VERSION ""

NS_ :

BS_:

BU_: HCM_FD IPMA_ADAS PSCM_FD ABS_ESC TCCM_FD TCM_DSL_FD PCM_HEV_FD PCM_FD ECM_Diesel GENERIC_GWMWakeup GWM_ECG _delete TSTR

BO_ 936 ParkAid_Data_FD1: 8 IPMA_ADAS
 SG_ ApaSys_D_Stat : 61|3@0+ (1,0) [0|7] "SED"  PSCM_FD,GWM_ECG,ECM_Diesel,PCM_FD,PCM_HEV_FD
 SG_ ApaSteWhl_D_RqDrv : 63|2@0+ (1,0) [0|3] "SED"  GWM_ECG
 SG_ ApaSteScanMde_D_Stat : 49|2@0+ (1,0) [0|3] "SED"  GWM_ECG
 SG_ ApaSelSapp_D_Stat : 51|2@0+ (1,0) [0|3] "SED"  GWM_ECG
 SG_ ApaSelPpa_D_Stat : 53|2@0+ (1,0) [0|3] "SED"  GWM_ECG
 SG_ ApaSelPoa_D_Stat : 55|2@0+ (1,0) [0|3] "SED"  GWM_ECG
 SG_ ApaScan_D_Stat : 41|2@0+ (1,0) [0|3] "SED"  GWM_ECG
 SG_ ApaLongCtl_D_RqDrv : 44|3@0+ (1,0) [0|7] "SED"  GWM_ECG
 SG_ ApaGearShif_D_RqDrv : 47|3@0+ (1,0) [0|7] "SED"  GWM_ECG
 SG_ ApaActvSide2_D_Stat : 33|2@0+ (1,0) [0|3] "SED"  GWM_ECG
 SG_ ApaAcsy_D_RqDrv : 36|3@0+ (1,0) [0|7] "SED"  GWM_ECG
 SG_ ApaTrgtDist_D_Stat : 11|4@0+ (1,0) [0|15] "SED"  GWM_ECG
 SG_ ApaMsgTxt_D_Rq : 15|4@0+ (1,0) [0|15] "SED"  GWM_ECG
 SG_ ApaChime_D_Rq : 39|3@0+ (1,0) [0|7] "SED"  GWM_ECG
 SG_ SAPPStatusCoding : 7|8@0+ (1,0) [0|255] "unitless"  GWM_ECG
 SG_ EPASExtAngleStatReq : 23|1@0+ (1,0) [0|1] "SED"  PSCM_FD,GWM_ECG,ABS_ESC
 SG_ ExtSteeringAngleReq2 : 22|15@0+ (0.1,-1000) [-1000|2276.5] "Degrees"  GWM_ECG,PSCM_FD

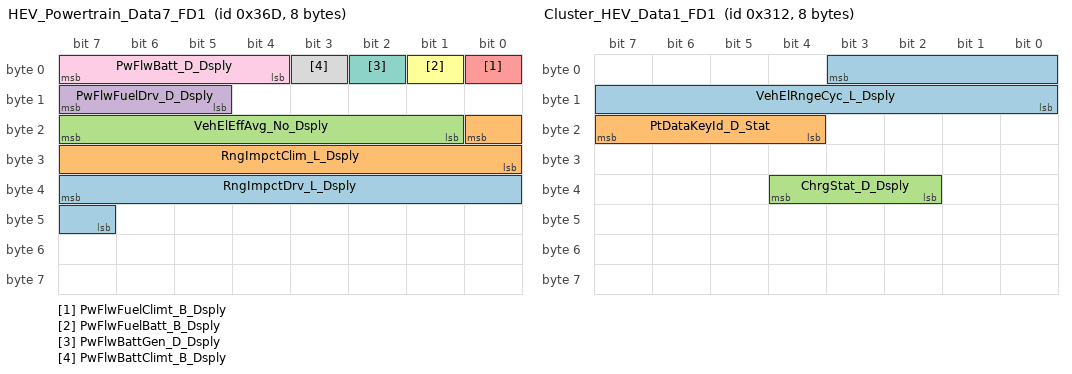
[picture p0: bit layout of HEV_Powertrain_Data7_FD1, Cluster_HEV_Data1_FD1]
BO_ 877 HEV_Powertrain_Data7_FD1: 8 PCM_HEV_FD
 SG_ RngImpctDrv_L_Dsply : 39|9@0+ (1,-255) [-255|256] "km"  GWM_ECG
 SG_ RngImpctClim_L_Dsply : 16|9@0+ (1,-255) [-255|256] "km"  GWM_ECG
 SG_ VehElEffAvg_No_Dsply : 23|7@0+ (10,-100) [-100|1150] "wattHr/km"  GWM_ECG
 SG_ PwFlwFuelDrv_D_Dsply : 15|3@0+ (1,0) [0|7] "SED"  GWM_ECG
 SG_ PwFlwFuelClimt_B_Dsply : 0|1@0+ (1,0) [0|1] "SED"  GWM_ECG
 SG_ PwFlwFuelBatt_B_Dsply : 1|1@0+ (1,0) [0|1] "SED"  GWM_ECG
 SG_ PwFlwBattGen_D_Dsply : 2|1@0+ (1,0) [0|1] "SED"  GWM_ECG
 SG_ PwFlwBattClimt_B_Dsply : 3|1@0+ (1,0) [0|1] "SED"  GWM_ECG
 SG_ PwFlwBatt_D_Dsply : 7|4@0+ (1,0) [0|15] "SED"  GWM_ECG

BO_ 786 Cluster_HEV_Data1_FD1: 8 GWM_ECG
 SG_ VehElRngeCyc_L_Dsply : 3|12@0+ (0.1,0) [0|409.3] "km" Vector__XXX
 SG_ PtDataKeyId_D_Stat : 23|4@0+ (1,0) [0|15] "SED" Vector__XXX
 SG_ ChrgStat_D_Dsply : 36|3@0+ (1,0) [0|7] "SED"  PCM_HEV_FD

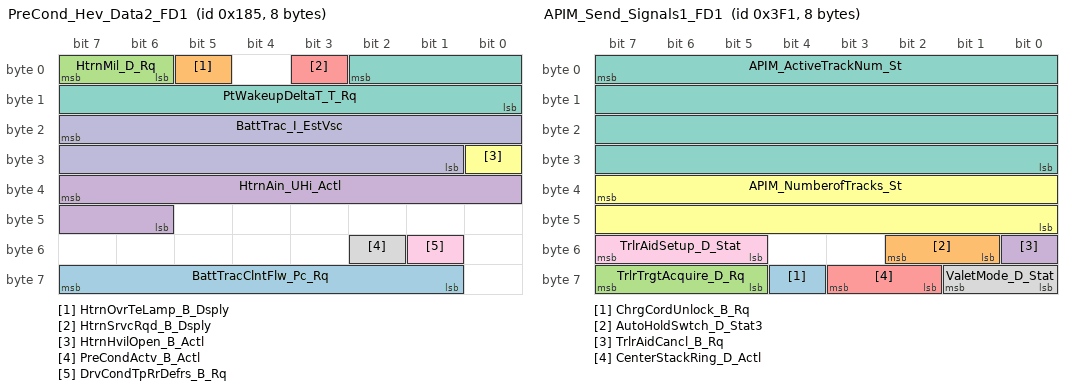
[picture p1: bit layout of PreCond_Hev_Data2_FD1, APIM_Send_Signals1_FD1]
BO_ 389 PreCond_Hev_Data2_FD1: 8 GWM_ECG
 SG_ BattTracClntFlw_Pc_Rq : 63|7@0+ (1,0) [0|127] "percent" Vector__XXX
 SG_ HtrnOvrTeLamp_B_Dsply : 5|1@0+ (1,0) [0|1] "SED" Vector__XXX
 SG_ HtrnMil_D_Rq : 7|2@0+ (1,0) [0|3] "SED" Vector__XXX
 SG_ HtrnAin_UHi_Actl : 39|10@0+ (0.5,0) [0|510.5] "volt"  PCM_HEV_FD
 SG_ HtrnSrvcRqd_B_Dsply : 3|1@0+ (1,0) [0|1] "SED" Vector__XXX
 SG_ HtrnHvilOpen_B_Actl : 24|1@0+ (1,0) [0|1] "SED"  PCM_HEV_FD
 SG_ PtWakeupDeltaT_T_Rq : 2|11@0+ (1,0) [0|2045] "minute" Vector__XXX
 SG_ PreCondActv_B_Actl : 50|1@0+ (1,0) [0|1] "SED" Vector__XXX
 SG_ DrvCondTpRrDefrs_B_Rq : 49|1@0+ (1,0) [0|1] "SED" Vector__XXX
 SG_ BattTrac_I_EstVsc : 23|15@0+ (0.05,-750) [-750|888.25] "Amps" Vector__XXX

BO_ 1009 APIM_Send_Signals1_FD1: 8 GWM_ECG
 SG_ ChrgCordUnlock_B_Rq : 60|1@0+ (1,0) [0|1] "SED" Vector__XXX
 SG_ AutoHoldSwtch_D_Stat3 : 50|2@0+ (1,0) [0|3] "SED" Vector__XXX
 SG_ TrlrTrgtAcquire_D_Rq : 63|3@0+ (1,0) [0|7] "SED"  IPMA_ADAS
 SG_ TrlrAidCancl_B_Rq : 48|1@0+ (1,0) [0|1] "SED"  IPMA_ADAS,PSCM_FD
 SG_ CenterStackRing_D_Actl : 59|2@0+ (1,0) [0|3] "SED" Vector__XXX
 SG_ APIM_NumberofTracks_St : 39|16@0+ (1,0) [0|65535] "unitless" Vector__XXX
 SG_ APIM_ActiveTrackNum_St : 7|32@0+ (1,0) [0|4294967295] "unitless" Vector__XXX
 SG_ ValetMode_D_Stat : 57|2@0+ (1,0) [0|3] "SED" Vector__XXX
 SG_ TrlrAidSetup_D_Stat : 55|3@0+ (1,0) [0|7] "SED" Vector__XXX

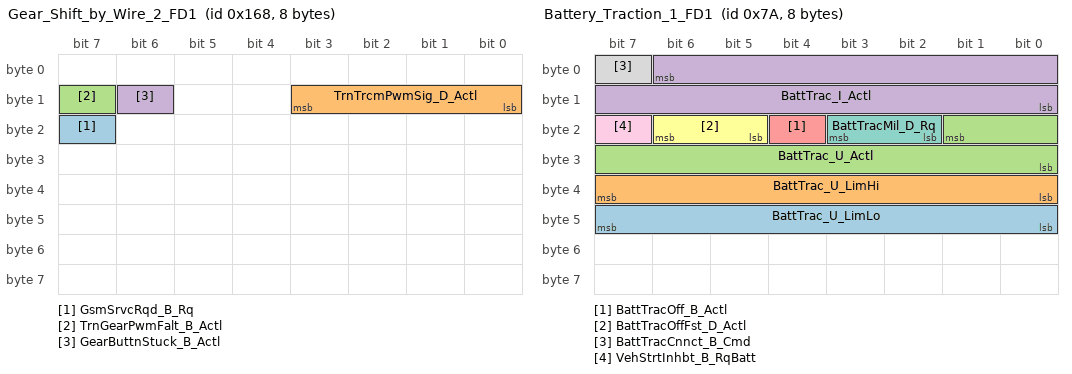
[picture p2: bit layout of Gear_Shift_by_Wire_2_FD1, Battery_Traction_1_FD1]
BO_ 360 Gear_Shift_by_Wire_2_FD1: 8 GWM_ECG
 SG_ GsmSrvcRqd_B_Rq : 23|1@0+ (1,0) [0|1] "SED" Vector__XXX
 SG_ TrnTrcmPwmSig_D_Actl : 11|4@0+ (1,0) [0|15] "SED" Vector__XXX
 SG_ TrnGearPwmFalt_B_Actl : 15|1@0+ (1,0) [0|1] "SED"  PCM_FD,PCM_HEV_FD
 SG_ GearButtnStuck_B_Actl : 14|1@0+ (1,0) [0|1] "SED"  PCM_FD,PCM_HEV_FD,TCM_DSL_FD

BO_ 122 Battery_Traction_1_FD1: 8 GWM_ECG
 SG_ BattTrac_U_LimLo : 47|8@0+ (2,0) [0|510] "volt"  PCM_HEV_FD
 SG_ BattTrac_U_LimHi : 39|8@0+ (2,0) [0|510] "volt"  PCM_HEV_FD
 SG_ BattTrac_U_Actl : 17|10@0+ (0.5,0) [0|510.5] "Volts"  PCM_HEV_FD
 SG_ BattTrac_I_Actl : 6|15@0+ (0.05,-750) [-750|888.25] "Amps"  PCM_HEV_FD
 SG_ BattTracOff_B_Actl : 20|1@0+ (1,0) [0|1] "SED"  PCM_HEV_FD
 SG_ BattTracOffFst_D_Actl : 22|2@0+ (1,0) [0|3] "SED"  PCM_HEV_FD
 SG_ BattTracMil_D_Rq : 19|2@0+ (1,0) [0|3] "SED" Vector__XXX
 SG_ BattTracCnnct_B_Cmd : 7|1@0+ (1,0) [0|1] "SED" Vector__XXX
 SG_ VehStrtInhbt_B_RqBatt : 23|1@0+ (1,0) [0|1] "SED"  PCM_HEV_FD

BO_ 90 Gear_Shift_by_Wire_FD1: 8 GWM_ECG
 SG_ TrnGsmNtmState_D_Actl : 55|2@0+ (1,0) [0|3] "SED"  ABS_ESC,PCM_FD,PCM_HEV_FD,TCM_DSL_FD
 SG_ DrQltyDrv_D_StatGsm : 42|3@0+ (1,0) [0|7] "SED"  ABS_ESC,PCM_FD,PCM_HEV_FD,TCM_DSL_FD,IPMA_ADAS
 SG_ TrnBtsiOvrrd_B_Stat : 43|1@0+ (1,0) [0|1] "SED"  PCM_FD,PCM_HEV_FD,TCM_DSL_FD
 SG_ GsmGearMsgTxt_D_Rq : 63|2@0+ (1,0) [0|3] "SED" Vector__XXX
 SG_ TrnRng_D_RqGsm : 51|4@0+ (1,0) [0|15] "SED"  PCM_FD,TCM_DSL_FD
 SG_ PrkBrkActv_D_RqGsmGear : 53|2@0+ (1,0) [0|3] "SED"  ABS_ESC
 SG_ TrnValidGearRq_D_Stat : 25|2@0+ (1,0) [0|3] "SED"  PCM_FD,PCM_HEV_FD,TCM_DSL_FD
 SG_ TrnGearRqCnt_B_Actl : 26|1@0+ (1,0) [0|1] "unitless"  PCM_FD,PCM_HEV_FD,TCM_DSL_FD
 SG_ TrnGearButtn_U_Actl : 23|8@0+ (0.05,0) [0|12.7] "VOLT"  TCM_DSL_FD
 SG_ TrnGearButtn_B_ActlR2 : 8|1@0+ (1,0) [0|1] "SED"  PCM_FD,PCM_HEV_FD,TCM_DSL_FD
 SG_ TrnGearButtn_B_ActlR1 : 9|1@0+ (1,0) [0|1] "SED"  PCM_FD,PCM_HEV_FD,TCM_DSL_FD
 SG_ TrnGearButtn_B_ActlR0 : 10|1@0+ (1,0) [0|1] "SED"  PCM_FD,PCM_HEV_FD,TCM_DSL_FD
 SG_ TrnGearButtn_B_ActlP2 : 11|1@0+ (1,0) [0|1] "SED"  TCM_DSL_FD,PCM_FD,PCM_HEV_FD
 SG_ TrnGearButtn_B_ActlP1 : 12|1@0+ (1,0) [0|1] "SED"  PCM_FD,PCM_HEV_FD,TCM_DSL_FD
 SG_ TrnGearButtn_B_ActlP0 : 13|1@0+ (1,0) [0|1] "SED"  PCM_FD,PCM_HEV_FD,TCM_DSL_FD
 SG_ TrnGearButtn_B_ActlN2 : 14|1@0+ (1,0) [0|1] "SED"  PCM_FD,PCM_HEV_FD,TCM_DSL_FD
 SG_ TrnGearButtn_B_ActlN1 : 15|1@0+ (1,0) [0|1] "SED"  PCM_FD,PCM_HEV_FD,TCM_DSL_FD
 SG_ TrnGearButtn_B_ActlN0 : 0|1@0+ (1,0) [0|1] "SED"  PCM_FD,PCM_HEV_FD,TCM_DSL_FD
 SG_ TrnGearButtn_B_ActlM2 : 1|1@0+ (1,0) [0|1] "SED"  PCM_FD,PCM_HEV_FD,TCM_DSL_FD
 SG_ TrnGearButtn_B_ActlM1 : 2|1@0+ (1,0) [0|1] "SED"  PCM_FD,PCM_HEV_FD,TCM_DSL_FD
 SG_ TrnGearButtn_B_ActlM0 : 3|1@0+ (1,0) [0|1] "SED"  PCM_FD,PCM_HEV_FD,TCM_DSL_FD
 SG_ TrnGearButtn_B_ActlD2 : 4|1@0+ (1,0) [0|1] "SED"  PCM_FD,PCM_HEV_FD,TCM_DSL_FD
 SG_ TrnGearButtn_B_ActlD1 : 5|1@0+ (1,0) [0|1] "SED"  PCM_FD,PCM_HEV_FD,TCM_DSL_FD
 SG_ TrnGearButtn_B_ActlD0 : 6|1@0+ (1,0) [0|1] "SED"  PCM_FD,PCM_HEV_FD,TCM_DSL_FD
 SG_ TrnGear_No_Cs : 39|8@0+ (1,0) [0|255] "Unitless"  PCM_FD,PCM_HEV_FD,TCM_DSL_FD
 SG_ TrnGear_No_Cnt : 47|4@0+ (1,0) [0|15] "Unitless"  PCM_FD,PCM_HEV_FD,TCM_DSL_FD
 SG_ TrnGear_D_RqDrv : 31|5@0+ (1,0) [0|31] "SED"  PCM_FD,PCM_HEV_FD,TCM_DSL_FD
 SG_ BrkSwtchPos_B_ActlGsm : 7|1@0+ (1,0) [0|1] "SED"  PCM_FD,PCM_HEV_FD,TCM_DSL_FD

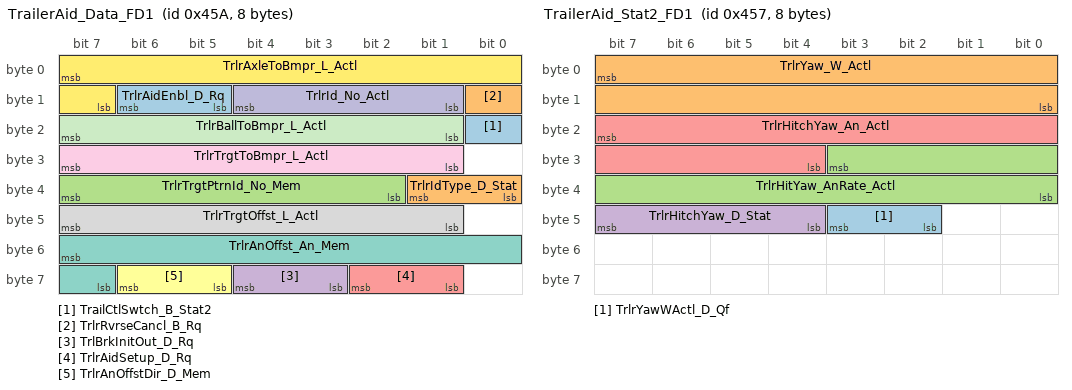
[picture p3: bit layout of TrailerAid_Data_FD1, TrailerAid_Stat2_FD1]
BO_ 1114 TrailerAid_Data_FD1: 8 GWM_ECG
 SG_ TrailCtlSwtch_B_Stat2 : 16|1@0+ (1,0) [0|1] "SED"  ABS_ESC
 SG_ TrlrRvrseCancl_B_Rq : 8|1@0+ (1,0) [0|1] "SED"  PSCM_FD,IPMA_ADAS
 SG_ TrlrTrgtPtrnId_No_Mem : 39|6@0+ (1,0) [0|63] "unitless"  IPMA_ADAS
 SG_ TrlBrkInitOut_D_Rq : 60|2@0+ (1,0) [0|3] "SED" Vector__XXX
 SG_ TrlrAidSetup_D_Rq : 58|2@0+ (1,0) [0|3] "SED"  IPMA_ADAS
 SG_ TrlrAnOffstDir_D_Mem : 62|2@0+ (1,0) [0|3] "SED"  IPMA_ADAS,PSCM_FD
 SG_ TrlrAnOffst_An_Mem : 55|9@0+ (0.1,0) [0|51.1] "degrees"  IPMA_ADAS
 SG_ TrlrTrgtOffst_L_Actl : 47|7@0+ (0.0127,0) [0|1.6129] "meter"  IPMA_ADAS
 SG_ TrlrTrgtToBmpr_L_Actl : 31|7@0+ (0.0127,0) [0|1.6129] "meter"  IPMA_ADAS
 SG_ TrlrId_No_Actl : 12|4@0+ (1,0) [0|15] "unitless"  IPMA_ADAS,PSCM_FD
 SG_ TrlrBallToBmpr_L_Actl : 23|7@0+ (0.0127,0) [0|1.6129] "meter"  IPMA_ADAS
 SG_ TrlrAxleToBmpr_L_Actl : 7|9@0+ (0.0254,0) [0|12.9794] "meter"  IPMA_ADAS,PSCM_FD
 SG_ TrlrAidEnbl_D_Rq : 14|2@0+ (1,0) [0|3] "SED"  IPMA_ADAS
 SG_ TrlrIdType_D_Stat : 33|2@0+ (1,0) [0|3] "SED"  IPMA_ADAS,PSCM_FD

BO_ 1111 TrailerAid_Stat2_FD1: 8 GWM_ECG
 SG_ TrlrYawWActl_D_Qf : 43|2@0+ (1,0) [0|3] "SED"  IPMA_ADAS,PSCM_FD
 SG_ TrlrYaw_W_Actl : 7|16@0+ (0.0002,-6.5) [-6.5|6.6066] "radians/second"  IPMA_ADAS,PSCM_FD
 SG_ TrlrHitYaw_AnRate_Actl : 27|12@0+ (0.1,-50) [-50|359.3] "degrees/second"  IPMA_ADAS,PSCM_FD
 SG_ TrlrHitchYaw_D_Stat : 47|4@0+ (1,0) [0|15] "SED"  IPMA_ADAS,PSCM_FD
 SG_ TrlrHitchYaw_An_Actl : 23|12@0+ (0.1,-90) [-90|319.3] "degrees"  IPMA_ADAS,PSCM_FD

BO_ 1106 TrailerAid_Stat1_FD1: 8 GWM_ECG
 SG_ TrlrSnsId_No_Actl : 7|48@0+ (1,0) [0|281474976710650] "unitless"  PSCM_FD

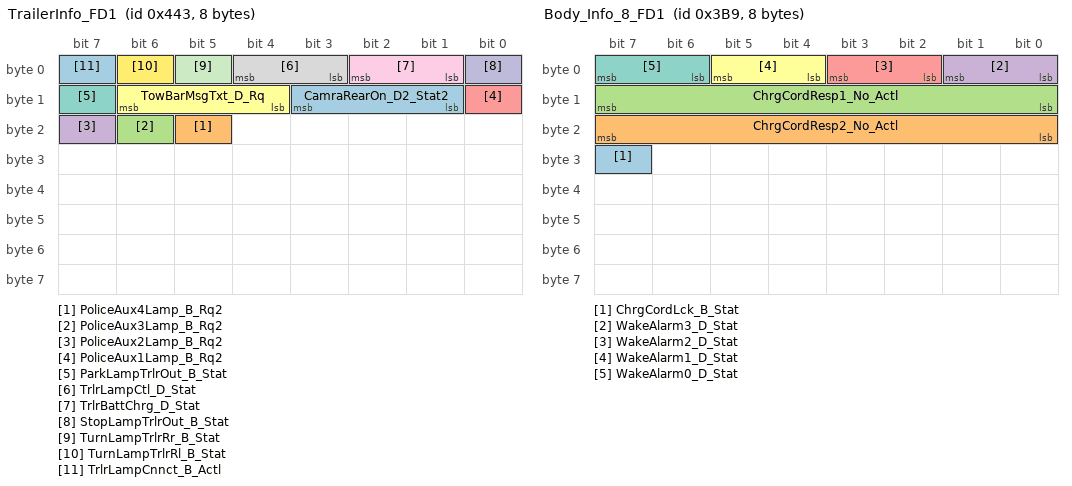
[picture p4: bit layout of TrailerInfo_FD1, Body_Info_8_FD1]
BO_ 1091 TrailerInfo_FD1: 8 GWM_ECG
 SG_ CamraRearOn_D2_Stat2 : 11|3@0+ (1,0) [0|7] "SED" Vector__XXX
 SG_ PoliceAux4Lamp_B_Rq2 : 21|1@0+ (1,0) [0|1] "SED" Vector__XXX
 SG_ PoliceAux3Lamp_B_Rq2 : 22|1@0+ (1,0) [0|1] "SED" Vector__XXX
 SG_ PoliceAux2Lamp_B_Rq2 : 23|1@0+ (1,0) [0|1] "SED" Vector__XXX
 SG_ PoliceAux1Lamp_B_Rq2 : 8|1@0+ (1,0) [0|1] "SED" Vector__XXX
 SG_ TowBarMsgTxt_D_Rq : 14|3@0+ (1,0) [0|7] "SED" Vector__XXX
 SG_ ParkLampTrlrOut_B_Stat : 15|1@0+ (1,0) [0|1] "SED" Vector__XXX
 SG_ TrlrLampCtl_D_Stat : 4|2@0+ (1,0) [0|3] "SED" Vector__XXX
 SG_ TrlrBattChrg_D_Stat : 2|2@0+ (1,0) [0|3] "SED" Vector__XXX
 SG_ StopLampTrlrOut_B_Stat : 0|1@0+ (1,0) [0|1] "SED" Vector__XXX
 SG_ TurnLampTrlrRr_B_Stat : 5|1@0+ (1,0) [0|1] "SED" Vector__XXX
 SG_ TurnLampTrlrRl_B_Stat : 6|1@0+ (1,0) [0|1] "SED" Vector__XXX
 SG_ TrlrLampCnnct_B_Actl : 7|1@0+ (1,0) [0|1] "SED"  PSCM_FD,ECM_Diesel,PCM_FD,TCM_DSL_FD,ABS_ESC,IPMA_ADAS

BO_ 138 ActiveFrontStrg_Stat2_FD1: 8 GWM_ECG
 SG_ SteWhlRelCalib_T_Actl : 7|8@0+ (1,0) [0|255] "ms"  ABS_ESC
 SG_ SteWhlRelCalib_An_Sns : 15|15@0+ (0.1,-1600) [-1600|1676.5] "deg"  TCCM_FD,PSCM_FD

BO_ 131 Steering_Data_FD1: 8 GWM_ECG
 SG_ TjaButtnOnOffPress : 40|1@0+ (1,0) [0|1] "SED" Vector__XXX
 SG_ AccButtnGapDecPress : 12|1@0+ (1,0) [0|1] "SED" Vector__XXX
 SG_ HeadLghtHiCtrl_D_RqAhb : 43|3@0+ (1,0) [0|7] "SED"  HCM_FD
 SG_ AhbStat_B_Dsply : 33|1@0+ (1,0) [0|1] "SED" Vector__XXX
 SG_ WiprFrontSwtch_D_Stat : 47|4@0+ (1,0) [0|15] "SED" Vector__XXX
 SG_ HeadLghtHiOn_B_StatAhb : 34|1@0+ (1,0) [0|1] "SED"  IPMA_ADAS
 SG_ HeadLghtHiFlash_D_Actl : 36|2@0+ (1,0) [0|3] "SED"  IPMA_ADAS
 SG_ AccButtnGapTogglePress : 32|1@0+ (1,0) [0|1] "SED"  IPMA_ADAS
 SG_ HeadLghtHiFlash_D_Stat : 7|2@0+ (1,0) [0|3] "SED"  IPMA_ADAS
 SG_ WiprFront_D_Stat : 3|4@0+ (1,0) [0|15] "SED"  HCM_FD,ABS_ESC,IPMA_ADAS,PCM_FD,PCM_HEV_FD
 SG_ TurnLghtSwtch_D_Stat : 5|2@0+ (1,0) [0|3] "SED"  HCM_FD,IPMA_ADAS,PSCM_FD
 SG_ LghtAmb_D_Sns : 15|3@0+ (1,0) [0|7] "SED"  HCM_FD,IPMA_ADAS
 SG_ AccButtnGapIncPress : 11|1@0+ (1,0) [0|1] "SED"  IPMA_ADAS
 SG_ AslButtnOnOffPress : 9|1@0+ (1,0) [0|1] "SED"  ECM_Diesel,PCM_FD,PCM_HEV_FD
 SG_ AslButtnOnOffCnclPress : 10|1@0+ (1,0) [0|1] "SED"  ECM_Diesel,PCM_FD,PCM_HEV_FD
 SG_ CcButtnOnPress : 37|1@0+ (1,0) [0|1] "SED"  ECM_Diesel,IPMA_ADAS,PCM_FD,PCM_HEV_FD
 SG_ CcButtnOnOffPress : 38|1@0+ (1,0) [0|1] "SED"  ECM_Diesel,IPMA_ADAS,PCM_FD,PCM_HEV_FD
 SG_ CcButtnOnOffCnclPress : 39|1@0+ (1,0) [0|1] "SED"  ECM_Diesel,IPMA_ADAS,PCM_FD,PCM_HEV_FD
 SG_ CcButtnOffPress : 24|1@0+ (1,0) [0|1] "SED"  ECM_Diesel,IPMA_ADAS,PCM_FD,PCM_HEV_FD
 SG_ CcAsllButtnResPress : 25|1@0+ (1,0) [0|1] "SED"  ECM_Diesel,IPMA_ADAS,PCM_FD,PCM_HEV_FD
 SG_ CcAslButtnSetPress : 26|1@0+ (1,0) [0|1] "SED" Vector__XXX
 SG_ CcAslButtnSetIncPress : 27|1@0+ (1,0) [0|1] "SED"  ABS_ESC,ECM_Diesel,IPMA_ADAS,PCM_FD,PCM_HEV_FD
 SG_ CcAslButtnSetDecPress : 28|1@0+ (1,0) [0|1] "SED"  ABS_ESC,ECM_Diesel,IPMA_ADAS,PCM_FD,PCM_HEV_FD
 SG_ CcAslButtnResIncPress : 29|1@0+ (1,0) [0|1] "SED"  ABS_ESC,ECM_Diesel,IPMA_ADAS,PCM_FD,PCM_HEV_FD
 SG_ CcAslButtnResDecPress : 30|1@0+ (1,0) [0|1] "SED" Vector__XXX
 SG_ CcAslButtnOnPress : 31|1@0+ (1,0) [0|1] "SED"  ECM_Diesel,IPMA_ADAS,PCM_FD,PCM_HEV_FD
 SG_ CcAslButtnOnOffCncl : 16|1@0+ (1,0) [0|1] "SED" Vector__XXX
 SG_ CcAslButtnOffCnclPress : 17|1@0+ (1,0) [0|1] "SED" Vector__XXX
 SG_ CcAslButtnIndxIncPress : 18|1@0+ (1,0) [0|1] "SED"  ECM_Diesel,PCM_FD,PCM_HEV_FD
 SG_ CcAslButtnIndxDecPress : 19|1@0+ (1,0) [0|1] "SED"  ECM_Diesel,PCM_FD,PCM_HEV_FD
 SG_ CcAslButtnDeny_B_Actl : 20|1@0+ (1,0) [0|1] "SED"  ECM_Diesel,IPMA_ADAS,PCM_FD,PCM_HEV_FD
 SG_ CcAslButtnCnclResPress : 21|1@0+ (1,0) [0|1] "SED"  ECM_Diesel,IPMA_ADAS,PCM_FD,PCM_HEV_FD
 SG_ CcAslButtnCnclPress : 8|1@0+ (1,0) [0|1] "SED"  ECM_Diesel,IPMA_ADAS,PCM_FD,PCM_HEV_FD
 SG_ LaSwtchPos_D_Stat : 23|2@0+ (1,0) [0|3] "SED"  IPMA_ADAS

BO_ 953 Body_Info_8_FD1: 8 GWM_ECG
 SG_ ChrgCordLck_B_Stat : 31|1@0+ (1,0) [0|1] "SED" Vector__XXX
 SG_ ChrgCordResp2_No_Actl : 23|8@0+ (1,0) [0|255] "unitless" Vector__XXX
 SG_ ChrgCordResp1_No_Actl : 15|8@0+ (1,0) [0|255] "unitless" Vector__XXX
 SG_ WakeAlarm3_D_Stat : 1|2@0+ (1,0) [0|3] "SED" Vector__XXX
 SG_ WakeAlarm2_D_Stat : 3|2@0+ (1,0) [0|3] "SED" Vector__XXX
 SG_ WakeAlarm1_D_Stat : 5|2@0+ (1,0) [0|3] "SED"  ECM_Diesel,PCM_HEV_FD
 SG_ WakeAlarm0_D_Stat : 7|2@0+ (1,0) [0|3] "SED" Vector__XXX

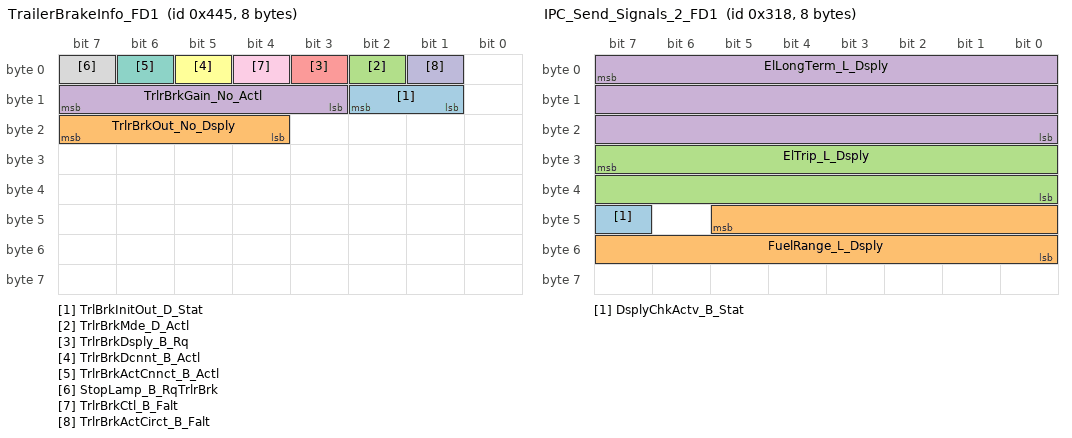
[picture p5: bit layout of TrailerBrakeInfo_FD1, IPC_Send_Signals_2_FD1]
BO_ 1093 TrailerBrakeInfo_FD1: 8 GWM_ECG
 SG_ TrlBrkInitOut_D_Stat : 10|2@0+ (1,0) [0|3] "SED" Vector__XXX
 SG_ TrlrBrkOut_No_Dsply : 23|4@0+ (1,0) [0|15] "unitless" Vector__XXX
 SG_ TrlrBrkMde_D_Actl : 2|1@0+ (1,0) [0|1] "SED" Vector__XXX
 SG_ TrlrBrkGain_No_Actl : 15|5@0+ (0.5,0) [0|15.5] "unitless" Vector__XXX
 SG_ TrlrBrkDsply_B_Rq : 3|1@0+ (1,0) [0|1] "SED" Vector__XXX
 SG_ TrlrBrkDcnnt_B_Actl : 5|1@0+ (1,0) [0|1] "SED" Vector__XXX
 SG_ TrlrBrkActCnnct_B_Actl : 6|1@0+ (1,0) [0|1] "SED"  PSCM_FD,ECM_Diesel,PCM_FD,TCM_DSL_FD,ABS_ESC,TCCM_FD
 SG_ StopLamp_B_RqTrlrBrk : 7|1@0+ (1,0) [0|1] "SED" Vector__XXX
 SG_ TrlrBrkCtl_B_Falt : 4|1@0+ (1,0) [0|1] "SED"  IPMA_ADAS
 SG_ TrlrBrkActCirct_B_Falt : 1|1@0+ (1,0) [0|1] "SED"  IPMA_ADAS

BO_ 792 IPC_Send_Signals_2_FD1: 8 GWM_ECG
 SG_ DsplyChkActv_B_Stat : 47|1@0+ (1,0) [0|1] "SED" Vector__XXX
 SG_ FuelRange_L_Dsply : 45|14@0+ (0.1,0) [0|1638.3] "km"  ECM_Diesel
 SG_ ElTrip_L_Dsply : 31|16@0+ (0.1,0) [0|6553.3] "unitless" Vector__XXX
 SG_ ElLongTerm_L_Dsply : 7|24@0+ (0.1,0) [0|1677721.3] "unitless" Vector__XXX

BO_ 968 Cluster_Lighting_Rq_FD1: 8 GWM_ECG
 SG_ RvltnMatchAllw_D_Rq : 58|2@0+ (1,0) [0|3] "SED" Vector__XXX
 SG_ BrkDrvMde_D_Rq : 18|3@0+ (1,0) [0|7] "SED" Vector__XXX
 SG_ LnchCtl_N_Rq : 55|8@0+ (50,0) [0|12750] "rpm" Vector__XXX
 SG_ LnchCtl_D_Rq : 63|2@0+ (1,0) [0|3] "SED" Vector__XXX
 SG_ CurrentColor_CmdGage : 43|4@0+ (1,0) [0|15] "SED" Vector__XXX
 SG_ BlendedColor_CmdGage : 25|2@0+ (1,0) [0|3] "SED" Vector__XXX
 SG_ BlendColorRed_CmdGage : 47|4@0+ (1,0) [0|15] "SED" Vector__XXX
 SG_ BlendColorGrn_CmdGage : 35|4@0+ (1,0) [0|15] "SED" Vector__XXX
 SG_ BlendColorBlue_CmdGage : 39|4@0+ (1,0) [0|15] "SED" Vector__XXX
 SG_ Dimming_Level_Cmd : 1|2@0+ (1,0) [0|3] "SED" Vector__XXX
 SG_ Current_Color_Cmd : 23|4@0+ (1,0) [0|15] "SED" Vector__XXX
 SG_ BlendedColorRed_Cmd : 11|4@0+ (1,0) [0|15] "SED" Vector__XXX
 SG_ BlendedColorGreen_Cmd : 15|4@0+ (1,0) [0|15] "SED" Vector__XXX
 SG_ BlendedColorBlue_Cmd : 5|4@0+ (1,0) [0|15] "SED" Vector__XXX
 SG_ BlendedColor_Cmd : 7|2@0+ (1,0) [0|3] "SED" Vector__XXX
 SG_ SuspDrvMde_D_Rq : 61|3@0+ (1,0) [0|7] "SED" Vector__XXX
 SG_ SlMde_D_Rq : 27|2@0+ (1,0) [0|3] "SED"  ECM_Diesel
 SG_ IsaOffst_D_Rq : 31|4@0+ (1,0) [0|15] "SED"  ECM_Diesel

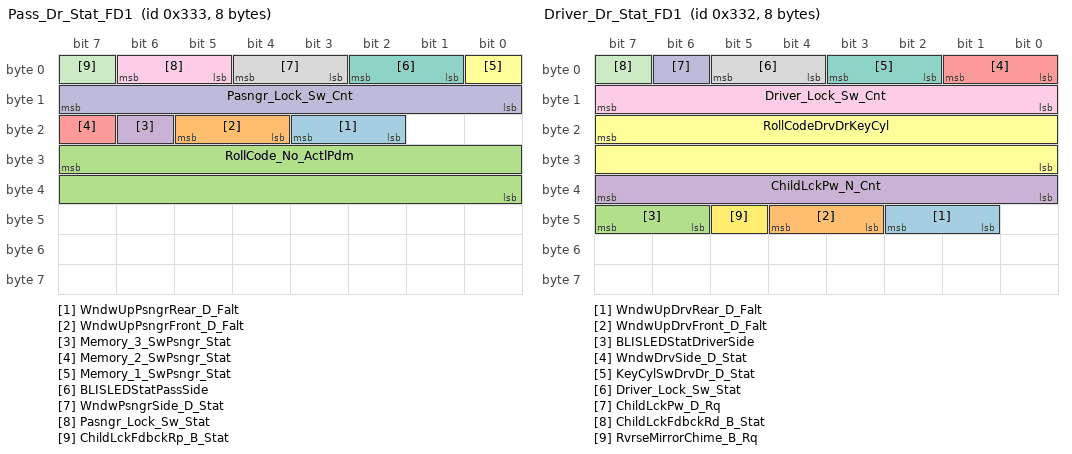
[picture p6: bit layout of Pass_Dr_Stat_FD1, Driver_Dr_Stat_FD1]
BO_ 819 Pass_Dr_Stat_FD1: 8 GWM_ECG
 SG_ WndwUpPsngrRear_D_Falt : 19|2@0+ (1,0) [0|3] "SED" Vector__XXX
 SG_ WndwUpPsngrFront_D_Falt : 21|2@0+ (1,0) [0|3] "SED" Vector__XXX
 SG_ RollCode_No_ActlPdm : 31|16@0+ (1,0) [0|65535] "Unitless" Vector__XXX
 SG_ Memory_3_SwPsngr_Stat : 22|1@0+ (1,0) [0|1] "SED" Vector__XXX
 SG_ Memory_2_SwPsngr_Stat : 23|1@0+ (1,0) [0|1] "SED" Vector__XXX
 SG_ Memory_1_SwPsngr_Stat : 0|1@0+ (1,0) [0|1] "SED" Vector__XXX
 SG_ BLISLEDStatPassSide : 2|2@0+ (1,0) [0|3] "SED" Vector__XXX
 SG_ WndwPsngrSide_D_Stat : 4|2@0+ (1,0) [0|3] "SED"  ECM_Diesel,PCM_FD
 SG_ Pasngr_Lock_Sw_Stat : 6|2@0+ (1,0) [0|3] "SED" Vector__XXX
 SG_ Pasngr_Lock_Sw_Cnt : 15|8@0+ (1,0) [0|255] "Cnt" Vector__XXX
 SG_ ChildLckFdbckRp_B_Stat : 7|1@0+ (1,0) [0|1] "SED" Vector__XXX

BO_ 818 Driver_Dr_Stat_FD1: 8 GWM_ECG
 SG_ WndwUpDrvRear_D_Falt : 42|2@0+ (1,0) [0|3] "SED" Vector__XXX
 SG_ WndwUpDrvFront_D_Falt : 44|2@0+ (1,0) [0|3] "SED" Vector__XXX
 SG_ BLISLEDStatDriverSide : 47|2@0+ (1,0) [0|3] "SED" Vector__XXX
 SG_ ChildLckPw_N_Cnt : 39|8@0+ (1,0) [0|255] "unitless" Vector__XXX
 SG_ WndwDrvSide_D_Stat : 1|2@0+ (1,0) [0|3] "SED"  ECM_Diesel,PCM_FD
 SG_ RollCodeDrvDrKeyCyl : 23|16@0+ (1,0) [0|65535] "Unitless" Vector__XXX
 SG_ KeyCylSwDrvDr_D_Stat : 3|2@0+ (1,0) [0|3] "SED" Vector__XXX
 SG_ Driver_Lock_Sw_Stat : 5|2@0+ (1,0) [0|3] "SED" Vector__XXX
 SG_ Driver_Lock_Sw_Cnt : 15|8@0+ (1,0) [0|255] "Cnt" Vector__XXX
 SG_ ChildLckPw_D_Rq : 6|1@0+ (1,0) [0|1] "SED" Vector__XXX
 SG_ ChildLckFdbckRd_B_Stat : 7|1@0+ (1,0) [0|1] "SED" Vector__XXX
 SG_ RvrseMirrorChime_B_Rq : 45|1@0+ (1,0) [0|1] "SED" Vector__XXX

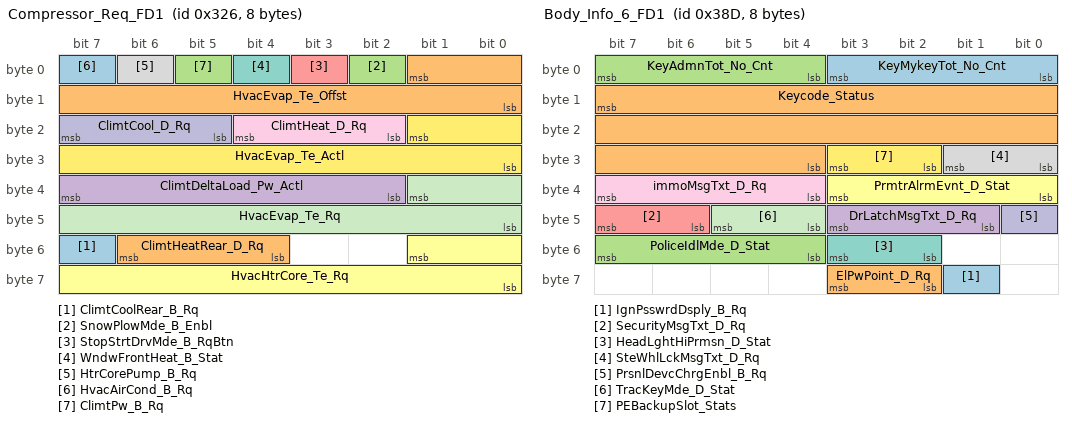
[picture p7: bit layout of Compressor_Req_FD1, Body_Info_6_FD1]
BO_ 806 Compressor_Req_FD1: 8 GWM_ECG
 SG_ ClimtCoolRear_B_Rq : 55|1@0+ (1,0) [0|1] "SED" Vector__XXX
 SG_ ClimtHeatRear_D_Rq : 54|3@0+ (1,0) [0|7] "SED" Vector__XXX
 SG_ SnowPlowMde_B_Enbl : 2|1@0+ (1,0) [0|1] "SED" Vector__XXX
 SG_ ClimtDeltaLoad_Pw_Actl : 39|6@0+ (50,-1600) [-1600|1450] "watts" Vector__XXX
 SG_ StopStrtDrvMde_B_RqBtn : 3|1@0+ (1,0) [0|1] "SED"  ECM_Diesel,PCM_FD
 SG_ HvacHtrCore_Te_Rq : 49|10@0+ (0.25,-50) [-50|205.75] "degC"  ECM_Diesel
 SG_ WndwFrontHeat_B_Stat : 4|1@0+ (1,0) [0|1] "SED"  IPMA_ADAS
 SG_ HtrCorePump_B_Rq : 6|1@0+ (1,0) [0|1] "SED" Vector__XXX
 SG_ ClimtHeat_D_Rq : 20|3@0+ (1,0) [0|7] "SED"  ECM_Diesel,PCM_FD,PCM_HEV_FD
 SG_ ClimtCool_D_Rq : 23|3@0+ (1,0) [0|7] "SED"  ECM_Diesel,PCM_FD,PCM_HEV_FD
 SG_ HvacEvap_Te_Rq : 33|10@0+ (0.125,-50) [-50|77.875] "Degrees C"  ECM_Diesel,PCM_FD,PCM_HEV_FD
 SG_ HvacEvap_Te_Actl : 17|10@0+ (0.125,-50) [-50|77.75] "Degrees C"  ECM_Diesel,PCM_FD,PCM_HEV_FD
 SG_ HvacAirCond_B_Rq : 7|1@0+ (1,0) [0|1] "SED"  ECM_Diesel,PCM_FD,PCM_HEV_FD
 SG_ HvacEvap_Te_Offst : 1|10@0+ (0.125,-50) [-50|77.875] "Degrees C"  ECM_Diesel,PCM_FD,PCM_HEV_FD
 SG_ ClimtPw_B_Rq : 5|1@0+ (1,0) [0|1] "SED"  ECM_Diesel,PCM_FD

BO_ 765 Mc_Send_Signals_2_FD1: 8 GWM_ECG
 SG_ BalrSwtch_D_Stat : 57|2@0+ (1,0) [0|3] "SED"  IPMA_ADAS
 SG_ BalrMde_D_Rq : 59|2@0+ (1,0) [0|3] "SED"  IPMA_ADAS
 SG_ RstrnOnPsngr_D_RqMnu : 63|4@0+ (1,0) [0|15] "SED" Vector__XXX
 SG_ WaitToStartLamp_D_Falt : 50|2@0+ (1,0) [0|3] "SED"  ECM_Diesel
 SG_ EsaOn_B_Rq : 15|1@0+ (1,0) [0|1] "SED"  PSCM_FD
 SG_ BttOn_B_Rq : 26|1@0+ (1,0) [0|1] "SED"  IPMA_ADAS
 SG_ Btt_L_Actl : 39|7@0+ (0.1,0) [0|12.5] "meter"  IPMA_ADAS
 SG_ RearDiffLck_D_RqArb : 25|2@0+ (1,0) [0|3] "SED"  TCCM_FD
 SG_ AwdMde_D_RqArb : 47|3@0+ (1,0) [0|7] "SED"  TCCM_FD
 SG_ SelDrvMdeTxtReset_B_Rq : 40|1@0+ (1,0) [0|1] "SED"  ABS_ESC
 SG_ AutoTowAllw_D_RqMnu : 52|2@0+ (1,0) [0|3] "SED" Vector__XXX
 SG_ DrvInputRequired_B_Rq : 32|1@0+ (1,0) [0|1] "SED" Vector__XXX
 SG_ SelDrvMdeDsply_B_Avail : 41|1@0+ (1,0) [0|1] "SED"  ABS_ESC
 SG_ EngExhMdeQuiet_D_Rq : 17|2@0+ (1,0) [0|3] "SED" Vector__XXX
 SG_ AirSusp_D_RqDrv : 31|2@0+ (1,0) [0|3] "SED" Vector__XXX
 SG_ Mc_VehUntTrpCoUsrSel_St : 23|1@0+ (1,0) [0|1] "SED" Vector__XXX
 SG_ Mc_VehUnitTempUsrSel_St : 22|1@0+ (1,0) [0|1] "SED" Vector__XXX
 SG_ Mc_VehDayNightUsrSel_St : 14|3@0+ (1,0) [0|7] "SED" Vector__XXX
 SG_ Mc_VehTimeFrmtUsrSel_St : 1|2@0+ (1,0) [0|3] "SED" Vector__XXX
 SG_ Mc_VehThemeUsrSel_St : 11|4@0+ (1,0) [0|15] "SED" Vector__XXX
 SG_ Mc_VehLangUsrSel_St : 7|6@0+ (1,0) [0|63] "SED" Vector__XXX
 SG_ AwdRnge_D_ActlIpc : 29|3@0+ (1,0) [0|7] "SED"  TCM_DSL_FD
 SG_ AwdDrvMde_D_Rq : 44|3@0+ (1,0) [0|7] "SED" Vector__XXX
 SG_ EngExhMdeQuiet_D2_Rq : 55|3@0+ (1,0) [0|7] "SED" Vector__XXX
 SG_ BrkLineLck_D_Rq : 19|2@0+ (1,0) [0|3] "SED" Vector__XXX
 SG_ EdmSailMde_B_RqDrv : 48|1@0+ (1,0) [0|1] "SED"  ECM_Diesel
 SG_ Running_Board_Cmd : 21|2@0+ (1,0) [0|3] "SED" Vector__XXX

BO_ 559 ElecHorizon_Data2_FD1: 8 GWM_ECG
 SG_ EhData2_No_Actl : 7|64@0+ (1,0) [0|1.844674407371E+019] "unitless"  IPMA_ADAS,ECM_Diesel

BO_ 558 ElecHorizon_Data1_FD1: 8 GWM_ECG
 SG_ EhData1_No_Actl : 7|64@0+ (1,0) [0|1.844674407371E+019] "unitless"  IPMA_ADAS,ECM_Diesel

BO_ 934 Side_Detect_L_Stat_FD1: 8 IPMA_ADAS
 SG_ RbaCtaLeft_D_Stat : 55|3@0+ (1,0) [0|7] "SED" Vector__XXX
 SG_ CtaAlrtLeft2_D_Stat : 30|3@0+ (1,0) [0|7] "SED" Vector__XXX
 SG_ CtaBrkLeftMsgTxt_B_Rq : 42|1@0+ (1,0) [0|1] "SED" Vector__XXX
 SG_ CtaLeftBrkDecel_B_Rq : 7|1@0+ (1,0) [0|1] "SED"  ABS_ESC
 SG_ CtaLeftBrkEnbl_B_Rq : 31|1@0+ (1,0) [0|1] "SED"  ABS_ESC
 SG_ Side_Detect_L_Illum : 39|8@0+ (1,0) [0|255] "Percent" Vector__XXX
 SG_ BttLeft_D_Stat : 45|3@0+ (1,0) [0|7] "SED" Vector__XXX
 SG_ BttLeft_D_RqDrv : 47|2@0+ (1,0) [0|3] "SED" Vector__XXX
 SG_ CtaInnrLeft_D_Stat : 27|2@0+ (1,0) [0|3] "SED" Vector__XXX
 SG_ LcwaLeft_D_Stat : 52|3@0+ (1,0) [0|7] "SED"  GWM_ECG
 SG_ CtaSnsLeft_D_Stat : 25|2@0+ (1,0) [0|3] "SED" Vector__XXX
 SG_ SodDetctLeft_D_Stat : 23|3@0+ (1,0) [0|7] "SED" Vector__XXX
 SG_ CtaLeft_D_Stat : 18|3@0+ (1,0) [0|7] "SED" Vector__XXX
 SG_ CtaAlrtLeft_D_Stat : 8|1@0+ (1,0) [0|1] "SED" Vector__XXX
 SG_ SodLeft_D_Stat : 15|3@0+ (1,0) [0|7] "SED" Vector__XXX
 SG_ SodSnsLeft_D_Stat : 12|2@0+ (1,0) [0|3] "SED" Vector__XXX
 SG_ SodAlrtLeft_D_Stat : 10|2@0+ (1,0) [0|3] "SED" Vector__XXX
 SG_ SodWarnLeft_Prd_Rq : 6|7@0+ (1,0) [0|127] "millisecond" Vector__XXX
 SG_ SodInnrLeft_D_Stat : 20|2@0+ (1,0) [0|3] "SED" Vector__XXX
 SG_ LcwaDetctLeft2_B_Stat : 40|1@0+ (1,0) [0|1] "SED" Vector__XXX
 SG_ LcwaDetctLeft1_B_Stat : 41|1@0+ (1,0) [0|1] "SED" Vector__XXX

BO_ 1072 Cluster_Info1_FD1: 8 GWM_ECG
 SG_ PtDrvMde_D_Rq : 61|4@0+ (1,0) [0|15] "SED" Vector__XXX
 SG_ DrvSlipCtlMde_D_Rq : 33|2@0+ (1,0) [0|3] "SED"  ABS_ESC
 SG_ EngIdlShutDown_B_RqDrv : 3|1@0+ (1,0) [0|1] "SED"  ECM_Diesel,PCM_FD,PCM_HEV_FD
 SG_ DrvPerfMde_D_Rq : 49|2@0+ (1,0) [0|3] "SED" Vector__XXX
 SG_ HsaMde_D_Rq : 54|2@0+ (1,0) [0|3] "SED" Vector__XXX
 SG_ StopStrtDrvMde_D_RqMnu : 47|2@0+ (1,0) [0|3] "SED"  ECM_Diesel,PCM_FD
 SG_ NtrlTowMdeEnbl_B_RqDrv : 1|1@0+ (1,0) [0|1] "SED"  TCCM_FD,TCM_DSL_FD,PCM_HEV_FD,PCM_FD
 SG_ LscmbbStat_B_Actl : 2|1@0+ (1,0) [0|1] "SED" Vector__XXX
 SG_ BulbChkActv_B_Stat : 55|1@0+ (1,0) [0|1] "SED" Vector__XXX
 SG_ ParkDetect_Stat : 52|1@0+ (1,0) [0|1] "SED" Vector__XXX
 SG_ ReducedGuard_D_Rq : 51|2@0+ (1,0) [0|3] "SED" Vector__XXX
 SG_ FrostWarn_D_Stat : 45|2@0+ (1,0) [0|3] "SED"  ECM_Diesel,PCM_FD
 SG_ TrlrBrkMde_D_Rq : 57|1@0+ (1,0) [0|1] "SED" Vector__XXX
 SG_ TRLR_SWAY_CONFIG_CMD : 56|1@0+ (1,0) [0|1] "SED"  ABS_ESC
 SG_ TRAILER_BRAKE_CONFIG : 37|1@0+ (1,0) [0|1] "SED" Vector__XXX
 SG_ Power_Liftgate_Mode_Cmd : 39|1@0+ (1,0) [0|1] "SED" Vector__XXX
 SG_ AccEnbl_B_RqDrv : 35|1@0+ (1,0) [0|1] "SED"  IPMA_ADAS
 SG_ EmgcyCallAsstMykey_Rq : 42|1@0+ (1,0) [0|1] "SED" Vector__XXX
 SG_ OdometerMasterValue : 15|24@0+ (1,0) [0|16777214] "km"  ABS_ESC,ECM_Diesel,IPMA_ADAS,PCM_FD,PCM_HEV_FD,PSCM_FD,TCM_DSL_FD
 SG_ EngOilLife_B_RqReset : 43|1@0+ (1,0) [0|1] "SED"  ECM_Diesel,PCM_FD,PCM_HEV_FD
 SG_ MetricActvTe_B_Actl : 38|1@0+ (1,0) [0|1] "SED" Vector__XXX
 SG_ AccDeny_B_RqIpc : 7|1@0+ (1,0) [0|1] "SED"  IPMA_ADAS
 SG_ ePRNDL_MODE : 0|1@0+ (1,0) [0|1] "SED"  PCM_FD,PCM_HEV_FD,TCM_DSL_FD
 SG_ PrkLckCtlEnbl_D_RqIpc : 63|2@0+ (1,0) [0|3] "SED" Vector__XXX
 SG_ DrvSlipCtlMde_B_Rq2 : 34|1@0+ (1,0) [0|1] "SED"  ABS_ESC
 SG_ Fda_B_Stat : 36|1@0+ (1,0) [0|1] "SED"  IPMA_ADAS
 SG_ MetricActv_B_Actl : 6|1@0+ (1,0) [0|1] "SED"  ECM_Diesel,IPMA_ADAS,PCM_FD,PCM_HEV_FD
 SG_ KeyTypeChngMykey_D_Rq : 41|2@0+ (1,0) [0|3] "SED" Vector__XXX
 SG_ ManRgen_D_Rq : 5|2@0+ (1,0) [0|3] "SED"  ECM_Diesel

BO_ 909 Body_Info_6_FD1: 8 GWM_ECG
 SG_ IgnPsswrdDsply_B_Rq : 57|1@0+ (1,0) [0|1] "SED" Vector__XXX
 SG_ ElPwPoint_D_Rq : 59|2@0+ (1,0) [0|3] "SED" Vector__XXX
 SG_ PoliceIdlMde_D_Stat : 55|4@0+ (1,0) [0|15] "SED" Vector__XXX
 SG_ DrLatchMsgTxt_D_Rq : 43|3@0+ (1,0) [0|7] "SED" Vector__XXX
 SG_ SecurityMsgTxt_D_Rq : 47|2@0+ (1,0) [0|3] "SED" Vector__XXX
 SG_ PrmtrAlrmEvnt_D_Stat : 35|4@0+ (1,0) [0|15] "SED" Vector__XXX
 SG_ HeadLghtHiPrmsn_D_Stat : 51|2@0+ (1,0) [0|3] "SED"  HCM_FD,IPMA_ADAS
 SG_ SteWhlLckMsgTxt_D_Rq : 25|2@0+ (1,0) [0|3] "SED" Vector__XXX
 SG_ immoMsgTxt_D_Rq : 39|4@0+ (1,0) [0|15] "SED" Vector__XXX
 SG_ PrsnlDevcChrgEnbl_B_Rq : 40|1@0+ (1,0) [0|1] "SED" Vector__XXX
 SG_ TracKeyMde_D_Stat : 45|2@0+ (1,0) [0|3] "SED" Vector__XXX
 SG_ PEBackupSlot_Stats : 27|2@0+ (1,0) [0|3] "SED" Vector__XXX
 SG_ KeyMykeyTot_No_Cnt : 3|4@0+ (1,0) [0|15] "Counts" Vector__XXX
 SG_ Keycode_Status : 15|20@0+ (1,0) [0|1048575] "unitless" Vector__XXX
 SG_ KeyAdmnTot_No_Cnt : 7|4@0+ (1,0) [0|15] "Counts" Vector__XXX

BO_ 963 BCM_Lamp_Stat_FD1: 8 GWM_ECG
 SG_ Illuminated_Entry_Stat : 63|2@0+ (1,0) [0|3] "SED" Vector__XXX
 SG_ Dr_Courtesy_Light_Stat : 49|2@0+ (1,0) [0|3] "SED" Vector__XXX
 SG_ Courtesy_Delay_Status : 51|2@0+ (1,0) [0|3] "SED" Vector__XXX
 SG_ ImpactEvntFdbck_D_Stat : 53|2@0+ (1,0) [0|3] "SED" Vector__XXX
 SG_ WrlssAcsyChrgInhbt_B_Rq : 40|1@0+ (1,0) [0|1] "SED" Vector__XXX
 SG_ PudLampPsngr_D_Rq : 57|2@0+ (1,0) [0|3] "SED" Vector__XXX
 SG_ HeadLampLoOut_B_Stat : 32|1@0+ (1,0) [0|1] "SED" Vector__XXX
 SG_ CrnrLghtRight_Pc_Rq : 47|7@0+ (1,0) [0|100] "percent"  HCM_FD
 SG_ CrnrLghtLeft_Pc_Rq : 39|7@0+ (1,0) [0|100] "percent"  HCM_FD
 SG_ HeadLghtHiFdbck_D_Stat : 55|2@0+ (1,0) [0|3] "SED" Vector__XXX
 SG_ PudLampDrv_D_Rq : 59|2@0+ (1,0) [0|3] "SED" Vector__XXX
 SG_ TrnNotInPrkChime_B_Rq : 24|1@0+ (1,0) [0|1] "SED" Vector__XXX
 SG_ PrkLightChime_B_Rq : 25|1@0+ (1,0) [0|1] "SED" Vector__XXX
 SG_ KeyInIgnWarn_B_Cmd : 27|1@0+ (1,0) [0|1] "SED" Vector__XXX
 SG_ HomeSafeLtChime_B_Rq : 28|1@0+ (1,0) [0|1] "SED" Vector__XXX
 SG_ StopLghtOn_B_Stat : 8|1@0+ (1,0) [0|1] "SED"  HCM_FD
 SG_ RvrseLghtOn_B_Stat : 9|1@0+ (1,0) [0|1] "SED" Vector__XXX
 SG_ PrkLght_D_Stat : 13|2@0+ (1,0) [0|3] "SED" Vector__XXX
 SG_ HeadLghtSwtch_D_Stat : 15|2@0+ (1,0) [0|3] "SED"  HCM_FD,IPMA_ADAS
 SG_ HeadLampLoFrOn_B_Stat : 2|1@0+ (1,0) [0|1] "SED"  HCM_FD,IPMA_ADAS
 SG_ HeadLampLoFlOn_B_Stat : 3|1@0+ (1,0) [0|1] "SED"  HCM_FD,IPMA_ADAS
 SG_ HeadLampLoActv_B_Stat : 4|1@0+ (1,0) [0|1] "SED"  HCM_FD,IPMA_ADAS,PCM_FD,ECM_Diesel
 SG_ Headlamp_On_Wrning_Cmd : 29|1@0+ (1,0) [0|1] "SED" Vector__XXX
 SG_ Park_Brake_Chime_Rqst : 26|1@0+ (1,0) [0|1] "SED" Vector__XXX
 SG_ HeadLghtHiOn_B_Stat : 1|1@0+ (1,0) [0|1] "SED"  ECM_Diesel,IPMA_ADAS,PCM_FD
 SG_ BrkWarnInd_B_Rq : 20|1@0+ (1,0) [0|1] "SED" Vector__XXX
 SG_ Brk_Fluid_Lvl_Low : 31|2@0+ (1,0) [0|3] "SED"  IPMA_ADAS
 SG_ ReducedGuard_D_Stat : 19|2@0+ (1,0) [0|3] "SED" Vector__XXX
 SG_ Perimeter_Alarm_Status : 17|2@0+ (1,0) [0|3] "SED" Vector__XXX
 SG_ Courtesy_BSave_Stat : 7|2@0+ (1,0) [0|3] "SED" Vector__XXX
 SG_ DrTgateLck_D_Stat : 61|2@0+ (1,0) [0|3] "SED" Vector__XXX
 SG_ WndwGlbl_D_Cmd : 23|3@0+ (1,0) [0|7] "SED" Vector__XXX
 SG_ PudLamp_D_Rq : 11|2@0+ (1,0) [0|3] "SED" Vector__XXX
 SG_ DayRnngLampOn_B_Stat : 5|1@0+ (1,0) [0|1] "SED"  HCM_FD,IPMA_ADAS
 SG_ PerimeterAlarmChimeRq : 0|1@0+ (1,0) [0|1] "SED" Vector__XXX

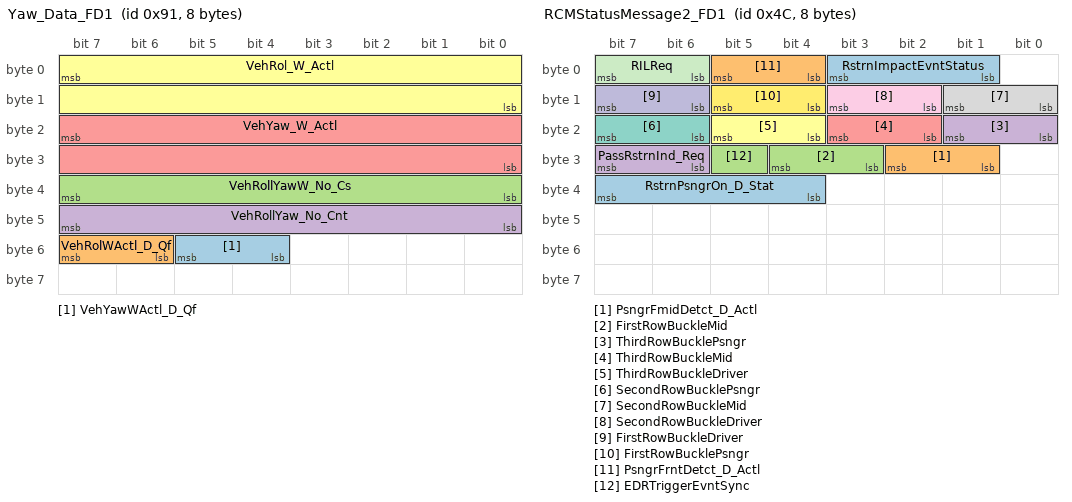
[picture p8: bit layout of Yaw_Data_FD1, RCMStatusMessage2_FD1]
BO_ 145 Yaw_Data_FD1: 8 GWM_ECG
 SG_ VehYawWActl_D_Qf : 53|2@0+ (1,0) [0|3] "SED"  HCM_FD,IPMA_ADAS,ABS_ESC
 SG_ VehRolWActl_D_Qf : 55|2@0+ (1,0) [0|3] "SED"  ABS_ESC
 SG_ VehRollYawW_No_Cs : 39|8@0+ (1,0) [0|255] "Unitless"  ABS_ESC
 SG_ VehRollYaw_No_Cnt : 47|8@0+ (1,0) [0|255] "Unitless"  ABS_ESC
 SG_ VehYaw_W_Actl : 23|16@0+ (0.0002,-6.5) [-6.5|6.6066] "rad/s"  HCM_FD,ABS_ESC,PSCM_FD
 SG_ VehRol_W_Actl : 7|16@0+ (0.0002,-6.5) [-6.5|6.6066] "rad/s"  ABS_ESC,IPMA_ADAS

BO_ 76 RCMStatusMessage2_FD1: 8 GWM_ECG
 SG_ RstrnPsngrOn_D_Stat : 39|4@0+ (1,0) [0|15] "SED" Vector__XXX
 SG_ PsngrFmidDetct_D_Actl : 26|2@0+ (1,0) [0|3] "SED" Vector__XXX
 SG_ FirstRowBuckleMid : 28|2@0+ (1,0) [0|3] "SED" Vector__XXX
 SG_ ThirdRowBucklePsngr : 17|2@0+ (1,0) [0|3] "SED" Vector__XXX
 SG_ ThirdRowBuckleMid : 19|2@0+ (1,0) [0|3] "SED" Vector__XXX
 SG_ ThirdRowBuckleDriver : 21|2@0+ (1,0) [0|3] "SED" Vector__XXX
 SG_ SecondRowBucklePsngr : 23|2@0+ (1,0) [0|3] "SED" Vector__XXX
 SG_ SecondRowBuckleMid : 9|2@0+ (1,0) [0|3] "SED" Vector__XXX
 SG_ SecondRowBuckleDriver : 11|2@0+ (1,0) [0|3] "SED" Vector__XXX
 SG_ FirstRowBuckleDriver : 15|2@0+ (1,0) [0|3] "SED"  ABS_ESC,IPMA_ADAS,ECM_Diesel,PCM_FD,PCM_HEV_FD,TCM_DSL_FD
 SG_ RILReq : 7|2@0+ (1,0) [0|3] "SED" Vector__XXX
 SG_ FirstRowBucklePsngr : 13|2@0+ (1,0) [0|3] "SED" Vector__XXX
 SG_ RstrnImpactEvntStatus : 3|3@0+ (1,0) [0|7] "SED"  ABS_ESC,IPMA_ADAS,ECM_Diesel,PCM_FD,PCM_HEV_FD,TCM_DSL_FD
 SG_ PsngrFrntDetct_D_Actl : 5|2@0+ (1,0) [0|3] "SED" Vector__XXX
 SG_ EDRTriggerEvntSync : 29|1@0+ (1,0) [0|1] "SED"  IPMA_ADAS
 SG_ PassRstrnInd_Req : 31|2@0+ (1,0) [0|3] "SED" Vector__XXX

BO_ 65 Global_PATS_Cntrl_Info_FD1: 8 GWM_ECG
 SG_ immoControlData_T1 : 15|40@0+ (1,0) [0|1099511627775] "Encrypted"  ECM_Diesel,PCM_FD,PCM_HEV_FD
 SG_ immoControlCmd_T1 : 7|3@0+ (1,0) [0|7] "SED"  ECM_Diesel,PCM_FD,PCM_HEV_FD

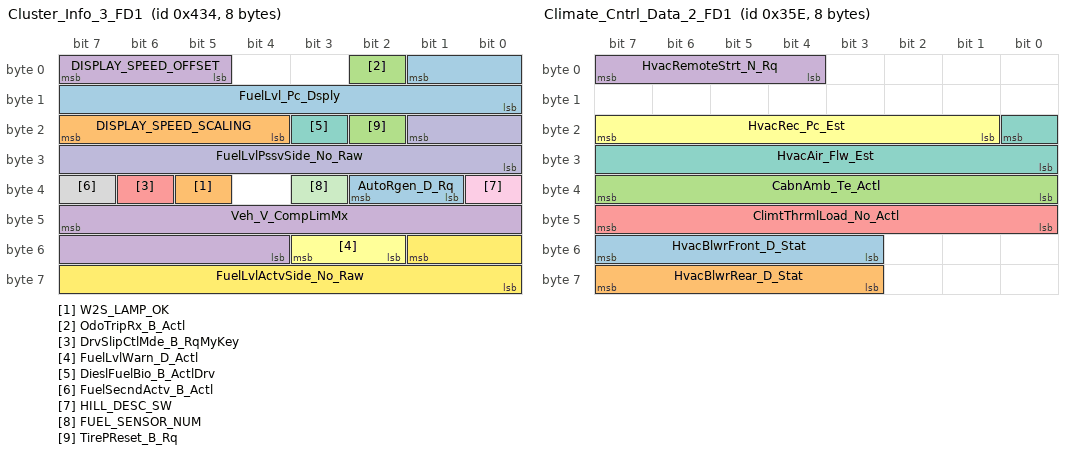
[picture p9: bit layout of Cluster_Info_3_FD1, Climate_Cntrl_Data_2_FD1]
BO_ 1076 Cluster_Info_3_FD1: 8 GWM_ECG
 SG_ AutoRgen_D_Rq : 34|2@0+ (1,0) [0|3] "SED"  ECM_Diesel
 SG_ W2S_LAMP_OK : 37|1@0+ (1,0) [0|1] "SED" Vector__XXX
 SG_ OdoTripRx_B_Actl : 2|1@0+ (1,0) [0|1] "SED"  ECM_Diesel,PCM_FD,PCM_HEV_FD
 SG_ Veh_V_CompLimMx : 47|12@0+ (0.1,0) [0|409.5] "km/h"  ECM_Diesel,PCM_FD,PCM_HEV_FD
 SG_ DrvSlipCtlMde_B_RqMyKey : 38|1@0+ (1,0) [0|1] "SED" Vector__XXX
 SG_ FuelLvlWarn_D_Actl : 51|2@0+ (1,0) [0|3] "SED" Vector__XXX
 SG_ DieslFuelBio_B_ActlDrv : 19|1@0+ (1,0) [0|1] "SED"  ECM_Diesel
 SG_ FuelSecndActv_B_Actl : 39|1@0+ (1,0) [0|1] "SED" Vector__XXX
 SG_ HILL_DESC_SW : 32|1@0+ (1,0) [0|1] "SED"  ABS_ESC
 SG_ FuelLvlPssvSide_No_Raw : 17|10@0+ (1,0) [0|1023] "Unitless"  ECM_Diesel,PCM_FD,PCM_HEV_FD
 SG_ FUEL_SENSOR_NUM : 35|1@0+ (1,0) [0|1] "SED"  ECM_Diesel,PCM_FD,PCM_HEV_FD
 SG_ FuelLvlActvSide_No_Raw : 49|10@0+ (1,0) [0|1023] "Unitless"  ECM_Diesel,PCM_FD,PCM_HEV_FD
 SG_ FuelLvl_Pc_Dsply : 1|10@0+ (0.108696,-5.217408) [-5.217408|105.9786] "Percent"  ECM_Diesel
 SG_ DISPLAY_SPEED_SCALING : 23|4@0+ (0.5,100) [100|107.5] "%"  IPMA_ADAS,ECM_Diesel,PCM_FD,PCM_HEV_FD
 SG_ TirePReset_B_Rq : 18|1@0+ (1,0) [0|1] "SED" Vector__XXX
 SG_ DISPLAY_SPEED_OFFSET : 7|3@0+ (0.5,0) [0|3.5] "kph"  IPMA_ADAS,ECM_Diesel,PCM_FD,PCM_HEV_FD

BO_ 862 Climate_Cntrl_Data_2_FD1: 8 GWM_ECG
 SG_ HvacBlwrFront_D_Stat : 55|5@0+ (1,0) [0|31] "SED"  ECM_Diesel,PCM_FD,PCM_HEV_FD
 SG_ HvacBlwrRear_D_Stat : 63|5@0+ (1,0) [0|31] "SED"  ECM_Diesel,PCM_FD,PCM_HEV_FD
 SG_ CabnAmb_Te_Actl : 39|8@0+ (0.5,-57) [-57|70] "degreesC"  PCM_HEV_FD
 SG_ HvacRemoteStrt_N_Rq : 7|4@0+ (100,450) [450|1950] "RPM"  ECM_Diesel,PCM_FD,PCM_HEV_FD
 SG_ ClimtThrmlLoad_No_Actl : 47|8@0+ (1,0) [0|254] "unitless"  PCM_HEV_FD
 SG_ HvacRec_Pc_Est : 23|7@0+ (1,0) [0|127] "Percent" Vector__XXX
 SG_ HvacAir_Flw_Est : 16|9@0+ (0.5,0) [0|255.5] "liter/second" Vector__XXX

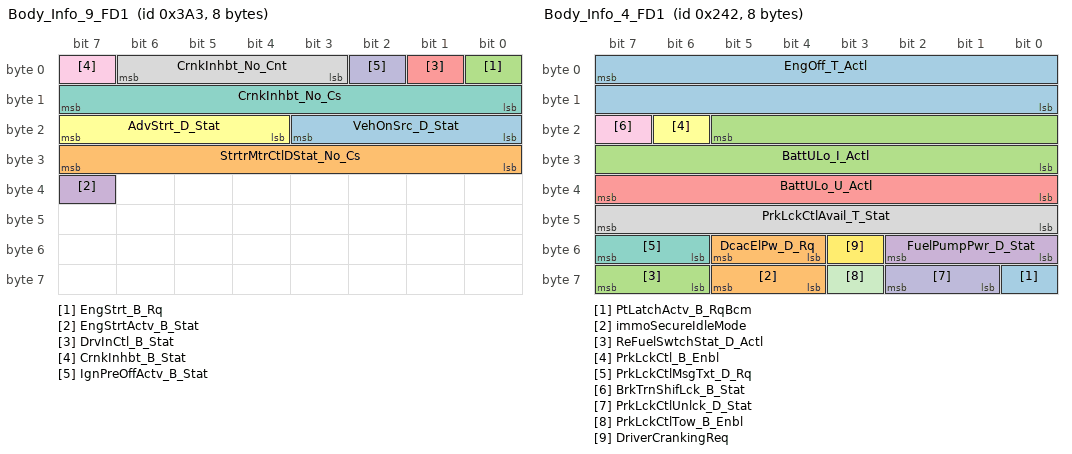
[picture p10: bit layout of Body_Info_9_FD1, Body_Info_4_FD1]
BO_ 931 Body_Info_9_FD1: 8 GWM_ECG
 SG_ VehOnSrc_D_Stat : 19|4@0+ (1,0) [0|15] "SED"  PCM_FD,PCM_HEV_FD,ECM_Diesel
 SG_ StrtrMtrCtlDStat_No_Cs : 31|8@0+ (1,0) [0|255] "unitless"  PCM_FD,ECM_Diesel,PCM_HEV_FD
 SG_ EngStrt_B_Rq : 0|1@0+ (1,0) [0|1] "SED"  PCM_FD,ECM_Diesel,PCM_HEV_FD
 SG_ EngStrtActv_B_Stat : 39|1@0+ (1,0) [0|1] "SED"  PCM_FD,ECM_Diesel,PCM_HEV_FD
 SG_ DrvInCtl_B_Stat : 1|1@0+ (1,0) [0|1] "SED"  PCM_FD,ECM_Diesel,PCM_HEV_FD
 SG_ AdvStrt_D_Stat : 23|4@0+ (1,0) [0|15] "SED"  PCM_FD,ECM_Diesel,PCM_HEV_FD
 SG_ CrnkInhbt_No_Cs : 15|8@0+ (1,0) [0|255] "Unitless"  ECM_Diesel,PCM_FD,PCM_HEV_FD
 SG_ CrnkInhbt_No_Cnt : 6|4@0+ (1,0) [0|15] "Unitless"  ECM_Diesel,PCM_FD,PCM_HEV_FD
 SG_ CrnkInhbt_B_Stat : 7|1@0+ (1,0) [0|1] "SED"  ECM_Diesel,PCM_FD,PCM_HEV_FD
 SG_ IgnPreOffActv_B_Stat : 2|1@0+ (1,0) [0|1] "SED"  PCM_FD,PCM_HEV_FD,TCM_DSL_FD

BO_ 578 Body_Info_4_FD1: 8 GWM_ECG
 SG_ PtLatchActv_B_RqBcm : 56|1@0+ (1,0) [0|1] "SED"  ECM_Diesel,PCM_FD,PCM_HEV_FD,TCM_DSL_FD
 SG_ immoSecureIdleMode : 61|2@0+ (1,0) [0|3] "SED"  ECM_Diesel,PCM_FD,PCM_HEV_FD
 SG_ ReFuelSwtchStat_D_Actl : 63|2@0+ (1,0) [0|3] "SED" Vector__XXX
 SG_ FuelPumpPwr_D_Stat : 50|3@0+ (1,0) [0|7] "SED"  ECM_Diesel,PCM_FD,PCM_HEV_FD
 SG_ BattULo_U_Actl : 39|8@0+ (0.0625,0) [0|15.875] "volt"  ABS_ESC,IPMA_ADAS,PSCM_FD,ECM_Diesel,PCM_FD,PCM_HEV_FD
 SG_ PrkLckCtl_B_Enbl : 22|1@0+ (1,0) [0|1] "SED" Vector__XXX
 SG_ PrkLckCtlMsgTxt_D_Rq : 55|2@0+ (1,0) [0|3] "SED" Vector__XXX
 SG_ PrkLckCtlAvail_T_Stat : 47|8@0+ (1,0) [0|255] "second" Vector__XXX
 SG_ BrkTrnShifLck_B_Stat : 23|1@0+ (1,0) [0|1] "SED"  PCM_FD,PCM_HEV_FD,TCM_DSL_FD
 SG_ PrkLckCtlUnlck_D_Stat : 58|2@0+ (1,0) [0|3] "SED" Vector__XXX
 SG_ PrkLckCtlTow_B_Enbl : 59|1@0+ (1,0) [0|1] "SED" Vector__XXX
 SG_ DriverCrankingReq : 51|1@0+ (1,0) [0|1] "SED"  ECM_Diesel,PCM_FD,PCM_HEV_FD
 SG_ EngOff_T_Actl : 7|16@0+ (1,0) [0|65534] "second^0.5"  ABS_ESC,IPMA_ADAS,TCCM_FD,ECM_Diesel,PCM_FD,PCM_HEV_FD,TCM_DSL_FD
 SG_ DcacElPw_D_Rq : 53|2@0+ (1,0) [0|3] "SED"  ECM_Diesel,PCM_FD
 SG_ BattULo_I_Actl : 21|14@0+ (0.0625,-512) [-512|511.875] "ampere"  ECM_Diesel,PCM_FD,PCM_HEV_FD

BO_ 947 BodyInfo_3_FD1: 8 GWM_ECG
 SG_ ValetMode_D_Mem : 16|1@0+ (1,0) [0|1] "SED" Vector__XXX
 SG_ DimmingLvlEvnt_No_Actl : 18|2@0+ (1,0) [0|3] "unitless" Vector__XXX
 SG_ DrStatDrvErrCnt_B_Stat : 19|1@0+ (1,0) [0|1] "SED"  ECM_Diesel,PCM_FD,PCM_HEV_FD
 SG_ TurnLghtRight_D_Rq : 63|2@0+ (1,0) [0|3] "SED"  HCM_FD,IPMA_ADAS
 SG_ TurnLghtRightOn_B_Stat : 35|1@0+ (1,0) [0|1] "SED" Vector__XXX
 SG_ TurnLghtLeftOn_B_Stat : 54|1@0+ (1,0) [0|1] "SED" Vector__XXX
 SG_ FogLghtRearOn_B_Stat : 1|1@0+ (1,0) [0|1] "SED"  HCM_FD,IPMA_ADAS
 SG_ Backlit_LED_Status : 23|4@0+ (1,0) [0|15] "SED" Vector__XXX
 SG_ TurnLghtLeft_D_Rq : 9|2@0+ (1,0) [0|3] "SED"  HCM_FD,IPMA_ADAS
 SG_ FogLghtFrontOn_B_Stat : 56|1@0+ (1,0) [0|1] "SED"  HCM_FD,IPMA_ADAS
 SG_ IgnKeyType_D_Actl : 39|4@0+ (1,0) [0|15] "SED"  ABS_ESC,ECM_Diesel,IPMA_ADAS,PCM_FD,PCM_HEV_FD
 SG_ Parklamp_Status : 3|2@0+ (1,0) [0|3] "SED"  IPMA_ADAS
 SG_ Litval : 47|8@0+ (1,0) [0|253] "SED"  HCM_FD,IPMA_ADAS
 SG_ Key_In_Ignition_Stat : 11|1@0+ (1,0) [0|1] "SED"  ABS_ESC
 SG_ Ignition_Status : 7|4@0+ (1,0) [0|15] "SED"  HCM_FD,ABS_ESC,ECM_Diesel,IPMA_ADAS,PCM_FD,PCM_HEV_FD,PSCM_FD,TCCM_FD,TCM_DSL_FD
 SG_ Dimming_Lvl : 31|8@0+ (1,0) [0|253] "SED"  IPMA_ADAS
 SG_ Day_Night_Status : 15|2@0+ (1,0) [0|3] "SED"  ECM_Diesel,IPMA_ADAS,PCM_FD
 SG_ Remote_Start_Status : 13|2@0+ (1,0) [0|3] "SED"  IPMA_ADAS
 SG_ DrStatTgate_B_Actl : 0|1@0+ (1,0) [0|1] "SED"  IPMA_ADAS
 SG_ DrStatRr_B_Actl : 49|1@0+ (1,0) [0|1] "SED"  ABS_ESC,IPMA_ADAS
 SG_ DrStatRl_B_Actl : 48|1@0+ (1,0) [0|1] "SED"  ABS_ESC,IPMA_ADAS
 SG_ DrStatPsngr_B_Actl : 60|1@0+ (1,0) [0|1] "SED"  ABS_ESC,IPMA_ADAS
 SG_ DrStatInnrTgate_B_Actl : 58|1@0+ (1,0) [0|1] "SED"  IPMA_ADAS
 SG_ DrStatHood_B_Actl : 59|1@0+ (1,0) [0|1] "SED" Vector__XXX
 SG_ DrStatDrv_B_Actl : 61|1@0+ (1,0) [0|1] "SED"  ABS_ESC,ECM_Diesel,IPMA_ADAS,PCM_FD,PCM_HEV_FD,TCCM_FD
 SG_ PrkBrkActv_B_Actl : 55|1@0+ (1,0) [0|1] "SED"  ABS_ESC,ECM_Diesel,IPMA_ADAS,PCM_FD,PCM_HEV_FD,TCCM_FD,TCM_DSL_FD
 SG_ LifeCycMde_D_Actl : 53|4@0+ (1,0) [0|15] "SED"  HCM_FD,ABS_ESC,ECM_Diesel,IPMA_ADAS,PCM_FD,PCM_HEV_FD,PSCM_FD,TCM_DSL_FD
 SG_ Delay_Accy : 57|1@0+ (1,0) [0|1] "SED" Vector__XXX
 SG_ CrashEvnt_D_Stat : 34|2@0+ (1,0) [0|3] "SED" Vector__XXX
 SG_ FuelPmpInhbt_B_Stat : 32|1@0+ (1,0) [0|1] "SED" Vector__XXX
 SG_ BodySrvcRqd_B_Rq : 10|1@0+ (1,0) [0|1] "SED" Vector__XXX

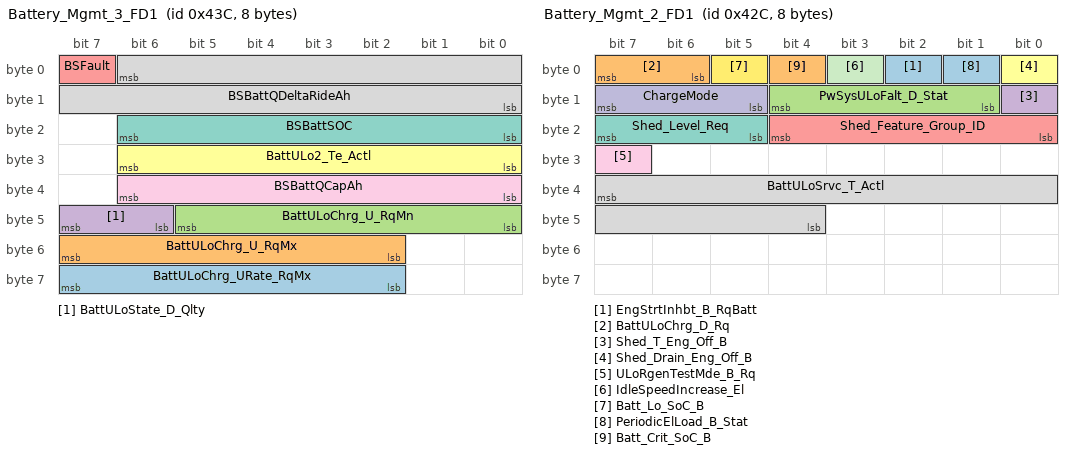
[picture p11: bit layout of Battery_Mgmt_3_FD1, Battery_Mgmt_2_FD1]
BO_ 1084 Battery_Mgmt_3_FD1: 8 GWM_ECG
 SG_ BattULoChrg_URate_RqMx : 63|6@0+ (0.1,0) [0|6.3] "volts/second"  ECM_Diesel,PCM_FD,PCM_HEV_FD
 SG_ BattULoChrg_U_RqMx : 55|6@0+ (0.1,10.6) [10.6|16.9] "volt"  ECM_Diesel,PCM_FD,PCM_HEV_FD
 SG_ BattULoChrg_U_RqMn : 45|6@0+ (0.1,10.6) [10.6|16.9] "volt"  ECM_Diesel,PCM_FD,PCM_HEV_FD
 SG_ BattULoState_D_Qlty : 47|2@0+ (1,0) [0|3] "SED"  ECM_Diesel,PCM_FD,PCM_HEV_FD
 SG_ BSFault : 7|1@0+ (1,0) [0|1] "SED"  ECM_Diesel,PCM_FD,PCM_HEV_FD
 SG_ BattULo2_Te_Actl : 30|7@0+ (1,-40) [-40|86] "degC"  ECM_Diesel,PCM_FD,PCM_HEV_FD
 SG_ BSBattSOC : 22|7@0+ (1,0) [0|127] "%"  ECM_Diesel,PCM_FD,PCM_HEV_FD
 SG_ BSBattQDeltaRideAh : 6|15@0+ (0.0078125,-100) [-100|155.9921875] "ampere*hour"  ECM_Diesel,PCM_FD,PCM_HEV_FD
 SG_ BSBattQCapAh : 38|7@0+ (1,0) [0|127] "ampere*hour"  ECM_Diesel,PCM_FD,PCM_HEV_FD

BO_ 1068 Battery_Mgmt_2_FD1: 8 GWM_ECG
 SG_ EngStrtInhbt_B_RqBatt : 2|1@0+ (1,0) [0|1] "SED"  ECM_Diesel,PCM_FD
 SG_ BattULoChrg_D_Rq : 7|2@0+ (1,0) [0|3] "SED"  ECM_Diesel,PCM_FD
 SG_ PwSysULoFalt_D_Stat : 12|4@0+ (1,0) [0|15] "SED" Vector__XXX
 SG_ Shed_T_Eng_Off_B : 8|1@0+ (1,0) [0|1] "SED" Vector__XXX
 SG_ Shed_Feature_Group_ID : 20|5@0+ (1,0) [0|31] "SED"  ECM_Diesel,PCM_FD,PCM_HEV_FD,IPMA_ADAS
 SG_ Shed_Drain_Eng_Off_B : 0|1@0+ (1,0) [0|1] "SED" Vector__XXX
 SG_ Shed_Level_Req : 23|3@0+ (1,0) [0|7] "SED"  ECM_Diesel,PCM_FD,PCM_HEV_FD,IPMA_ADAS
 SG_ BattULoSrvc_T_Actl : 39|12@0+ (1,0) [0|4095] "days" Vector__XXX
 SG_ ULoRgenTestMde_B_Rq : 31|1@0+ (1,0) [0|1] "SED"  ECM_Diesel,PCM_FD
 SG_ ChargeMode : 15|3@0+ (1,0) [0|7] "SED"  ECM_Diesel,PCM_FD
 SG_ IdleSpeedIncrease_El : 3|1@0+ (1,0) [0|1] "SED" Vector__XXX
 SG_ Batt_Lo_SoC_B : 5|1@0+ (1,0) [0|1] "SED" Vector__XXX
 SG_ PeriodicElLoad_B_Stat : 1|1@0+ (1,0) [0|1] "SED"  ECM_Diesel
 SG_ Batt_Crit_SoC_B : 4|1@0+ (1,0) [0|1] "SED" Vector__XXX

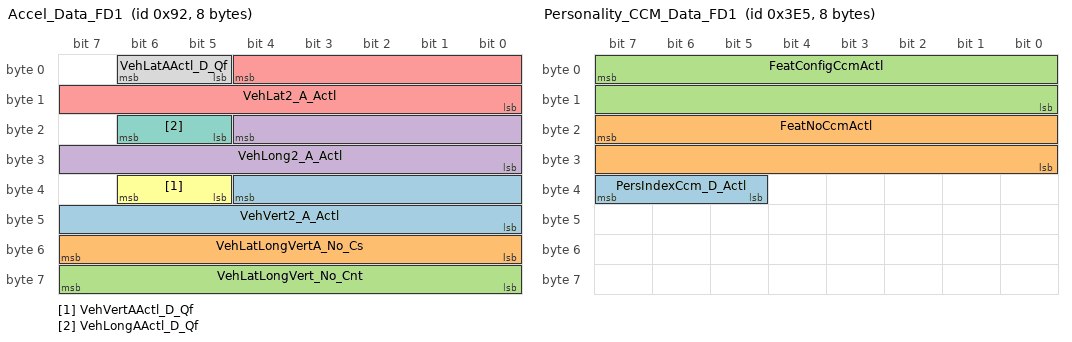
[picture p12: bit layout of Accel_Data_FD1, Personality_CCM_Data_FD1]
BO_ 146 Accel_Data_FD1: 8 GWM_ECG
 SG_ VehVert2_A_Actl : 36|13@0+ (0.01,-40) [-40|41.89] "m/s^2"  ABS_ESC,ECM_Diesel
 SG_ VehLatLongVertA_No_Cs : 55|8@0+ (1,0) [0|255] "Unitless"  ABS_ESC
 SG_ VehLatLongVert_No_Cnt : 63|8@0+ (1,0) [0|255] "Unitless"  ABS_ESC
 SG_ VehLong2_A_Actl : 20|13@0+ (0.01,-40) [-40|41.89] "m/s^2"  ABS_ESC,ECM_Diesel,IPMA_ADAS
 SG_ VehLat2_A_Actl : 4|13@0+ (0.01,-40) [-40|41.89] "m/s^2"  ABS_ESC,ECM_Diesel,IPMA_ADAS
 SG_ VehVertAActl_D_Qf : 38|2@0+ (1,0) [0|3] "SED"  ABS_ESC
 SG_ VehLongAActl_D_Qf : 22|2@0+ (1,0) [0|3] "SED"  ABS_ESC,ECM_Diesel,IPMA_ADAS
 SG_ VehLatAActl_D_Qf : 6|2@0+ (1,0) [0|3] "SED"  ABS_ESC,IPMA_ADAS

BO_ 1900 TesterPhysicalResCCM_FD1: 64 IPMA_ADAS
 SG_ TesterPhysicalResCCM : 7|64@0+ (1,0) [0|1.84467E+019] "unitless"  TSTR

BO_ 1806 TesterPhysicalResIPMA_FD1: 64 IPMA_ADAS
 SG_ TesterPhysicalResIPMA : 7|64@0+ (1,0) [0|1.84467E+019] "unitless"  TSTR

BO_ 997 Personality_CCM_Data_FD1: 8 GWM_ECG
 SG_ PersIndexCcm_D_Actl : 39|3@0+ (1,0) [0|7] "SED" Vector__XXX
 SG_ FeatNoCcmActl : 23|16@0+ (1,0) [0|65535] "Number" Vector__XXX
 SG_ FeatConfigCcmActl : 7|16@0+ (1,0) [0|65535] "Undefined" Vector__XXX

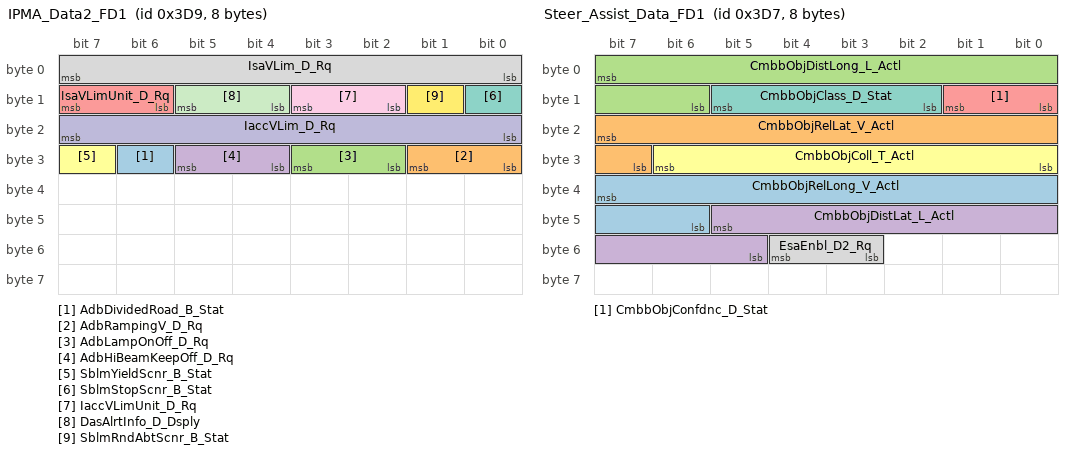
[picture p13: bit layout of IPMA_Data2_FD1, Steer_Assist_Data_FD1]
BO_ 985 IPMA_Data2_FD1: 8 IPMA_ADAS
 SG_ AdbDividedRoad_B_Stat : 30|1@0+ (1,0) [0|1] "SED"  HCM_FD
 SG_ AdbRampingV_D_Rq : 25|2@0+ (1,0) [0|3] "SED"  HCM_FD
 SG_ AdbLampOnOff_D_Rq : 27|2@0+ (1,0) [0|3] "SED"  HCM_FD
 SG_ AdbHiBeamKeepOff_D_Rq : 29|2@0+ (1,0) [0|3] "SED"  HCM_FD
 SG_ IsaVLimUnit_D_Rq : 15|2@0+ (1,0) [0|3] "SED"  ECM_Diesel
 SG_ SblmYieldScnr_B_Stat : 31|1@0+ (1,0) [0|1] "SED"  HCM_FD
 SG_ SblmStopScnr_B_Stat : 8|1@0+ (1,0) [0|1] "SED"  HCM_FD
 SG_ IsaVLim_D_Rq : 7|8@0+ (1,0) [0|255] "SED"  ECM_Diesel
 SG_ IaccVLimUnit_D_Rq : 11|2@0+ (1,0) [0|3] "SED"  ECM_Diesel
 SG_ IaccVLim_D_Rq : 23|8@0+ (1,0) [0|255] "SED"  ECM_Diesel
 SG_ DasAlrtInfo_D_Dsply : 13|2@0+ (1,0) [0|3] "SED" Vector__XXX
 SG_ SblmRndAbtScnr_B_Stat : 9|1@0+ (1,0) [0|1] "SED"  HCM_FD

BO_ 984 IPMA_Data_FD1: 8 IPMA_ADAS
 SG_ AhbHiBeam_D_Rq : 59|2@0+ (1,0) [0|3] "SED" Vector__XXX
 SG_ CadsCamraStat_D_Qf : 61|2@0+ (1,0) [0|3] "SED" Vector__XXX
 SG_ AhbcStat_B_Dsply : 48|1@0+ (1,0) [0|1] "SED" Vector__XXX
 SG_ LaSwtch_D_RqDrv : 45|1@0+ (1,0) [0|1] "SED" Vector__XXX
 SG_ AhbcHiBeam_D_Rq : 63|2@0+ (1,0) [0|3] "SED" Vector__XXX
 SG_ LaSwtchStat_No_Actl : 33|1@0+ (1,0) [0|1] "unitless" Vector__XXX
 SG_ DasWarn_D_Dsply : 44|2@0+ (1,0) [0|3] "SED" Vector__XXX
 SG_ DasStats_D_Dsply : 47|2@0+ (1,0) [0|3] "SED" Vector__XXX
 SG_ DasAlrtLvl_D_Dsply : 42|3@0+ (1,0) [0|7] "SED" Vector__XXX
 SG_ CamraStats_D_Dsply : 35|2@0+ (1,0) [0|3] "SED" Vector__XXX
 SG_ CamraDefog_B_Req : 36|1@0+ (1,0) [0|1] "SED" Vector__XXX
 SG_ LaHandsOff_D_Dsply : 50|2@0+ (1,0) [0|3] "SED" Vector__XXX
 SG_ LaDenyStats_B_Dsply : 32|1@0+ (1,0) [0|1] "SED" Vector__XXX
 SG_ LaActvStats_D_Dsply : 55|5@0+ (1,0) [0|31] "SED" Vector__XXX
 SG_ AhbcRampingV_D_Rq : 57|2@0+ (1,0) [0|3] "SED"  HCM_FD
 SG_ PersIndexIpma_D_Actl : 39|3@0+ (1,0) [0|7] "SED" Vector__XXX
 SG_ FeatNoIpmaActl : 23|16@0+ (1,0) [0|65535] "Number" Vector__XXX
 SG_ FeatConfigIpmaActl : 7|16@0+ (1,0) [0|65535] "Undefined" Vector__XXX

BO_ 983 Steer_Assist_Data_FD1: 8 IPMA_ADAS
 SG_ CmbbObjRelLong_V_Actl : 39|10@0+ (0.1,-102.1) [-102.1|0] "meters/sec"  PSCM_FD
 SG_ CmbbObjRelLat_V_Actl : 23|9@0+ (0.1,-25.5) [-25.5|25.4] "meters/sec"  PSCM_FD
 SG_ CmbbObjDistLong_L_Actl : 7|10@0+ (0.1,0) [0|102.1] "meter"  PSCM_FD
 SG_ CmbbObjDistLat_L_Actl : 45|9@0+ (0.1,-25.5) [-25.5|25.4] "meter"  PSCM_FD
 SG_ CmbbObjConfdnc_D_Stat : 9|2@0+ (1,0) [0|3] "SED"  PSCM_FD
 SG_ CmbbObjColl_T_Actl : 30|7@0+ (0.05,0) [0|6.25] "second"  PSCM_FD
 SG_ CmbbObjClass_D_Stat : 13|4@0+ (1,0) [0|15] "SED"  PSCM_FD
 SG_ EsaEnbl_D2_Rq : 52|2@0+ (1,0) [0|3] "SED"  PSCM_FD

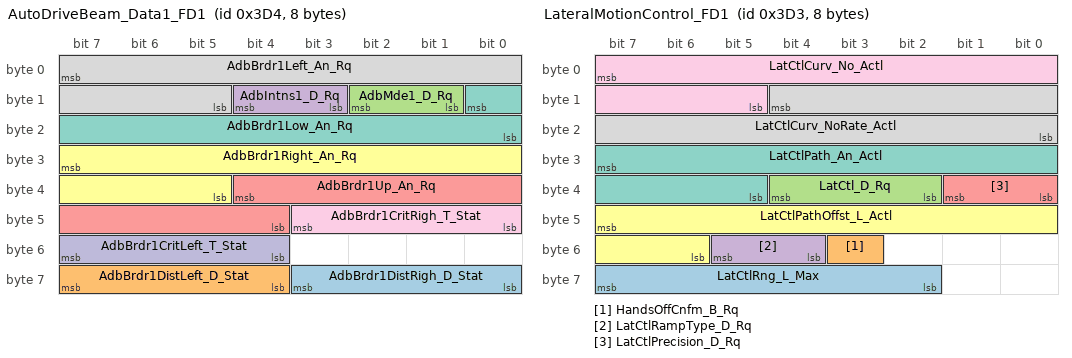
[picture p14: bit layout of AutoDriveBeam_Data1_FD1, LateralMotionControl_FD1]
BO_ 980 AutoDriveBeam_Data1_FD1: 8 IPMA_ADAS
 SG_ AdbBrdr1DistRigh_D_Stat : 59|4@0+ (1,0) [0|15] "SED"  HCM_FD
 SG_ AdbBrdr1DistLeft_D_Stat : 63|4@0+ (1,0) [0|15] "SED"  HCM_FD
 SG_ AdbMde1_D_Rq : 10|2@0+ (1,0) [0|3] "SED"  HCM_FD
 SG_ AdbIntns1_D_Rq : 12|2@0+ (1,0) [0|3] "SED"  HCM_FD
 SG_ AdbBrdr1Up_An_Rq : 36|9@0+ (0.02,-8) [-8|2.18] "degrees"  HCM_FD
 SG_ AdbBrdr1Right_An_Rq : 31|11@0+ (0.02,-20) [-20|20.9] "degrees"  HCM_FD
 SG_ AdbBrdr1Low_An_Rq : 8|9@0+ (0.02,-8) [-8|2.18] "degrees"  HCM_FD
 SG_ AdbBrdr1Left_An_Rq : 7|11@0+ (0.02,-20) [-20|20.9] "degrees"  HCM_FD
 SG_ AdbBrdr1CritRigh_T_Stat : 43|4@0+ (100,0) [0|1500] "millisecond"  HCM_FD
 SG_ AdbBrdr1CritLeft_T_Stat : 55|4@0+ (100,0) [0|1500] "millisecond"  HCM_FD

BO_ 979 LateralMotionControl_FD1: 8 IPMA_ADAS
 SG_ LatCtlRng_L_Max : 63|6@0+ (2,0) [0|126] "meter"  PSCM_FD
 SG_ HandsOffCnfm_B_Rq : 51|1@0+ (1,0) [0|1] "SED"  GWM_ECG,PSCM_FD
 SG_ LatCtl_D_Rq : 36|3@0+ (1,0) [0|7] "SED"  GWM_ECG,PSCM_FD
 SG_ LatCtlRampType_D_Rq : 53|2@0+ (1,0) [0|3] "SED"  GWM_ECG,PSCM_FD
 SG_ LatCtlPrecision_D_Rq : 33|2@0+ (1,0) [0|3] "SED"  GWM_ECG,PSCM_FD
 SG_ LatCtlPathOffst_L_Actl : 47|10@0+ (0.01,-5.12) [-5.12|5.11] "meter"  HCM_FD,GWM_ECG,PSCM_FD
 SG_ LatCtlPath_An_Actl : 31|11@0+ (0.0005,-0.5) [-0.5|0.5235] "radians"  HCM_FD,GWM_ECG,PSCM_FD
 SG_ LatCtlCurv_NoRate_Actl : 12|13@0+ (2.5E-007,-0.001024) [-0.001024|0.00102375] "1/meter"  HCM_FD,GWM_ECG,PSCM_FD
 SG_ LatCtlCurv_No_Actl : 7|11@0+ (2E-005,-0.02) [-0.02|0.02094] "1/meter"  HCM_FD,GWM_ECG,PSCM_FD

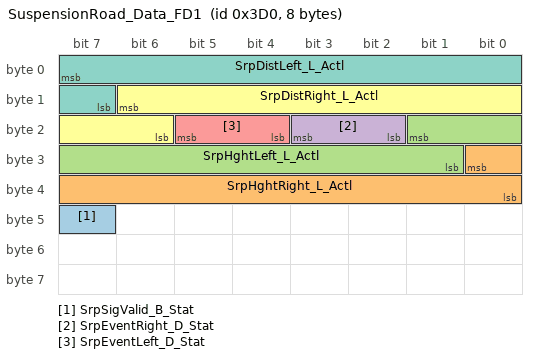
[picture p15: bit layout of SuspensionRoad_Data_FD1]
BO_ 976 SuspensionRoad_Data_FD1: 8 IPMA_ADAS
 SG_ SrpSigValid_B_Stat : 47|1@0+ (1,0) [0|1] "SED"  IPMA_ADAS,GWM_ECG
 SG_ SrpHghtRight_L_Actl : 24|9@0+ (0.000625,-0.16) [-0.16|0.158125] "meter"  IPMA_ADAS,GWM_ECG
 SG_ SrpHghtLeft_L_Actl : 17|9@0+ (0.000625,-0.16) [-0.16|0.158125] "meter"  IPMA_ADAS,GWM_ECG
 SG_ SrpEventRight_D_Stat : 19|2@0+ (1,0) [0|3] "SED"  IPMA_ADAS,GWM_ECG
 SG_ SrpEventLeft_D_Stat : 21|2@0+ (1,0) [0|3] "SED"  IPMA_ADAS,GWM_ECG
 SG_ SrpDistRight_L_Actl : 14|9@0+ (0.02,0) [0|10.18] "meter"  IPMA_ADAS,GWM_ECG
 SG_ SrpDistLeft_L_Actl : 7|9@0+ (0.02,0) [0|10.18] "meter"  IPMA_ADAS,GWM_ECG

BO_ 973 Traffic_RecognitnData_FD1: 8 IPMA_ADAS
 SG_ TsrVl2PrmntMsgTxt_D_Rq : 60|2@0+ (1,0) [0|3] "SED" Vector__XXX
 SG_ TsrVl1PrmntMsgTxt_D_Rq : 41|2@0+ (1,0) [0|3] "SED" Vector__XXX
 SG_ TsrVl2RstrcMsgTxt2_D_Rq : 63|3@0+ (1,0) [0|7] "SED" Vector__XXX
 SG_ TsrVl1RstrcMsgTxt2_D_Rq : 51|3@0+ (1,0) [0|7] "SED" Vector__XXX
 SG_ TsrOvtkMsgTxt2_D_Rq : 55|4@0+ (1,0) [0|15] "SED" Vector__XXX
 SG_ WwaWarn_B_Rq : 48|1@0+ (1,0) [0|1] "SED" Vector__XXX
 SG_ TsrVlUnitMsgTxt_D_Rq : 43|2@0+ (1,0) [0|3] "SED" Vector__XXX
 SG_ TsrVLim2MsgTxt_D_Rq : 39|8@0+ (1,0) [0|255] "SED" Vector__XXX
 SG_ TsrVLim1MsgTxt_D_Rq : 31|8@0+ (1,0) [0|255] "SED" Vector__XXX
 SG_ TsrVl2TypeMsgTxt_D_Rq : 45|2@0+ (1,0) [0|3] "SED" Vector__XXX
 SG_ TsrVl2StatMsgTxt_D_Rq : 47|2@0+ (1,0) [0|3] "SED" Vector__XXX
 SG_ TsrVl2RstrcMsgTxt_D_Rq : 17|2@0+ (1,0) [0|3] "SED" Vector__XXX
 SG_ TsrVl1TypeMsgTxt_D_Rq : 19|2@0+ (1,0) [0|3] "SED" Vector__XXX
 SG_ TsrVl1StatMsgTxt_D_Rq : 21|2@0+ (1,0) [0|3] "SED" Vector__XXX
 SG_ TsrVl1RstrcMsgTxt_D_Rq : 23|2@0+ (1,0) [0|3] "SED" Vector__XXX
 SG_ TsrStatMsgTxt_D_Rq : 10|3@0+ (1,0) [0|7] "SED" Vector__XXX
 SG_ TsrOvtkTypeMsgTxt_D_Rq : 12|2@0+ (1,0) [0|3] "SED" Vector__XXX
 SG_ TsrOvtkStatMsgTxt_D_Rq : 1|2@0+ (1,0) [0|3] "SED" Vector__XXX
 SG_ TsrOvtkMsgTxt_D_Rq : 15|3@0+ (1,0) [0|7] "SED" Vector__XXX
 SG_ TsrOswWarnMsgTxt_D_Rq : 3|2@0+ (1,0) [0|3] "SED" Vector__XXX
 SG_ TsrMsgTxt_D_Rq : 7|4@0+ (1,0) [0|15] "SED" Vector__XXX

BO_TX_BU_ 985 : GWM_ECG,IPMA_ADAS;
BO_TX_BU_ 983 : GWM_ECG,IPMA_ADAS;
BO_TX_BU_ 979 : GWM_ECG,IPMA_ADAS;
CM_ BO_ 1009 "APIM Tx";
CM_ SG_ 1009 CenterStackRing_D_Actl "The Center Stack sends the CPLR a signal to turn On or Off the light Ring, This is a customer selectable preference switch";
CM_ SG_ 1009 APIM_NumberofTracks_St "Object NumberofTracks";
CM_ SG_ 1009 APIM_ActiveTrackNum_St "Object.ActiveTrackNum";
CM_ SG_ 360 GsmSrvcRqd_B_Rq "Signal not transmitted on vehicles that do not have shift by wire.";
CM_ SG_ 360 TrnTrcmPwmSig_D_Actl "Signal not transmitted on vehicles that do not have shift by wire.";
CM_ SG_ 360 TrnGearPwmFalt_B_Actl "Signal not transmitted on vehicles that do not have shift by wire.";
CM_ SG_ 360 GearButtnStuck_B_Actl "Signal not transmitted on vehicles that do not have shift by wire.";
CM_ SG_ 90 TrnGsmNtmState_D_Actl "Signal not transmitted on vehicles that do not have shift by wire.";
CM_ SG_ 90 DrQltyDrv_D_StatGsm "Signal not transmitted on vehicles that do not have shift by wire.";
CM_ SG_ 90 TrnBtsiOvrrd_B_Stat "Signal not transmitted on vehicles that do not have shift by wire.";
CM_ SG_ 90 TrnValidGearRq_D_Stat "Signal not transmitted on vehicles that do not have shift by wire.";
CM_ SG_ 90 TrnGearRqCnt_B_Actl "Signal not transmitted on vehicles that do not have shift by wire.";
CM_ SG_ 90 TrnGearButtn_U_Actl "Signal not transmitted on vehicles that do not have shift by wire.";
CM_ SG_ 90 TrnGearButtn_B_ActlR2 "Signal not transmitted on vehicles that do not have shift by wire.";
CM_ SG_ 90 TrnGearButtn_B_ActlR1 "Signal not transmitted on vehicles that do not have shift by wire.";
CM_ SG_ 90 TrnGearButtn_B_ActlR0 "Signal not transmitted on vehicles that do not have shift by wire.";
CM_ SG_ 90 TrnGearButtn_B_ActlP2 "Signal not transmitted on vehicles that do not have shift by wire.";
CM_ SG_ 90 TrnGearButtn_B_ActlP1 "Signal not transmitted on vehicles that do not have shift by wire.";
CM_ SG_ 90 TrnGearButtn_B_ActlP0 "Signal not transmitted on vehicles that do not have shift by wire.";
CM_ SG_ 90 TrnGearButtn_B_ActlN2 "Signal not transmitted on vehicles that do not have shift by wire.";
CM_ SG_ 90 TrnGearButtn_B_ActlN1 "Signal not transmitted on vehicles that do not have shift by wire.";
CM_ SG_ 90 TrnGearButtn_B_ActlN0 "Signal not transmitted on vehicles that do not have shift by wire.";
CM_ SG_ 90 TrnGearButtn_B_ActlM2 "Signal not transmitted on vehicles that do not have shift by wire.";
CM_ SG_ 90 TrnGearButtn_B_ActlM1 "Signal not transmitted on vehicles that do not have shift by wire.";
CM_ SG_ 90 TrnGearButtn_B_ActlM0 "Signal not transmitted on vehicles that do not have shift by wire.";
CM_ SG_ 90 TrnGearButtn_B_ActlD2 "Signal not transmitted on vehicles that do not have shift by wire.";
CM_ SG_ 90 TrnGearButtn_B_ActlD1 "Signal not transmitted on vehicles that do not have shift by wire.";
CM_ SG_ 90 TrnGearButtn_B_ActlD0 "Signal not transmitted on vehicles that do not have shift by wire.";
CM_ SG_ 90 TrnGear_No_Cs "Signal not transmitted on vehicles that do not have shift by wire.";
CM_ SG_ 90 TrnGear_No_Cnt "Signal not transmitted on vehicles that do not have shift by wire.";
CM_ SG_ 90 TrnGear_D_RqDrv "Signal not transmitted on vehicles that do not have shift by wire.";
CM_ SG_ 90 BrkSwtchPos_B_ActlGsm "Signal not transmitted on vehicles that do not have shift by wire.";
CM_ BO_ 1111 " new RCM Serial Trailer Aid (TrailerAid_Stat1) 48 bits";
CM_ BO_ 1106 " new RCM Serial Trailer Aid (TrailerAid_Stat1) 48 bits";
CM_ SG_ 1091 PoliceAux4Lamp_B_Rq2 "Signal not transmitted on programs that do not have AWD.";
CM_ SG_ 1091 PoliceAux3Lamp_B_Rq2 "Signal not transmitted on programs that do not have AWD.";
CM_ SG_ 1091 PoliceAux2Lamp_B_Rq2 "Signal not transmitted on programs that do not have AWD.";
CM_ SG_ 1091 PoliceAux1Lamp_B_Rq2 "Signal not transmitted on programs that do not have AWD.";
CM_ SG_ 138 SteWhlRelCalib_An_Sns "Signal is not transmitted on vehicles where PSCM is transmitting the message that contains this signal.
Signal data set to 0x0 for ABS only vehicle option content";
CM_ SG_ 1093 StopLamp_B_RqTrlrBrk "Signal not transmitted on all variants.";
CM_ SG_ 792 ElTrip_L_Dsply "Key cycle trip distance driven with the engine off (Trip EV Miles)";
CM_ SG_ 792 ElLongTerm_L_Dsply "Long term distance distance driven with the engine off since the last long term reset (Long Term EV Miles).";
CM_ SG_ 765 Mc_VehUntTrpCoUsrSel_St "Object.VehicleSettings.Disp_Miles_Kilometers.Rq";
CM_ SG_ 765 Mc_VehUnitTempUsrSel_St "Object.VehicleSettings.Disp_Temperature.Rq";
CM_ SG_ 765 Mc_VehDayNightUsrSel_St "Object.BodyInterface.Settings.VehicleDayNightUserSelection
Object.BodyInterface.Status.AMDayNightSensitivity";
CM_ SG_ 765 Mc_VehTimeFrmtUsrSel_St "Object.BodyInterface.Settings.VehicleTimeFormatUserSelection";
CM_ SG_ 765 Mc_VehThemeUsrSel_St "Object.BodyInterface.Settings.VehicleThemeUserSelection";
CM_ SG_ 765 Mc_VehLangUsrSel_St "Object.BodyInterface.Settings.VehicleLanguageUserSelection
Object Vehicle Settings.Disp_LangSel
";
CM_ BO_ 559 "APIM Tx";
CM_ BO_ 558 "APIM Tx";
CM_ SG_ 934 Side_Detect_L_Illum "DDMGenSigTimeoutTime=2000";
CM_ SG_ 934 CtaInnrLeft_D_Stat "IPCGenSigTimeoutTime=1600";
CM_ SG_ 934 SodLeft_D_Stat "IPCGenSigTimeoutTime=1600";
CM_ SG_ 934 SodSnsLeft_D_Stat "IPCGenSigTimeoutTime=1600";
CM_ SG_ 934 SodAlrtLeft_D_Stat "DDMGenSigTimeoutTime=2000";
CM_ SG_ 1072 MetricActv_B_Actl "0 =Inactive(English), 1=Active(Metric)";
CM_ SG_ 145 VehYaw_W_Actl "CCMGenSigTimeoutTime=1000";
CM_ BO_ 65 "Provide control function information to the target function of the Passive Anti-Theft Subsystem";
CM_ SG_ 931 CrnkInhbt_No_Cs "Signal not transmitted on gas and HEV variants.";
CM_ SG_ 931 CrnkInhbt_No_Cnt "Signal not transmitted on gas and HEV variants.";
CM_ SG_ 947 Dimming_Lvl "Refer to Vehicle Interior Illum Dimming Ctrl Sys Eng Spec, Table 2

";
CM_ SG_ 947 PrkBrkActv_B_Actl "Signal not transmitted on vehicles with electric park brake. ";
BA_DEF_ BO_  "VFrameFormat" ENUM  "StandardCAN","ExtendedCAN","reserved","reserved","reserved","reserved","reserved","reserved","reserved","reserved","reserved","reserved","reserved","reserved","StandardCAN_FD","ExtendedCAN_FD";
BA_DEF_ SG_  "GenSigSendType" ENUM  "Cyclic","OnWrite","vector_leerstring","OnChange","vector_leerstring","IfActive","vector_leerstring","NoSigSendType";
BA_DEF_ SG_  "GenSigInactiveValue" INT 0 100000;
BA_DEF_ SG_  "WakeupSignal" ENUM  "No","Yes";
BA_DEF_ SG_  "CrossOver_InfoCAN" ENUM  "No","Yes";
BA_DEF_ SG_  "UsedOnPgmDBC" ENUM  "No","Yes";
BA_DEF_ SG_  "GenSigStartValue" INT 0 1000000000;
BA_DEF_ SG_  "ContentDependant" ENUM  "No","Yes";
BA_DEF_ SG_  "MetaData" ENUM  "No","Yes";
BA_DEF_ SG_  "U_P702_MY2021_Rx" ENUM  "No","Yes";
BA_DEF_ SG_  "U_CX727_MY2021_Tx" ENUM  "No","Yes";
BA_DEF_ SG_  "U_P702_MY2021_Tx" ENUM  "No","Yes";
BA_DEF_ BO_  "GenMsgILSupport" ENUM  "No","Yes";
BA_DEF_ BO_  "DiagResponse" ENUM  "No","Yes";
BA_DEF_ BO_  "DiagRequest" ENUM  "No","Yes";
BA_DEF_ BO_  "DiagState" ENUM  "No","Yes";
BA_DEF_ BO_  "TpApplType" STRING ;
BA_DEF_ BO_  "NmAsrMessage" ENUM  "No","Yes";
BA_DEF_ BO_  "MessageGateway" ENUM  "No","Yes";
BA_DEF_ BO_  "AuthFreshnessCounterSyncAttempt" INT 0 2;
BA_DEF_ BO_  "GenMsgSendType" ENUM  "FixedPeriodic","Event","EnabledPeriodic","NotUsed","NotUsed","EventPeriodic","NotUsed","NotUsed","NoMsgSendType";
BA_DEF_ BO_  "GenMsgCycleTime" INT 0 100000;
BA_DEF_ BO_  "GenMsgDelayTime" INT 0 1000;
BA_DEF_ BO_  "GenMsgNrOfRepetition" INT 0 100;
BA_DEF_ BO_  "GenMsgStartDelayTime" INT 0 10000;
BA_DEF_ BO_  "EventRateOfChange" INT 10 10000;
BA_DEF_ BO_  "FrameGatewayId" HEX 0 1407;
BA_DEF_ BO_  "NetworkInitialization" ENUM  "No","Yes";
BA_DEF_ BO_  "FrameGatewayNetwork" STRING ;
BA_DEF_DEF_  "VFrameFormat" "ExtendedCAN_FD";
BA_DEF_DEF_  "GenSigSendType" "NoSigSendType";
BA_DEF_DEF_  "GenSigInactiveValue" 0;
BA_DEF_DEF_  "WakeupSignal" "No";
BA_DEF_DEF_  "CrossOver_InfoCAN" "No";
BA_DEF_DEF_  "UsedOnPgmDBC" "Yes";
BA_DEF_DEF_  "GenSigStartValue" 0;
BA_DEF_DEF_  "ContentDependant" "No";
BA_DEF_DEF_  "MetaData" "No";
BA_DEF_DEF_  "U_P702_MY2021_Rx" "No";
BA_DEF_DEF_  "U_CX727_MY2021_Tx" "No";
BA_DEF_DEF_  "U_P702_MY2021_Tx" "No";
BA_DEF_DEF_  "GenMsgILSupport" "Yes";
BA_DEF_DEF_  "DiagResponse" "No";
BA_DEF_DEF_  "DiagRequest" "No";
BA_DEF_DEF_  "DiagState" "No";
BA_DEF_DEF_  "TpApplType" "";
BA_DEF_DEF_  "NmAsrMessage" "No";
BA_DEF_DEF_  "MessageGateway" "No";
BA_DEF_DEF_  "AuthFreshnessCounterSyncAttempt" 2;
BA_DEF_DEF_  "GenMsgSendType" "NoMsgSendType";
BA_DEF_DEF_  "GenMsgCycleTime" 0;
BA_DEF_DEF_  "GenMsgDelayTime" 20;
BA_DEF_DEF_  "GenMsgNrOfRepetition" 1;
BA_DEF_DEF_  "GenMsgStartDelayTime" 0;
BA_DEF_DEF_  "EventRateOfChange" 10000;
BA_DEF_DEF_  "FrameGatewayId" 0;
BA_DEF_DEF_  "NetworkInitialization" "Yes";
BA_DEF_DEF_  "FrameGatewayNetwork" "NONE";
BA_ "GenMsgDelayTime" BO_ 936 10;
BA_ "GenMsgCycleTime" BO_ 936 20;
BA_ "GenMsgSendType" BO_ 936 0;
BA_ "VFrameFormat" BO_ 936 14;
BA_ "GenMsgCycleTime" BO_ 877 1000;
BA_ "GenMsgSendType" BO_ 877 5;
BA_ "VFrameFormat" BO_ 877 14;
BA_ "FrameGatewayNetwork" BO_ 786 "HS3_CAN";
BA_ "FrameGatewayId" BO_ 786 786;
BA_ "VFrameFormat" BO_ 786 14;
BA_ "FrameGatewayNetwork" BO_ 389 "HS1_CAN";
BA_ "FrameGatewayId" BO_ 389 389;
BA_ "VFrameFormat" BO_ 389 14;
BA_ "FrameGatewayNetwork" BO_ 1009 "HS3_CAN";
BA_ "FrameGatewayId" BO_ 1009 1009;
BA_ "VFrameFormat" BO_ 1009 14;
BA_ "FrameGatewayNetwork" BO_ 360 "HS2_CAN";
BA_ "FrameGatewayId" BO_ 360 360;
BA_ "VFrameFormat" BO_ 360 14;
BA_ "FrameGatewayNetwork" BO_ 122 "HS1_CAN";
BA_ "FrameGatewayId" BO_ 122 122;
BA_ "VFrameFormat" BO_ 122 14;
BA_ "FrameGatewayNetwork" BO_ 90 "HS2_CAN";
BA_ "FrameGatewayId" BO_ 90 90;
BA_ "VFrameFormat" BO_ 90 14;
BA_ "FrameGatewayId" BO_ 1114 1114;
BA_ "FrameGatewayNetwork" BO_ 1114 "HS3_CAN";
BA_ "VFrameFormat" BO_ 1114 14;
BA_ "FrameGatewayNetwork" BO_ 1111 "HS2_CAN";
BA_ "FrameGatewayId" BO_ 1111 1111;
BA_ "VFrameFormat" BO_ 1111 14;
BA_ "FrameGatewayNetwork" BO_ 1106 "HS2_CAN";
BA_ "FrameGatewayId" BO_ 1106 1106;
BA_ "VFrameFormat" BO_ 1106 14;
BA_ "FrameGatewayNetwork" BO_ 1091 "MS1_CAN";
BA_ "FrameGatewayId" BO_ 1091 1091;
BA_ "VFrameFormat" BO_ 1091 14;
BA_ "FrameGatewayNetwork" BO_ 138 "HS2_CAN";
BA_ "FrameGatewayId" BO_ 138 138;
BA_ "VFrameFormat" BO_ 138 14;
BA_ "FrameGatewayNetwork" BO_ 131 "HS2_CAN";
BA_ "FrameGatewayId" BO_ 131 131;
BA_ "MessageGateway" BO_ 131 1;
BA_ "VFrameFormat" BO_ 131 14;
BA_ "FrameGatewayNetwork" BO_ 953 "HS1_CAN";
BA_ "FrameGatewayId" BO_ 953 953;
BA_ "VFrameFormat" BO_ 953 14;
BA_ "FrameGatewayNetwork" BO_ 1093 "HS2_CAN";
BA_ "FrameGatewayId" BO_ 1093 1093;
BA_ "VFrameFormat" BO_ 1093 14;
BA_ "FrameGatewayNetwork" BO_ 792 "HS3_CAN";
BA_ "FrameGatewayId" BO_ 792 792;
BA_ "VFrameFormat" BO_ 792 14;
BA_ "FrameGatewayNetwork" BO_ 968 "HS3_CAN";
BA_ "FrameGatewayId" BO_ 968 968;
BA_ "VFrameFormat" BO_ 968 14;
BA_ "FrameGatewayNetwork" BO_ 819 "MS1_CAN";
BA_ "FrameGatewayId" BO_ 819 819;
BA_ "VFrameFormat" BO_ 819 14;
BA_ "FrameGatewayNetwork" BO_ 818 "MS1_CAN";
BA_ "FrameGatewayId" BO_ 818 818;
BA_ "VFrameFormat" BO_ 818 14;
BA_ "FrameGatewayNetwork" BO_ 806 "MS1_CAN";
BA_ "FrameGatewayId" BO_ 806 806;
BA_ "VFrameFormat" BO_ 806 14;
BA_ "FrameGatewayNetwork" BO_ 765 "HS3_CAN";
BA_ "FrameGatewayId" BO_ 765 765;
BA_ "VFrameFormat" BO_ 765 14;
BA_ "FrameGatewayNetwork" BO_ 559 "HS3_CAN";
BA_ "FrameGatewayId" BO_ 559 559;
BA_ "VFrameFormat" BO_ 559 14;
BA_ "FrameGatewayNetwork" BO_ 558 "HS3_CAN";
BA_ "FrameGatewayId" BO_ 558 558;
BA_ "VFrameFormat" BO_ 558 14;
BA_ "GenMsgCycleTime" BO_ 934 200;
BA_ "GenMsgSendType" BO_ 934 5;
BA_ "VFrameFormat" BO_ 934 14;
BA_ "FrameGatewayNetwork" BO_ 1072 "HS3_CAN";
BA_ "FrameGatewayId" BO_ 1072 1072;
BA_ "VFrameFormat" BO_ 1072 14;
BA_ "FrameGatewayNetwork" BO_ 909 "HS1_CAN";
BA_ "FrameGatewayId" BO_ 909 909;
BA_ "VFrameFormat" BO_ 909 14;
BA_ "FrameGatewayNetwork" BO_ 963 "HS1_CAN";
BA_ "FrameGatewayId" BO_ 963 963;
BA_ "VFrameFormat" BO_ 963 14;
BA_ "FrameGatewayNetwork" BO_ 145 "HS2_CAN";
BA_ "FrameGatewayId" BO_ 145 145;
BA_ "VFrameFormat" BO_ 145 14;
BA_ "FrameGatewayNetwork" BO_ 76 "HS2_CAN";
BA_ "FrameGatewayId" BO_ 76 76;
BA_ "VFrameFormat" BO_ 76 14;
BA_ "FrameGatewayNetwork" BO_ 65 "HS1_CAN";
BA_ "FrameGatewayId" BO_ 65 65;
BA_ "GenMsgDelayTime" BO_ 65 10;
BA_ "VFrameFormat" BO_ 65 14;
BA_ "FrameGatewayNetwork" BO_ 1076 "HS3_CAN";
BA_ "FrameGatewayId" BO_ 1076 1076;
BA_ "VFrameFormat" BO_ 1076 14;
BA_ "FrameGatewayNetwork" BO_ 862 "MS1_CAN";
BA_ "FrameGatewayId" BO_ 862 862;
BA_ "VFrameFormat" BO_ 862 14;
BA_ "FrameGatewayNetwork" BO_ 931 "HS1_CAN";
BA_ "FrameGatewayId" BO_ 931 931;
BA_ "VFrameFormat" BO_ 931 14;
BA_ "FrameGatewayNetwork" BO_ 578 "HS1_CAN";
BA_ "FrameGatewayId" BO_ 578 578;
BA_ "VFrameFormat" BO_ 578 14;
BA_ "FrameGatewayNetwork" BO_ 947 "HS1_CAN";
BA_ "FrameGatewayId" BO_ 947 947;
BA_ "VFrameFormat" BO_ 947 14;
BA_ "FrameGatewayNetwork" BO_ 1084 "HS1_CAN";
BA_ "FrameGatewayId" BO_ 1084 1084;
BA_ "VFrameFormat" BO_ 1084 14;
BA_ "FrameGatewayNetwork" BO_ 1068 "HS1_CAN";
BA_ "FrameGatewayId" BO_ 1068 1068;
BA_ "VFrameFormat" BO_ 1068 14;
BA_ "FrameGatewayNetwork" BO_ 146 "HS2_CAN";
BA_ "FrameGatewayId" BO_ 146 146;
BA_ "VFrameFormat" BO_ 146 14;
BA_ "GenMsgDelayTime" BO_ 1900 0;
BA_ "GenMsgSendType" BO_ 1900 1;
BA_ "DiagResponse" BO_ 1900 1;
BA_ "GenMsgILSupport" BO_ 1900 0;
BA_ "VFrameFormat" BO_ 1900 14;
BA_ "GenMsgDelayTime" BO_ 1806 0;
BA_ "GenMsgSendType" BO_ 1806 1;
BA_ "DiagResponse" BO_ 1806 1;
BA_ "GenMsgILSupport" BO_ 1806 0;
BA_ "VFrameFormat" BO_ 1806 14;
BA_ "FrameGatewayNetwork" BO_ 997 "HS2_CAN";
BA_ "FrameGatewayId" BO_ 997 997;
BA_ "GenMsgCycleTime" BO_ 997 1000;
BA_ "GenMsgSendType" BO_ 997 5;
BA_ "VFrameFormat" BO_ 997 14;
BA_ "FrameGatewayNetwork" BO_ 985 "HS2_CAN";
BA_ "FrameGatewayId" BO_ 985 985;
BA_ "VFrameFormat" BO_ 985 14;
BA_ "GenMsgCycleTime" BO_ 984 1000;
BA_ "GenMsgSendType" BO_ 984 5;
BA_ "VFrameFormat" BO_ 984 14;
BA_ "FrameGatewayNetwork" BO_ 983 "HS2_CAN";
BA_ "FrameGatewayId" BO_ 983 983;
BA_ "VFrameFormat" BO_ 983 14;
BA_ "GenMsgDelayTime" BO_ 980 10;
BA_ "GenMsgCycleTime" BO_ 980 30;
BA_ "GenMsgSendType" BO_ 980 0;
BA_ "VFrameFormat" BO_ 980 14;
BA_ "FrameGatewayNetwork" BO_ 979 "HS2_CAN";
BA_ "FrameGatewayId" BO_ 979 979;
BA_ "VFrameFormat" BO_ 979 14;
BA_ "GenMsgCycleTime" BO_ 976 100;
BA_ "GenMsgSendType" BO_ 976 0;
BA_ "VFrameFormat" BO_ 976 14;
BA_ "GenMsgCycleTime" BO_ 973 1000;
BA_ "GenMsgSendType" BO_ 973 5;
BA_ "VFrameFormat" BO_ 973 14;
BA_ "U_P702_MY2021_Rx" SG_ 936 ApaSys_D_Stat 1;
BA_ "U_P702_MY2021_Rx" SG_ 936 SAPPStatusCoding 1;
BA_ "CrossOver_InfoCAN" SG_ 936 SAPPStatusCoding 1;
BA_ "U_P702_MY2021_Rx" SG_ 936 EPASExtAngleStatReq 1;
BA_ "U_P702_MY2021_Rx" SG_ 936 ExtSteeringAngleReq2 1;
BA_ "GenSigStartValue" SG_ 877 RngImpctDrv_L_Dsply 255;
BA_ "GenSigStartValue" SG_ 877 RngImpctClim_L_Dsply 255;
BA_ "U_P702_MY2021_Tx" SG_ 877 VehElEffAvg_No_Dsply 1;
BA_ "GenSigStartValue" SG_ 877 VehElEffAvg_No_Dsply 126;
BA_ "U_P702_MY2021_Tx" SG_ 877 PwFlwFuelDrv_D_Dsply 1;
BA_ "CrossOver_InfoCAN" SG_ 877 PwFlwFuelDrv_D_Dsply 1;
BA_ "GenSigSendType" SG_ 877 PwFlwFuelDrv_D_Dsply 3;
BA_ "U_P702_MY2021_Tx" SG_ 877 PwFlwFuelClimt_B_Dsply 1;
BA_ "CrossOver_InfoCAN" SG_ 877 PwFlwFuelClimt_B_Dsply 1;
BA_ "GenSigSendType" SG_ 877 PwFlwFuelClimt_B_Dsply 3;
BA_ "U_P702_MY2021_Tx" SG_ 877 PwFlwFuelBatt_B_Dsply 1;
BA_ "CrossOver_InfoCAN" SG_ 877 PwFlwFuelBatt_B_Dsply 1;
BA_ "GenSigSendType" SG_ 877 PwFlwFuelBatt_B_Dsply 3;
BA_ "U_P702_MY2021_Tx" SG_ 877 PwFlwBattGen_D_Dsply 1;
BA_ "CrossOver_InfoCAN" SG_ 877 PwFlwBattGen_D_Dsply 1;
BA_ "GenSigSendType" SG_ 877 PwFlwBattGen_D_Dsply 3;
BA_ "U_P702_MY2021_Tx" SG_ 877 PwFlwBattClimt_B_Dsply 1;
BA_ "CrossOver_InfoCAN" SG_ 877 PwFlwBattClimt_B_Dsply 1;
BA_ "GenSigSendType" SG_ 877 PwFlwBattClimt_B_Dsply 3;
BA_ "U_P702_MY2021_Tx" SG_ 877 PwFlwBatt_D_Dsply 1;
BA_ "CrossOver_InfoCAN" SG_ 877 PwFlwBatt_D_Dsply 1;
BA_ "GenSigSendType" SG_ 877 PwFlwBatt_D_Dsply 3;
BA_ "U_P702_MY2021_Rx" SG_ 786 ChrgStat_D_Dsply 1;
BA_ "CrossOver_InfoCAN" SG_ 389 HtrnOvrTeLamp_B_Dsply 1;
BA_ "U_P702_MY2021_Rx" SG_ 389 HtrnAin_UHi_Actl 1;
BA_ "CrossOver_InfoCAN" SG_ 389 HtrnSrvcRqd_B_Dsply 1;
BA_ "U_P702_MY2021_Rx" SG_ 389 HtrnHvilOpen_B_Actl 1;
BA_ "GenSigStartValue" SG_ 389 BattTrac_I_EstVsc 15000;
BA_ "U_P702_MY2021_Rx" SG_ 1009 TrlrAidCancl_B_Rq 1;
BA_ "GenSigStartValue" SG_ 1009 CenterStackRing_D_Actl 2;
BA_ "CrossOver_InfoCAN" SG_ 1009 ValetMode_D_Stat 1;
BA_ "ContentDependant" SG_ 360 GsmSrvcRqd_B_Rq 1;
BA_ "CrossOver_InfoCAN" SG_ 360 GsmSrvcRqd_B_Rq 1;
BA_ "ContentDependant" SG_ 360 TrnTrcmPwmSig_D_Actl 1;
BA_ "CrossOver_InfoCAN" SG_ 360 TrnTrcmPwmSig_D_Actl 1;
BA_ "U_P702_MY2021_Rx" SG_ 360 TrnGearPwmFalt_B_Actl 1;
BA_ "ContentDependant" SG_ 360 TrnGearPwmFalt_B_Actl 1;
BA_ "CrossOver_InfoCAN" SG_ 360 TrnGearPwmFalt_B_Actl 1;
BA_ "U_P702_MY2021_Rx" SG_ 360 GearButtnStuck_B_Actl 1;
BA_ "ContentDependant" SG_ 360 GearButtnStuck_B_Actl 1;
BA_ "CrossOver_InfoCAN" SG_ 360 GearButtnStuck_B_Actl 1;
BA_ "GenSigStartValue" SG_ 122 BattTrac_U_LimLo 88;
BA_ "GenSigStartValue" SG_ 122 BattTrac_U_LimHi 163;
BA_ "GenSigStartValue" SG_ 122 BattTrac_U_Actl 1022;
BA_ "GenSigStartValue" SG_ 122 BattTrac_I_Actl 15000;
BA_ "CrossOver_InfoCAN" SG_ 122 BattTracOff_B_Actl 1;
BA_ "CrossOver_InfoCAN" SG_ 122 BattTracCnnct_B_Cmd 1;
BA_ "U_P702_MY2021_Rx" SG_ 122 VehStrtInhbt_B_RqBatt 1;
BA_ "CrossOver_InfoCAN" SG_ 122 VehStrtInhbt_B_RqBatt 1;
BA_ "U_P702_MY2021_Rx" SG_ 90 TrnGsmNtmState_D_Actl 1;
BA_ "ContentDependant" SG_ 90 TrnGsmNtmState_D_Actl 1;
BA_ "CrossOver_InfoCAN" SG_ 90 TrnGsmNtmState_D_Actl 1;
BA_ "U_P702_MY2021_Rx" SG_ 90 DrQltyDrv_D_StatGsm 1;
BA_ "ContentDependant" SG_ 90 DrQltyDrv_D_StatGsm 1;
BA_ "U_P702_MY2021_Rx" SG_ 90 TrnBtsiOvrrd_B_Stat 1;
BA_ "ContentDependant" SG_ 90 TrnBtsiOvrrd_B_Stat 1;
BA_ "U_P702_MY2021_Rx" SG_ 90 TrnRng_D_RqGsm 1;
BA_ "GenSigStartValue" SG_ 90 TrnRng_D_RqGsm 14;
BA_ "U_P702_MY2021_Rx" SG_ 90 PrkBrkActv_D_RqGsmGear 1;
BA_ "U_P702_MY2021_Rx" SG_ 90 TrnValidGearRq_D_Stat 1;
BA_ "ContentDependant" SG_ 90 TrnValidGearRq_D_Stat 1;
BA_ "U_P702_MY2021_Rx" SG_ 90 TrnGearRqCnt_B_Actl 1;
BA_ "ContentDependant" SG_ 90 TrnGearRqCnt_B_Actl 1;
BA_ "U_P702_MY2021_Rx" SG_ 90 TrnGearButtn_U_Actl 1;
BA_ "ContentDependant" SG_ 90 TrnGearButtn_U_Actl 1;
BA_ "WakeupSignal" SG_ 90 TrnGearButtn_U_Actl 1;
BA_ "U_P702_MY2021_Rx" SG_ 90 TrnGearButtn_B_ActlR2 1;
BA_ "ContentDependant" SG_ 90 TrnGearButtn_B_ActlR2 1;
BA_ "WakeupSignal" SG_ 90 TrnGearButtn_B_ActlR2 1;
BA_ "U_P702_MY2021_Rx" SG_ 90 TrnGearButtn_B_ActlR1 1;
BA_ "ContentDependant" SG_ 90 TrnGearButtn_B_ActlR1 1;
BA_ "WakeupSignal" SG_ 90 TrnGearButtn_B_ActlR1 1;
BA_ "U_P702_MY2021_Rx" SG_ 90 TrnGearButtn_B_ActlR0 1;
BA_ "ContentDependant" SG_ 90 TrnGearButtn_B_ActlR0 1;
BA_ "WakeupSignal" SG_ 90 TrnGearButtn_B_ActlR0 1;
BA_ "U_P702_MY2021_Rx" SG_ 90 TrnGearButtn_B_ActlP2 1;
BA_ "ContentDependant" SG_ 90 TrnGearButtn_B_ActlP2 1;
BA_ "WakeupSignal" SG_ 90 TrnGearButtn_B_ActlP2 1;
BA_ "U_P702_MY2021_Rx" SG_ 90 TrnGearButtn_B_ActlP1 1;
BA_ "ContentDependant" SG_ 90 TrnGearButtn_B_ActlP1 1;
BA_ "WakeupSignal" SG_ 90 TrnGearButtn_B_ActlP1 1;
BA_ "U_P702_MY2021_Rx" SG_ 90 TrnGearButtn_B_ActlP0 1;
BA_ "ContentDependant" SG_ 90 TrnGearButtn_B_ActlP0 1;
BA_ "WakeupSignal" SG_ 90 TrnGearButtn_B_ActlP0 1;
BA_ "U_P702_MY2021_Rx" SG_ 90 TrnGearButtn_B_ActlN2 1;
BA_ "ContentDependant" SG_ 90 TrnGearButtn_B_ActlN2 1;
BA_ "WakeupSignal" SG_ 90 TrnGearButtn_B_ActlN2 1;
BA_ "U_P702_MY2021_Rx" SG_ 90 TrnGearButtn_B_ActlN1 1;
BA_ "ContentDependant" SG_ 90 TrnGearButtn_B_ActlN1 1;
BA_ "WakeupSignal" SG_ 90 TrnGearButtn_B_ActlN1 1;
BA_ "U_P702_MY2021_Rx" SG_ 90 TrnGearButtn_B_ActlN0 1;
BA_ "ContentDependant" SG_ 90 TrnGearButtn_B_ActlN0 1;
BA_ "WakeupSignal" SG_ 90 TrnGearButtn_B_ActlN0 1;
BA_ "U_P702_MY2021_Rx" SG_ 90 TrnGearButtn_B_ActlM2 1;
BA_ "ContentDependant" SG_ 90 TrnGearButtn_B_ActlM2 1;
BA_ "WakeupSignal" SG_ 90 TrnGearButtn_B_ActlM2 1;
BA_ "U_P702_MY2021_Rx" SG_ 90 TrnGearButtn_B_ActlM1 1;
BA_ "ContentDependant" SG_ 90 TrnGearButtn_B_ActlM1 1;
BA_ "WakeupSignal" SG_ 90 TrnGearButtn_B_ActlM1 1;
BA_ "U_P702_MY2021_Rx" SG_ 90 TrnGearButtn_B_ActlM0 1;
BA_ "ContentDependant" SG_ 90 TrnGearButtn_B_ActlM0 1;
BA_ "WakeupSignal" SG_ 90 TrnGearButtn_B_ActlM0 1;
BA_ "U_P702_MY2021_Rx" SG_ 90 TrnGearButtn_B_ActlD2 1;
BA_ "ContentDependant" SG_ 90 TrnGearButtn_B_ActlD2 1;
BA_ "WakeupSignal" SG_ 90 TrnGearButtn_B_ActlD2 1;
BA_ "U_P702_MY2021_Rx" SG_ 90 TrnGearButtn_B_ActlD1 1;
BA_ "ContentDependant" SG_ 90 TrnGearButtn_B_ActlD1 1;
BA_ "WakeupSignal" SG_ 90 TrnGearButtn_B_ActlD1 1;
BA_ "U_P702_MY2021_Rx" SG_ 90 TrnGearButtn_B_ActlD0 1;
BA_ "ContentDependant" SG_ 90 TrnGearButtn_B_ActlD0 1;
BA_ "WakeupSignal" SG_ 90 TrnGearButtn_B_ActlD0 1;
BA_ "U_P702_MY2021_Rx" SG_ 90 TrnGear_No_Cs 1;
BA_ "MetaData" SG_ 90 TrnGear_No_Cs 1;
BA_ "ContentDependant" SG_ 90 TrnGear_No_Cs 1;
BA_ "U_P702_MY2021_Rx" SG_ 90 TrnGear_No_Cnt 1;
BA_ "MetaData" SG_ 90 TrnGear_No_Cnt 1;
BA_ "ContentDependant" SG_ 90 TrnGear_No_Cnt 1;
BA_ "U_P702_MY2021_Rx" SG_ 90 TrnGear_D_RqDrv 1;
BA_ "ContentDependant" SG_ 90 TrnGear_D_RqDrv 1;
BA_ "WakeupSignal" SG_ 90 TrnGear_D_RqDrv 1;
BA_ "U_P702_MY2021_Rx" SG_ 90 BrkSwtchPos_B_ActlGsm 1;
BA_ "ContentDependant" SG_ 90 BrkSwtchPos_B_ActlGsm 1;
BA_ "U_P702_MY2021_Rx" SG_ 1114 TrailCtlSwtch_B_Stat2 1;
BA_ "U_P702_MY2021_Rx" SG_ 1114 TrlrRvrseCancl_B_Rq 1;
BA_ "U_P702_MY2021_Rx" SG_ 1114 TrlrAnOffstDir_D_Mem 1;
BA_ "U_P702_MY2021_Rx" SG_ 1114 TrlrId_No_Actl 1;
BA_ "U_P702_MY2021_Rx" SG_ 1114 TrlrAxleToBmpr_L_Actl 1;
BA_ "U_P702_MY2021_Rx" SG_ 1114 TrlrAidEnbl_D_Rq 1;
BA_ "U_P702_MY2021_Rx" SG_ 1114 TrlrIdType_D_Stat 1;
BA_ "U_P702_MY2021_Rx" SG_ 1111 TrlrYawWActl_D_Qf 1;
BA_ "GenSigStartValue" SG_ 1111 TrlrYawWActl_D_Qf 1;
BA_ "U_P702_MY2021_Rx" SG_ 1111 TrlrYaw_W_Actl 1;
BA_ "GenSigStartValue" SG_ 1111 TrlrYaw_W_Actl 65534;
BA_ "U_P702_MY2021_Rx" SG_ 1111 TrlrHitYaw_AnRate_Actl 1;
BA_ "GenSigStartValue" SG_ 1111 TrlrHitYaw_AnRate_Actl 4094;
BA_ "U_P702_MY2021_Rx" SG_ 1111 TrlrHitchYaw_D_Stat 1;
BA_ "U_P702_MY2021_Rx" SG_ 1111 TrlrHitchYaw_An_Actl 1;
BA_ "GenSigStartValue" SG_ 1111 TrlrHitchYaw_An_Actl 4094;
BA_ "U_P702_MY2021_Rx" SG_ 1106 TrlrSnsId_No_Actl 1;
BA_ "ContentDependant" SG_ 1091 PoliceAux4Lamp_B_Rq2 1;
BA_ "CrossOver_InfoCAN" SG_ 1091 PoliceAux4Lamp_B_Rq2 1;
BA_ "ContentDependant" SG_ 1091 PoliceAux3Lamp_B_Rq2 1;
BA_ "CrossOver_InfoCAN" SG_ 1091 PoliceAux3Lamp_B_Rq2 1;
BA_ "ContentDependant" SG_ 1091 PoliceAux2Lamp_B_Rq2 1;
BA_ "CrossOver_InfoCAN" SG_ 1091 PoliceAux2Lamp_B_Rq2 1;
BA_ "ContentDependant" SG_ 1091 PoliceAux1Lamp_B_Rq2 1;
BA_ "CrossOver_InfoCAN" SG_ 1091 PoliceAux1Lamp_B_Rq2 1;
BA_ "CrossOver_InfoCAN" SG_ 1091 ParkLampTrlrOut_B_Stat 1;
BA_ "CrossOver_InfoCAN" SG_ 1091 TrlrLampCtl_D_Stat 1;
BA_ "CrossOver_InfoCAN" SG_ 1091 TrlrBattChrg_D_Stat 1;
BA_ "CrossOver_InfoCAN" SG_ 1091 StopLampTrlrOut_B_Stat 1;
BA_ "CrossOver_InfoCAN" SG_ 1091 TurnLampTrlrRr_B_Stat 1;
BA_ "CrossOver_InfoCAN" SG_ 1091 TurnLampTrlrRl_B_Stat 1;
BA_ "U_P702_MY2021_Rx" SG_ 1091 TrlrLampCnnct_B_Actl 1;
BA_ "CrossOver_InfoCAN" SG_ 1091 TrlrLampCnnct_B_Actl 1;
BA_ "U_P702_MY2021_Rx" SG_ 138 SteWhlRelCalib_T_Actl 1;
BA_ "U_P702_MY2021_Rx" SG_ 138 SteWhlRelCalib_An_Sns 1;
BA_ "ContentDependant" SG_ 138 SteWhlRelCalib_An_Sns 1;
BA_ "U_P702_MY2021_Rx" SG_ 131 HeadLghtHiCtrl_D_RqAhb 1;
BA_ "WakeupSignal" SG_ 131 HeadLghtHiCtrl_D_RqAhb 1;
BA_ "GenSigStartValue" SG_ 131 WiprFrontSwtch_D_Stat 9;
BA_ "CrossOver_InfoCAN" SG_ 131 HeadLghtHiOn_B_StatAhb 1;
BA_ "WakeupSignal" SG_ 131 HeadLghtHiOn_B_StatAhb 1;
BA_ "WakeupSignal" SG_ 131 HeadLghtHiFlash_D_Stat 1;
BA_ "U_P702_MY2021_Rx" SG_ 131 WiprFront_D_Stat 1;
BA_ "GenSigStartValue" SG_ 131 WiprFront_D_Stat 15;
BA_ "U_P702_MY2021_Rx" SG_ 131 TurnLghtSwtch_D_Stat 1;
BA_ "CrossOver_InfoCAN" SG_ 131 TurnLghtSwtch_D_Stat 1;
BA_ "WakeupSignal" SG_ 131 TurnLghtSwtch_D_Stat 1;
BA_ "U_P702_MY2021_Rx" SG_ 131 LghtAmb_D_Sns 1;
BA_ "GenSigStartValue" SG_ 131 LghtAmb_D_Sns 7;
BA_ "U_P702_MY2021_Rx" SG_ 131 AslButtnOnOffPress 1;
BA_ "U_P702_MY2021_Rx" SG_ 131 AslButtnOnOffCnclPress 1;
BA_ "U_P702_MY2021_Rx" SG_ 131 CcButtnOnPress 1;
BA_ "U_P702_MY2021_Rx" SG_ 131 CcButtnOnOffPress 1;
BA_ "U_P702_MY2021_Rx" SG_ 131 CcButtnOnOffCnclPress 1;
BA_ "U_P702_MY2021_Rx" SG_ 131 CcButtnOffPress 1;
BA_ "U_P702_MY2021_Rx" SG_ 131 CcAsllButtnResPress 1;
BA_ "U_P702_MY2021_Rx" SG_ 131 CcAslButtnSetIncPress 1;
BA_ "U_P702_MY2021_Rx" SG_ 131 CcAslButtnSetDecPress 1;
BA_ "U_P702_MY2021_Rx" SG_ 131 CcAslButtnResIncPress 1;
BA_ "U_P702_MY2021_Rx" SG_ 131 CcAslButtnOnPress 1;
BA_ "U_P702_MY2021_Rx" SG_ 131 CcAslButtnIndxIncPress 1;
BA_ "U_P702_MY2021_Rx" SG_ 131 CcAslButtnIndxDecPress 1;
BA_ "U_P702_MY2021_Rx" SG_ 131 CcAslButtnDeny_B_Actl 1;
BA_ "U_P702_MY2021_Rx" SG_ 131 CcAslButtnCnclResPress 1;
BA_ "U_P702_MY2021_Rx" SG_ 131 CcAslButtnCnclPress 1;
BA_ "GenSigStartValue" SG_ 953 WakeAlarm3_D_Stat 3;
BA_ "GenSigStartValue" SG_ 953 WakeAlarm2_D_Stat 3;
BA_ "U_P702_MY2021_Rx" SG_ 953 WakeAlarm1_D_Stat 1;
BA_ "GenSigStartValue" SG_ 953 WakeAlarm1_D_Stat 3;
BA_ "GenSigStartValue" SG_ 953 WakeAlarm0_D_Stat 3;
BA_ "U_P702_MY2021_Rx" SG_ 1093 TrlrBrkActCnnct_B_Actl 1;
BA_ "ContentDependant" SG_ 1093 StopLamp_B_RqTrlrBrk 1;
BA_ "U_P702_MY2021_Rx" SG_ 792 FuelRange_L_Dsply 1;
BA_ "ContentDependant" SG_ 792 ElTrip_L_Dsply 1;
BA_ "ContentDependant" SG_ 792 ElLongTerm_L_Dsply 1;
BA_ "GenSigStartValue" SG_ 968 CurrentColor_CmdGage 8;
BA_ "GenSigStartValue" SG_ 968 BlendedColor_CmdGage 2;
BA_ "GenSigStartValue" SG_ 968 Current_Color_Cmd 8;
BA_ "GenSigStartValue" SG_ 968 BlendedColor_Cmd 2;
BA_ "U_P702_MY2021_Rx" SG_ 968 SlMde_D_Rq 1;
BA_ "GenSigStartValue" SG_ 968 SlMde_D_Rq 2;
BA_ "U_P702_MY2021_Rx" SG_ 968 IsaOffst_D_Rq 1;
BA_ "GenSigStartValue" SG_ 968 IsaOffst_D_Rq 14;
BA_ "WakeupSignal" SG_ 819 Memory_3_SwPsngr_Stat 1;
BA_ "WakeupSignal" SG_ 819 Memory_2_SwPsngr_Stat 1;
BA_ "WakeupSignal" SG_ 819 Memory_1_SwPsngr_Stat 1;
BA_ "U_P702_MY2021_Rx" SG_ 819 WndwPsngrSide_D_Stat 1;
BA_ "WakeupSignal" SG_ 819 Pasngr_Lock_Sw_Stat 1;
BA_ "MetaData" SG_ 819 Pasngr_Lock_Sw_Cnt 1;
BA_ "WakeupSignal" SG_ 819 Pasngr_Lock_Sw_Cnt 1;
BA_ "WakeupSignal" SG_ 819 ChildLckFdbckRp_B_Stat 1;
BA_ "WakeupSignal" SG_ 818 ChildLckPw_N_Cnt 1;
BA_ "U_P702_MY2021_Rx" SG_ 818 WndwDrvSide_D_Stat 1;
BA_ "WakeupSignal" SG_ 818 KeyCylSwDrvDr_D_Stat 1;
BA_ "WakeupSignal" SG_ 818 Driver_Lock_Sw_Stat 1;
BA_ "MetaData" SG_ 818 Driver_Lock_Sw_Cnt 1;
BA_ "WakeupSignal" SG_ 818 Driver_Lock_Sw_Cnt 1;
BA_ "WakeupSignal" SG_ 818 ChildLckPw_D_Rq 1;
BA_ "WakeupSignal" SG_ 818 ChildLckFdbckRd_B_Stat 1;
BA_ "CrossOver_InfoCAN" SG_ 818 RvrseMirrorChime_B_Rq 1;
BA_ "GenSigStartValue" SG_ 806 ClimtDeltaLoad_Pw_Actl 32;
BA_ "U_P702_MY2021_Rx" SG_ 806 StopStrtDrvMde_B_RqBtn 1;
BA_ "U_P702_MY2021_Rx" SG_ 806 HvacHtrCore_Te_Rq 1;
BA_ "U_P702_MY2021_Rx" SG_ 806 ClimtHeat_D_Rq 1;
BA_ "U_P702_MY2021_Rx" SG_ 806 ClimtCool_D_Rq 1;
BA_ "U_P702_MY2021_Rx" SG_ 806 HvacEvap_Te_Rq 1;
BA_ "GenSigStartValue" SG_ 806 HvacEvap_Te_Rq 400;
BA_ "U_P702_MY2021_Rx" SG_ 806 HvacEvap_Te_Actl 1;
BA_ "GenSigStartValue" SG_ 806 HvacEvap_Te_Actl 400;
BA_ "U_P702_MY2021_Rx" SG_ 806 HvacAirCond_B_Rq 1;
BA_ "U_P702_MY2021_Rx" SG_ 806 HvacEvap_Te_Offst 1;
BA_ "GenSigStartValue" SG_ 806 HvacEvap_Te_Offst 400;
BA_ "U_P702_MY2021_Rx" SG_ 806 ClimtPw_B_Rq 1;
BA_ "GenSigStartValue" SG_ 765 BalrSwtch_D_Stat 1;
BA_ "U_P702_MY2021_Rx" SG_ 765 WaitToStartLamp_D_Falt 1;
BA_ "GenSigStartValue" SG_ 765 WaitToStartLamp_D_Falt 1;
BA_ "U_P702_MY2021_Rx" SG_ 765 EsaOn_B_Rq 1;
BA_ "GenSigStartValue" SG_ 765 EsaOn_B_Rq 1;
BA_ "GenSigStartValue" SG_ 765 Btt_L_Actl 126;
BA_ "U_P702_MY2021_Rx" SG_ 765 RearDiffLck_D_RqArb 1;
BA_ "GenSigStartValue" SG_ 765 RearDiffLck_D_RqArb 3;
BA_ "U_P702_MY2021_Rx" SG_ 765 AwdMde_D_RqArb 1;
BA_ "GenSigStartValue" SG_ 765 AwdMde_D_RqArb 5;
BA_ "U_P702_MY2021_Rx" SG_ 765 SelDrvMdeTxtReset_B_Rq 1;
BA_ "WakeupSignal" SG_ 765 DrvInputRequired_B_Rq 1;
BA_ "U_P702_MY2021_Rx" SG_ 765 SelDrvMdeDsply_B_Avail 1;
BA_ "GenSigStartValue" SG_ 765 EngExhMdeQuiet_D_Rq 2;
BA_ "CrossOver_InfoCAN" SG_ 765 Mc_VehUnitTempUsrSel_St 1;
BA_ "U_P702_MY2021_Rx" SG_ 765 AwdRnge_D_ActlIpc 1;
BA_ "GenSigStartValue" SG_ 765 AwdRnge_D_ActlIpc 7;
BA_ "CrossOver_InfoCAN" SG_ 765 AwdRnge_D_ActlIpc 1;
BA_ "U_P702_MY2021_Rx" SG_ 765 EdmSailMde_B_RqDrv 1;
BA_ "U_P702_MY2021_Rx" SG_ 559 EhData2_No_Actl 1;
BA_ "CrossOver_InfoCAN" SG_ 559 EhData2_No_Actl 1;
BA_ "U_P702_MY2021_Rx" SG_ 558 EhData1_No_Actl 1;
BA_ "CrossOver_InfoCAN" SG_ 558 EhData1_No_Actl 1;
BA_ "CrossOver_InfoCAN" SG_ 934 RbaCtaLeft_D_Stat 1;
BA_ "GenSigSendType" SG_ 934 RbaCtaLeft_D_Stat 3;
BA_ "GenSigSendType" SG_ 934 CtaAlrtLeft2_D_Stat 3;
BA_ "GenSigSendType" SG_ 934 CtaBrkLeftMsgTxt_B_Rq 3;
BA_ "U_P702_MY2021_Rx" SG_ 934 CtaLeftBrkDecel_B_Rq 1;
BA_ "GenSigSendType" SG_ 934 CtaLeftBrkDecel_B_Rq 3;
BA_ "U_P702_MY2021_Rx" SG_ 934 CtaLeftBrkEnbl_B_Rq 1;
BA_ "GenSigSendType" SG_ 934 CtaLeftBrkEnbl_B_Rq 3;
BA_ "GenSigStartValue" SG_ 934 Side_Detect_L_Illum 100;
BA_ "CrossOver_InfoCAN" SG_ 934 Side_Detect_L_Illum 1;
BA_ "GenSigSendType" SG_ 934 BttLeft_D_Stat 3;
BA_ "GenSigSendType" SG_ 934 BttLeft_D_RqDrv 3;
BA_ "CrossOver_InfoCAN" SG_ 934 CtaInnrLeft_D_Stat 1;
BA_ "GenSigSendType" SG_ 934 CtaInnrLeft_D_Stat 3;
BA_ "CrossOver_InfoCAN" SG_ 934 CtaSnsLeft_D_Stat 1;
BA_ "GenSigSendType" SG_ 934 CtaSnsLeft_D_Stat 3;
BA_ "CrossOver_InfoCAN" SG_ 934 SodDetctLeft_D_Stat 1;
BA_ "GenSigSendType" SG_ 934 SodDetctLeft_D_Stat 3;
BA_ "CrossOver_InfoCAN" SG_ 934 CtaLeft_D_Stat 1;
BA_ "GenSigSendType" SG_ 934 CtaLeft_D_Stat 3;
BA_ "CrossOver_InfoCAN" SG_ 934 CtaAlrtLeft_D_Stat 1;
BA_ "GenSigSendType" SG_ 934 CtaAlrtLeft_D_Stat 3;
BA_ "GenSigStartValue" SG_ 934 SodLeft_D_Stat 2;
BA_ "CrossOver_InfoCAN" SG_ 934 SodLeft_D_Stat 1;
BA_ "GenSigSendType" SG_ 934 SodLeft_D_Stat 3;
BA_ "CrossOver_InfoCAN" SG_ 934 SodSnsLeft_D_Stat 1;
BA_ "GenSigSendType" SG_ 934 SodSnsLeft_D_Stat 3;
BA_ "CrossOver_InfoCAN" SG_ 934 SodAlrtLeft_D_Stat 1;
BA_ "GenSigSendType" SG_ 934 SodAlrtLeft_D_Stat 3;
BA_ "GenSigStartValue" SG_ 934 SodWarnLeft_Prd_Rq 14;
BA_ "CrossOver_InfoCAN" SG_ 934 SodWarnLeft_Prd_Rq 1;
BA_ "CrossOver_InfoCAN" SG_ 934 SodInnrLeft_D_Stat 1;
BA_ "GenSigSendType" SG_ 934 SodInnrLeft_D_Stat 3;
BA_ "GenSigSendType" SG_ 934 LcwaDetctLeft2_B_Stat 3;
BA_ "GenSigSendType" SG_ 934 LcwaDetctLeft1_B_Stat 3;
BA_ "U_P702_MY2021_Rx" SG_ 1072 DrvSlipCtlMde_D_Rq 1;
BA_ "CrossOver_InfoCAN" SG_ 1072 DrvSlipCtlMde_D_Rq 1;
BA_ "U_P702_MY2021_Rx" SG_ 1072 EngIdlShutDown_B_RqDrv 1;
BA_ "GenSigStartValue" SG_ 1072 HsaMde_D_Rq 1;
BA_ "CrossOver_InfoCAN" SG_ 1072 HsaMde_D_Rq 1;
BA_ "U_P702_MY2021_Rx" SG_ 1072 StopStrtDrvMde_D_RqMnu 1;
BA_ "CrossOver_InfoCAN" SG_ 1072 StopStrtDrvMde_D_RqMnu 1;
BA_ "U_P702_MY2021_Rx" SG_ 1072 NtrlTowMdeEnbl_B_RqDrv 1;
BA_ "CrossOver_InfoCAN" SG_ 1072 NtrlTowMdeEnbl_B_RqDrv 1;
BA_ "CrossOver_InfoCAN" SG_ 1072 LscmbbStat_B_Actl 1;
BA_ "CrossOver_InfoCAN" SG_ 1072 BulbChkActv_B_Stat 1;
BA_ "CrossOver_InfoCAN" SG_ 1072 ParkDetect_Stat 1;
BA_ "CrossOver_InfoCAN" SG_ 1072 ReducedGuard_D_Rq 1;
BA_ "U_P702_MY2021_Rx" SG_ 1072 FrostWarn_D_Stat 1;
BA_ "CrossOver_InfoCAN" SG_ 1072 FrostWarn_D_Stat 1;
BA_ "U_P702_MY2021_Rx" SG_ 1072 TRLR_SWAY_CONFIG_CMD 1;
BA_ "CrossOver_InfoCAN" SG_ 1072 Power_Liftgate_Mode_Cmd 1;
BA_ "WakeupSignal" SG_ 1072 Power_Liftgate_Mode_Cmd 1;
BA_ "GenSigStartValue" SG_ 1072 AccEnbl_B_RqDrv 1;
BA_ "CrossOver_InfoCAN" SG_ 1072 AccEnbl_B_RqDrv 1;
BA_ "CrossOver_InfoCAN" SG_ 1072 EmgcyCallAsstMykey_Rq 1;
BA_ "U_P702_MY2021_Rx" SG_ 1072 OdometerMasterValue 1;
BA_ "CrossOver_InfoCAN" SG_ 1072 OdometerMasterValue 1;
BA_ "U_P702_MY2021_Rx" SG_ 1072 EngOilLife_B_RqReset 1;
BA_ "CrossOver_InfoCAN" SG_ 1072 EngOilLife_B_RqReset 1;
BA_ "CrossOver_InfoCAN" SG_ 1072 MetricActvTe_B_Actl 1;
BA_ "CrossOver_InfoCAN" SG_ 1072 AccDeny_B_RqIpc 1;
BA_ "U_P702_MY2021_Rx" SG_ 1072 ePRNDL_MODE 1;
BA_ "CrossOver_InfoCAN" SG_ 1072 ePRNDL_MODE 1;
BA_ "WakeupSignal" SG_ 1072 ePRNDL_MODE 1;
BA_ "U_P702_MY2021_Rx" SG_ 1072 DrvSlipCtlMde_B_Rq2 1;
BA_ "CrossOver_InfoCAN" SG_ 1072 DrvSlipCtlMde_B_Rq2 1;
BA_ "CrossOver_InfoCAN" SG_ 1072 Fda_B_Stat 1;
BA_ "U_P702_MY2021_Rx" SG_ 1072 MetricActv_B_Actl 1;
BA_ "CrossOver_InfoCAN" SG_ 1072 MetricActv_B_Actl 1;
BA_ "CrossOver_InfoCAN" SG_ 1072 KeyTypeChngMykey_D_Rq 1;
BA_ "U_P702_MY2021_Rx" SG_ 1072 ManRgen_D_Rq 1;
BA_ "CrossOver_InfoCAN" SG_ 1072 ManRgen_D_Rq 1;
BA_ "WakeupSignal" SG_ 909 IgnPsswrdDsply_B_Rq 1;
BA_ "WakeupSignal" SG_ 909 ElPwPoint_D_Rq 1;
BA_ "CrossOver_InfoCAN" SG_ 909 SecurityMsgTxt_D_Rq 1;
BA_ "U_P702_MY2021_Rx" SG_ 909 HeadLghtHiPrmsn_D_Stat 1;
BA_ "GenSigStartValue" SG_ 909 HeadLghtHiPrmsn_D_Stat 3;
BA_ "CrossOver_InfoCAN" SG_ 909 SteWhlLckMsgTxt_D_Rq 1;
BA_ "CrossOver_InfoCAN" SG_ 909 immoMsgTxt_D_Rq 1;
BA_ "WakeupSignal" SG_ 909 immoMsgTxt_D_Rq 1;
BA_ "CrossOver_InfoCAN" SG_ 909 PEBackupSlot_Stats 1;
BA_ "MetaData" SG_ 909 KeyMykeyTot_No_Cnt 1;
BA_ "CrossOver_InfoCAN" SG_ 909 KeyMykeyTot_No_Cnt 1;
BA_ "CrossOver_InfoCAN" SG_ 909 Keycode_Status 1;
BA_ "MetaData" SG_ 909 KeyAdmnTot_No_Cnt 1;
BA_ "CrossOver_InfoCAN" SG_ 909 KeyAdmnTot_No_Cnt 1;
BA_ "CrossOver_InfoCAN" SG_ 963 ImpactEvntFdbck_D_Stat 1;
BA_ "WakeupSignal" SG_ 963 ImpactEvntFdbck_D_Stat 1;
BA_ "CrossOver_InfoCAN" SG_ 963 HeadLampLoOut_B_Stat 1;
BA_ "U_P702_MY2021_Rx" SG_ 963 CrnrLghtRight_Pc_Rq 1;
BA_ "CrossOver_InfoCAN" SG_ 963 CrnrLghtRight_Pc_Rq 1;
BA_ "U_P702_MY2021_Rx" SG_ 963 CrnrLghtLeft_Pc_Rq 1;
BA_ "CrossOver_InfoCAN" SG_ 963 CrnrLghtLeft_Pc_Rq 1;
BA_ "CrossOver_InfoCAN" SG_ 963 HeadLghtHiFdbck_D_Stat 1;
BA_ "CrossOver_InfoCAN" SG_ 963 TrnNotInPrkChime_B_Rq 1;
BA_ "CrossOver_InfoCAN" SG_ 963 PrkLightChime_B_Rq 1;
BA_ "CrossOver_InfoCAN" SG_ 963 KeyInIgnWarn_B_Cmd 1;
BA_ "WakeupSignal" SG_ 963 KeyInIgnWarn_B_Cmd 1;
BA_ "CrossOver_InfoCAN" SG_ 963 HomeSafeLtChime_B_Rq 1;
BA_ "WakeupSignal" SG_ 963 HomeSafeLtChime_B_Rq 1;
BA_ "U_P702_MY2021_Rx" SG_ 963 StopLghtOn_B_Stat 1;
BA_ "CrossOver_InfoCAN" SG_ 963 StopLghtOn_B_Stat 1;
BA_ "WakeupSignal" SG_ 963 StopLghtOn_B_Stat 1;
BA_ "CrossOver_InfoCAN" SG_ 963 RvrseLghtOn_B_Stat 1;
BA_ "CrossOver_InfoCAN" SG_ 963 PrkLght_D_Stat 1;
BA_ "WakeupSignal" SG_ 963 PrkLght_D_Stat 1;
BA_ "U_P702_MY2021_Rx" SG_ 963 HeadLghtSwtch_D_Stat 1;
BA_ "GenSigStartValue" SG_ 963 HeadLghtSwtch_D_Stat 2;
BA_ "CrossOver_InfoCAN" SG_ 963 HeadLghtSwtch_D_Stat 1;
BA_ "WakeupSignal" SG_ 963 HeadLghtSwtch_D_Stat 1;
BA_ "U_P702_MY2021_Rx" SG_ 963 HeadLampLoFrOn_B_Stat 1;
BA_ "GenSigStartValue" SG_ 963 HeadLampLoFrOn_B_Stat 1;
BA_ "CrossOver_InfoCAN" SG_ 963 HeadLampLoFrOn_B_Stat 1;
BA_ "U_P702_MY2021_Rx" SG_ 963 HeadLampLoFlOn_B_Stat 1;
BA_ "GenSigStartValue" SG_ 963 HeadLampLoFlOn_B_Stat 1;
BA_ "CrossOver_InfoCAN" SG_ 963 HeadLampLoFlOn_B_Stat 1;
BA_ "U_P702_MY2021_Rx" SG_ 963 HeadLampLoActv_B_Stat 1;
BA_ "GenSigStartValue" SG_ 963 HeadLampLoActv_B_Stat 1;
BA_ "CrossOver_InfoCAN" SG_ 963 HeadLampLoActv_B_Stat 1;
BA_ "CrossOver_InfoCAN" SG_ 963 Headlamp_On_Wrning_Cmd 1;
BA_ "WakeupSignal" SG_ 963 Headlamp_On_Wrning_Cmd 1;
BA_ "CrossOver_InfoCAN" SG_ 963 Park_Brake_Chime_Rqst 1;
BA_ "U_P702_MY2021_Rx" SG_ 963 HeadLghtHiOn_B_Stat 1;
BA_ "CrossOver_InfoCAN" SG_ 963 HeadLghtHiOn_B_Stat 1;
BA_ "WakeupSignal" SG_ 963 HeadLghtHiOn_B_Stat 1;
BA_ "CrossOver_InfoCAN" SG_ 963 BrkWarnInd_B_Rq 1;
BA_ "WakeupSignal" SG_ 963 BrkWarnInd_B_Rq 1;
BA_ "CrossOver_InfoCAN" SG_ 963 Brk_Fluid_Lvl_Low 1;
BA_ "CrossOver_InfoCAN" SG_ 963 ReducedGuard_D_Stat 1;
BA_ "CrossOver_InfoCAN" SG_ 963 Perimeter_Alarm_Status 1;
BA_ "WakeupSignal" SG_ 963 Perimeter_Alarm_Status 1;
BA_ "GenSigStartValue" SG_ 963 Courtesy_BSave_Stat 1;
BA_ "CrossOver_InfoCAN" SG_ 963 Courtesy_BSave_Stat 1;
BA_ "WakeupSignal" SG_ 963 Courtesy_BSave_Stat 1;
BA_ "CrossOver_InfoCAN" SG_ 963 WndwGlbl_D_Cmd 1;
BA_ "WakeupSignal" SG_ 963 WndwGlbl_D_Cmd 1;
BA_ "CrossOver_InfoCAN" SG_ 963 PudLamp_D_Rq 1;
BA_ "WakeupSignal" SG_ 963 PudLamp_D_Rq 1;
BA_ "U_P702_MY2021_Rx" SG_ 963 DayRnngLampOn_B_Stat 1;
BA_ "CrossOver_InfoCAN" SG_ 963 DayRnngLampOn_B_Stat 1;
BA_ "CrossOver_InfoCAN" SG_ 963 PerimeterAlarmChimeRq 1;
BA_ "WakeupSignal" SG_ 963 PerimeterAlarmChimeRq 1;
BA_ "U_P702_MY2021_Rx" SG_ 145 VehYawWActl_D_Qf 1;
BA_ "MetaData" SG_ 145 VehYawWActl_D_Qf 1;
BA_ "GenSigStartValue" SG_ 145 VehYawWActl_D_Qf 1;
BA_ "U_P702_MY2021_Rx" SG_ 145 VehRolWActl_D_Qf 1;
BA_ "MetaData" SG_ 145 VehRolWActl_D_Qf 1;
BA_ "GenSigStartValue" SG_ 145 VehRolWActl_D_Qf 1;
BA_ "U_P702_MY2021_Rx" SG_ 145 VehRollYawW_No_Cs 1;
BA_ "MetaData" SG_ 145 VehRollYawW_No_Cs 1;
BA_ "U_P702_MY2021_Rx" SG_ 145 VehRollYaw_No_Cnt 1;
BA_ "MetaData" SG_ 145 VehRollYaw_No_Cnt 1;
BA_ "U_P702_MY2021_Rx" SG_ 145 VehYaw_W_Actl 1;
BA_ "GenSigStartValue" SG_ 145 VehYaw_W_Actl 65534;
BA_ "U_P702_MY2021_Rx" SG_ 145 VehRol_W_Actl 1;
BA_ "GenSigStartValue" SG_ 145 VehRol_W_Actl 65534;
BA_ "GenSigStartValue" SG_ 76 PsngrFmidDetct_D_Actl 3;
BA_ "GenSigStartValue" SG_ 76 FirstRowBuckleMid 3;
BA_ "CrossOver_InfoCAN" SG_ 76 FirstRowBuckleMid 1;
BA_ "GenSigStartValue" SG_ 76 ThirdRowBucklePsngr 3;
BA_ "CrossOver_InfoCAN" SG_ 76 ThirdRowBucklePsngr 1;
BA_ "GenSigStartValue" SG_ 76 ThirdRowBuckleMid 3;
BA_ "CrossOver_InfoCAN" SG_ 76 ThirdRowBuckleMid 1;
BA_ "GenSigStartValue" SG_ 76 ThirdRowBuckleDriver 3;
BA_ "CrossOver_InfoCAN" SG_ 76 ThirdRowBuckleDriver 1;
BA_ "GenSigStartValue" SG_ 76 SecondRowBucklePsngr 3;
BA_ "CrossOver_InfoCAN" SG_ 76 SecondRowBucklePsngr 1;
BA_ "GenSigStartValue" SG_ 76 SecondRowBuckleMid 3;
BA_ "CrossOver_InfoCAN" SG_ 76 SecondRowBuckleMid 1;
BA_ "GenSigStartValue" SG_ 76 SecondRowBuckleDriver 3;
BA_ "CrossOver_InfoCAN" SG_ 76 SecondRowBuckleDriver 1;
BA_ "U_P702_MY2021_Rx" SG_ 76 FirstRowBuckleDriver 1;
BA_ "GenSigStartValue" SG_ 76 FirstRowBuckleDriver 3;
BA_ "CrossOver_InfoCAN" SG_ 76 FirstRowBuckleDriver 1;
BA_ "CrossOver_InfoCAN" SG_ 76 RILReq 1;
BA_ "GenSigStartValue" SG_ 76 FirstRowBucklePsngr 3;
BA_ "CrossOver_InfoCAN" SG_ 76 FirstRowBucklePsngr 1;
BA_ "U_P702_MY2021_Rx" SG_ 76 RstrnImpactEvntStatus 1;
BA_ "CrossOver_InfoCAN" SG_ 76 RstrnImpactEvntStatus 1;
BA_ "WakeupSignal" SG_ 76 RstrnImpactEvntStatus 1;
BA_ "GenSigStartValue" SG_ 76 PsngrFrntDetct_D_Actl 3;
BA_ "CrossOver_InfoCAN" SG_ 76 PsngrFrntDetct_D_Actl 1;
BA_ "CrossOver_InfoCAN" SG_ 76 EDRTriggerEvntSync 1;
BA_ "GenSigStartValue" SG_ 76 PassRstrnInd_Req 3;
BA_ "CrossOver_InfoCAN" SG_ 76 PassRstrnInd_Req 1;
BA_ "U_P702_MY2021_Rx" SG_ 65 immoControlData_T1 1;
BA_ "U_P702_MY2021_Rx" SG_ 65 immoControlCmd_T1 1;
BA_ "U_P702_MY2021_Rx" SG_ 1076 AutoRgen_D_Rq 1;
BA_ "GenSigStartValue" SG_ 1076 W2S_LAMP_OK 1;
BA_ "U_P702_MY2021_Rx" SG_ 1076 OdoTripRx_B_Actl 1;
BA_ "CrossOver_InfoCAN" SG_ 1076 OdoTripRx_B_Actl 1;
BA_ "U_P702_MY2021_Rx" SG_ 1076 Veh_V_CompLimMx 1;
BA_ "GenSigStartValue" SG_ 1076 Veh_V_CompLimMx 4095;
BA_ "CrossOver_InfoCAN" SG_ 1076 Veh_V_CompLimMx 1;
BA_ "CrossOver_InfoCAN" SG_ 1076 DrvSlipCtlMde_B_RqMyKey 1;
BA_ "CrossOver_InfoCAN" SG_ 1076 FuelLvlWarn_D_Actl 1;
BA_ "U_P702_MY2021_Rx" SG_ 1076 DieslFuelBio_B_ActlDrv 1;
BA_ "CrossOver_InfoCAN" SG_ 1076 DieslFuelBio_B_ActlDrv 1;
BA_ "CrossOver_InfoCAN" SG_ 1076 FuelSecndActv_B_Actl 1;
BA_ "U_P702_MY2021_Rx" SG_ 1076 HILL_DESC_SW 1;
BA_ "CrossOver_InfoCAN" SG_ 1076 HILL_DESC_SW 1;
BA_ "U_P702_MY2021_Rx" SG_ 1076 FuelLvlPssvSide_No_Raw 1;
BA_ "CrossOver_InfoCAN" SG_ 1076 FuelLvlPssvSide_No_Raw 1;
BA_ "U_P702_MY2021_Rx" SG_ 1076 FUEL_SENSOR_NUM 1;
BA_ "CrossOver_InfoCAN" SG_ 1076 FUEL_SENSOR_NUM 1;
BA_ "U_P702_MY2021_Rx" SG_ 1076 FuelLvlActvSide_No_Raw 1;
BA_ "CrossOver_InfoCAN" SG_ 1076 FuelLvlActvSide_No_Raw 1;
BA_ "U_P702_MY2021_Rx" SG_ 1076 FuelLvl_Pc_Dsply 1;
BA_ "CrossOver_InfoCAN" SG_ 1076 FuelLvl_Pc_Dsply 1;
BA_ "U_P702_MY2021_Rx" SG_ 1076 DISPLAY_SPEED_SCALING 1;
BA_ "CrossOver_InfoCAN" SG_ 1076 DISPLAY_SPEED_SCALING 1;
BA_ "CrossOver_InfoCAN" SG_ 1076 TirePReset_B_Rq 1;
BA_ "U_P702_MY2021_Rx" SG_ 1076 DISPLAY_SPEED_OFFSET 1;
BA_ "CrossOver_InfoCAN" SG_ 1076 DISPLAY_SPEED_OFFSET 1;
BA_ "U_P702_MY2021_Rx" SG_ 862 HvacBlwrFront_D_Stat 1;
BA_ "U_P702_MY2021_Rx" SG_ 862 HvacBlwrRear_D_Stat 1;
BA_ "U_P702_MY2021_Rx" SG_ 862 CabnAmb_Te_Actl 1;
BA_ "GenSigStartValue" SG_ 862 CabnAmb_Te_Actl 114;
BA_ "U_P702_MY2021_Rx" SG_ 862 HvacRemoteStrt_N_Rq 1;
BA_ "U_P702_MY2021_Rx" SG_ 862 ClimtThrmlLoad_No_Actl 1;
BA_ "GenSigStartValue" SG_ 862 ClimtThrmlLoad_No_Actl 255;
BA_ "U_P702_MY2021_Rx" SG_ 931 CrnkInhbt_No_Cs 1;
BA_ "MetaData" SG_ 931 CrnkInhbt_No_Cs 1;
BA_ "ContentDependant" SG_ 931 CrnkInhbt_No_Cs 1;
BA_ "U_P702_MY2021_Rx" SG_ 931 CrnkInhbt_No_Cnt 1;
BA_ "MetaData" SG_ 931 CrnkInhbt_No_Cnt 1;
BA_ "ContentDependant" SG_ 931 CrnkInhbt_No_Cnt 1;
BA_ "U_P702_MY2021_Rx" SG_ 931 CrnkInhbt_B_Stat 1;
BA_ "GenSigStartValue" SG_ 931 CrnkInhbt_B_Stat 1;
BA_ "U_P702_MY2021_Rx" SG_ 931 IgnPreOffActv_B_Stat 1;
BA_ "U_P702_MY2021_Rx" SG_ 578 PtLatchActv_B_RqBcm 1;
BA_ "U_P702_MY2021_Rx" SG_ 578 immoSecureIdleMode 1;
BA_ "WakeupSignal" SG_ 578 ReFuelSwtchStat_D_Actl 1;
BA_ "U_P702_MY2021_Rx" SG_ 578 FuelPumpPwr_D_Stat 1;
BA_ "U_P702_MY2021_Rx" SG_ 578 BattULo_U_Actl 1;
BA_ "GenSigStartValue" SG_ 578 BattULo_U_Actl 255;
BA_ "CrossOver_InfoCAN" SG_ 578 PrkLckCtl_B_Enbl 1;
BA_ "CrossOver_InfoCAN" SG_ 578 PrkLckCtlMsgTxt_D_Rq 1;
BA_ "WakeupSignal" SG_ 578 PrkLckCtlMsgTxt_D_Rq 1;
BA_ "CrossOver_InfoCAN" SG_ 578 PrkLckCtlAvail_T_Stat 1;
BA_ "WakeupSignal" SG_ 578 PrkLckCtlAvail_T_Stat 1;
BA_ "U_P702_MY2021_Rx" SG_ 578 BrkTrnShifLck_B_Stat 1;
BA_ "U_P702_MY2021_Rx" SG_ 578 DriverCrankingReq 1;
BA_ "U_P702_MY2021_Rx" SG_ 578 EngOff_T_Actl 1;
BA_ "U_P702_MY2021_Rx" SG_ 578 DcacElPw_D_Rq 1;
BA_ "U_P702_MY2021_Rx" SG_ 578 BattULo_I_Actl 1;
BA_ "GenSigStartValue" SG_ 578 BattULo_I_Actl 16383;
BA_ "WakeupSignal" SG_ 947 DimmingLvlEvnt_No_Actl 1;
BA_ "U_P702_MY2021_Rx" SG_ 947 DrStatDrvErrCnt_B_Stat 1;
BA_ "U_P702_MY2021_Rx" SG_ 947 TurnLghtRight_D_Rq 1;
BA_ "CrossOver_InfoCAN" SG_ 947 TurnLghtRight_D_Rq 1;
BA_ "WakeupSignal" SG_ 947 TurnLghtRight_D_Rq 1;
BA_ "CrossOver_InfoCAN" SG_ 947 TurnLghtRightOn_B_Stat 1;
BA_ "CrossOver_InfoCAN" SG_ 947 TurnLghtLeftOn_B_Stat 1;
BA_ "U_P702_MY2021_Rx" SG_ 947 FogLghtRearOn_B_Stat 1;
BA_ "CrossOver_InfoCAN" SG_ 947 FogLghtRearOn_B_Stat 1;
BA_ "CrossOver_InfoCAN" SG_ 947 Backlit_LED_Status 1;
BA_ "WakeupSignal" SG_ 947 Backlit_LED_Status 1;
BA_ "U_P702_MY2021_Rx" SG_ 947 TurnLghtLeft_D_Rq 1;
BA_ "CrossOver_InfoCAN" SG_ 947 TurnLghtLeft_D_Rq 1;
BA_ "WakeupSignal" SG_ 947 TurnLghtLeft_D_Rq 1;
BA_ "U_P702_MY2021_Rx" SG_ 947 FogLghtFrontOn_B_Stat 1;
BA_ "CrossOver_InfoCAN" SG_ 947 FogLghtFrontOn_B_Stat 1;
BA_ "U_P702_MY2021_Rx" SG_ 947 IgnKeyType_D_Actl 1;
BA_ "GenSigStartValue" SG_ 947 IgnKeyType_D_Actl 14;
BA_ "CrossOver_InfoCAN" SG_ 947 IgnKeyType_D_Actl 1;
BA_ "GenSigStartValue" SG_ 947 Parklamp_Status 1;
BA_ "CrossOver_InfoCAN" SG_ 947 Parklamp_Status 1;
BA_ "WakeupSignal" SG_ 947 Parklamp_Status 1;
BA_ "U_P702_MY2021_Rx" SG_ 947 Litval 1;
BA_ "CrossOver_InfoCAN" SG_ 947 Litval 1;
BA_ "WakeupSignal" SG_ 947 Litval 1;
BA_ "U_P702_MY2021_Rx" SG_ 947 Key_In_Ignition_Stat 1;
BA_ "CrossOver_InfoCAN" SG_ 947 Key_In_Ignition_Stat 1;
BA_ "WakeupSignal" SG_ 947 Key_In_Ignition_Stat 1;
BA_ "U_P702_MY2021_Rx" SG_ 947 Ignition_Status 1;
BA_ "CrossOver_InfoCAN" SG_ 947 Ignition_Status 1;
BA_ "WakeupSignal" SG_ 947 Ignition_Status 1;
BA_ "GenSigStartValue" SG_ 947 Dimming_Lvl 12;
BA_ "CrossOver_InfoCAN" SG_ 947 Dimming_Lvl 1;
BA_ "WakeupSignal" SG_ 947 Dimming_Lvl 1;
BA_ "U_P702_MY2021_Rx" SG_ 947 Day_Night_Status 1;
BA_ "CrossOver_InfoCAN" SG_ 947 Day_Night_Status 1;
BA_ "WakeupSignal" SG_ 947 Day_Night_Status 1;
BA_ "CrossOver_InfoCAN" SG_ 947 Remote_Start_Status 1;
BA_ "WakeupSignal" SG_ 947 Remote_Start_Status 1;
BA_ "CrossOver_InfoCAN" SG_ 947 DrStatTgate_B_Actl 1;
BA_ "WakeupSignal" SG_ 947 DrStatTgate_B_Actl 1;
BA_ "U_P702_MY2021_Rx" SG_ 947 DrStatRr_B_Actl 1;
BA_ "CrossOver_InfoCAN" SG_ 947 DrStatRr_B_Actl 1;
BA_ "WakeupSignal" SG_ 947 DrStatRr_B_Actl 1;
BA_ "U_P702_MY2021_Rx" SG_ 947 DrStatRl_B_Actl 1;
BA_ "CrossOver_InfoCAN" SG_ 947 DrStatRl_B_Actl 1;
BA_ "WakeupSignal" SG_ 947 DrStatRl_B_Actl 1;
BA_ "U_P702_MY2021_Rx" SG_ 947 DrStatPsngr_B_Actl 1;
BA_ "CrossOver_InfoCAN" SG_ 947 DrStatPsngr_B_Actl 1;
BA_ "WakeupSignal" SG_ 947 DrStatPsngr_B_Actl 1;
BA_ "CrossOver_InfoCAN" SG_ 947 DrStatInnrTgate_B_Actl 1;
BA_ "WakeupSignal" SG_ 947 DrStatInnrTgate_B_Actl 1;
BA_ "CrossOver_InfoCAN" SG_ 947 DrStatHood_B_Actl 1;
BA_ "WakeupSignal" SG_ 947 DrStatHood_B_Actl 1;
BA_ "U_P702_MY2021_Rx" SG_ 947 DrStatDrv_B_Actl 1;
BA_ "CrossOver_InfoCAN" SG_ 947 DrStatDrv_B_Actl 1;
BA_ "WakeupSignal" SG_ 947 DrStatDrv_B_Actl 1;
BA_ "U_P702_MY2021_Rx" SG_ 947 PrkBrkActv_B_Actl 1;
BA_ "ContentDependant" SG_ 947 PrkBrkActv_B_Actl 1;
BA_ "CrossOver_InfoCAN" SG_ 947 PrkBrkActv_B_Actl 1;
BA_ "WakeupSignal" SG_ 947 PrkBrkActv_B_Actl 1;
BA_ "U_P702_MY2021_Rx" SG_ 947 LifeCycMde_D_Actl 1;
BA_ "CrossOver_InfoCAN" SG_ 947 LifeCycMde_D_Actl 1;
BA_ "CrossOver_InfoCAN" SG_ 947 Delay_Accy 1;
BA_ "WakeupSignal" SG_ 947 Delay_Accy 1;
BA_ "GenSigStartValue" SG_ 947 CrashEvnt_D_Stat 3;
BA_ "CrossOver_InfoCAN" SG_ 947 CrashEvnt_D_Stat 1;
BA_ "WakeupSignal" SG_ 947 CrashEvnt_D_Stat 1;
BA_ "CrossOver_InfoCAN" SG_ 947 FuelPmpInhbt_B_Stat 1;
BA_ "CrossOver_InfoCAN" SG_ 947 BodySrvcRqd_B_Rq 1;
BA_ "U_P702_MY2021_Rx" SG_ 1084 BattULoChrg_URate_RqMx 1;
BA_ "GenSigStartValue" SG_ 1084 BattULoChrg_URate_RqMx 5;
BA_ "U_P702_MY2021_Rx" SG_ 1084 BattULoChrg_U_RqMx 1;
BA_ "GenSigStartValue" SG_ 1084 BattULoChrg_U_RqMx 34;
BA_ "U_P702_MY2021_Rx" SG_ 1084 BattULoChrg_U_RqMn 1;
BA_ "U_P702_MY2021_Rx" SG_ 1084 BattULoState_D_Qlty 1;
BA_ "U_P702_MY2021_Rx" SG_ 1084 BSFault 1;
BA_ "U_P702_MY2021_Rx" SG_ 1084 BattULo2_Te_Actl 1;
BA_ "GenSigStartValue" SG_ 1084 BattULo2_Te_Actl 127;
BA_ "U_P702_MY2021_Rx" SG_ 1084 BSBattSOC 1;
BA_ "U_P702_MY2021_Rx" SG_ 1084 BSBattQDeltaRideAh 1;
BA_ "GenSigStartValue" SG_ 1084 BSBattQDeltaRideAh 12800;
BA_ "U_P702_MY2021_Rx" SG_ 1084 BSBattQCapAh 1;
BA_ "U_P702_MY2021_Rx" SG_ 1068 EngStrtInhbt_B_RqBatt 1;
BA_ "U_P702_MY2021_Rx" SG_ 1068 BattULoChrg_D_Rq 1;
BA_ "CrossOver_InfoCAN" SG_ 1068 PwSysULoFalt_D_Stat 1;
BA_ "WakeupSignal" SG_ 1068 PwSysULoFalt_D_Stat 1;
BA_ "CrossOver_InfoCAN" SG_ 1068 Shed_T_Eng_Off_B 1;
BA_ "U_P702_MY2021_Rx" SG_ 1068 Shed_Feature_Group_ID 1;
BA_ "WakeupSignal" SG_ 1068 Shed_Feature_Group_ID 1;
BA_ "CrossOver_InfoCAN" SG_ 1068 Shed_Drain_Eng_Off_B 1;
BA_ "U_P702_MY2021_Rx" SG_ 1068 Shed_Level_Req 1;
BA_ "CrossOver_InfoCAN" SG_ 1068 Shed_Level_Req 1;
BA_ "WakeupSignal" SG_ 1068 Shed_Level_Req 1;
BA_ "U_P702_MY2021_Rx" SG_ 1068 ULoRgenTestMde_B_Rq 1;
BA_ "U_P702_MY2021_Rx" SG_ 1068 ChargeMode 1;
BA_ "CrossOver_InfoCAN" SG_ 1068 Batt_Lo_SoC_B 1;
BA_ "U_P702_MY2021_Rx" SG_ 1068 PeriodicElLoad_B_Stat 1;
BA_ "CrossOver_InfoCAN" SG_ 1068 Batt_Crit_SoC_B 1;
BA_ "U_P702_MY2021_Rx" SG_ 146 VehVert2_A_Actl 1;
BA_ "GenSigStartValue" SG_ 146 VehVert2_A_Actl 8190;
BA_ "U_P702_MY2021_Rx" SG_ 146 VehLatLongVertA_No_Cs 1;
BA_ "MetaData" SG_ 146 VehLatLongVertA_No_Cs 1;
BA_ "U_P702_MY2021_Rx" SG_ 146 VehLatLongVert_No_Cnt 1;
BA_ "MetaData" SG_ 146 VehLatLongVert_No_Cnt 1;
BA_ "U_P702_MY2021_Rx" SG_ 146 VehLong2_A_Actl 1;
BA_ "GenSigStartValue" SG_ 146 VehLong2_A_Actl 8190;
BA_ "U_P702_MY2021_Rx" SG_ 146 VehLat2_A_Actl 1;
BA_ "GenSigStartValue" SG_ 146 VehLat2_A_Actl 8190;
BA_ "U_P702_MY2021_Rx" SG_ 146 VehVertAActl_D_Qf 1;
BA_ "MetaData" SG_ 146 VehVertAActl_D_Qf 1;
BA_ "GenSigStartValue" SG_ 146 VehVertAActl_D_Qf 1;
BA_ "U_P702_MY2021_Rx" SG_ 146 VehLongAActl_D_Qf 1;
BA_ "MetaData" SG_ 146 VehLongAActl_D_Qf 1;
BA_ "GenSigStartValue" SG_ 146 VehLongAActl_D_Qf 1;
BA_ "U_P702_MY2021_Rx" SG_ 146 VehLatAActl_D_Qf 1;
BA_ "MetaData" SG_ 146 VehLatAActl_D_Qf 1;
BA_ "GenSigStartValue" SG_ 146 VehLatAActl_D_Qf 1;
BA_ "GenSigSendType" SG_ 1900 TesterPhysicalResCCM 3;
BA_ "GenSigSendType" SG_ 1806 TesterPhysicalResIPMA 3;
BA_ "GenSigStartValue" SG_ 997 PersIndexCcm_D_Actl 4;
BA_ "CrossOver_InfoCAN" SG_ 997 PersIndexCcm_D_Actl 1;
BA_ "GenSigSendType" SG_ 997 PersIndexCcm_D_Actl 3;
BA_ "CrossOver_InfoCAN" SG_ 997 FeatNoCcmActl 1;
BA_ "GenSigSendType" SG_ 997 FeatNoCcmActl 3;
BA_ "CrossOver_InfoCAN" SG_ 997 FeatConfigCcmActl 1;
BA_ "GenSigSendType" SG_ 997 FeatConfigCcmActl 3;
BA_ "U_P702_MY2021_Rx" SG_ 985 AdbDividedRoad_B_Stat 1;
BA_ "GenSigSendType" SG_ 985 AdbDividedRoad_B_Stat 3;
BA_ "U_P702_MY2021_Rx" SG_ 985 AdbRampingV_D_Rq 1;
BA_ "GenSigSendType" SG_ 985 AdbRampingV_D_Rq 3;
BA_ "U_P702_MY2021_Rx" SG_ 985 AdbLampOnOff_D_Rq 1;
BA_ "GenSigSendType" SG_ 985 AdbLampOnOff_D_Rq 3;
BA_ "U_P702_MY2021_Rx" SG_ 985 AdbHiBeamKeepOff_D_Rq 1;
BA_ "GenSigSendType" SG_ 985 AdbHiBeamKeepOff_D_Rq 3;
BA_ "U_P702_MY2021_Rx" SG_ 985 IsaVLimUnit_D_Rq 1;
BA_ "GenSigSendType" SG_ 985 IsaVLimUnit_D_Rq 3;
BA_ "U_P702_MY2021_Rx" SG_ 985 SblmYieldScnr_B_Stat 1;
BA_ "GenSigSendType" SG_ 985 SblmYieldScnr_B_Stat 3;
BA_ "U_P702_MY2021_Rx" SG_ 985 SblmStopScnr_B_Stat 1;
BA_ "GenSigSendType" SG_ 985 SblmStopScnr_B_Stat 3;
BA_ "U_P702_MY2021_Rx" SG_ 985 IsaVLim_D_Rq 1;
BA_ "GenSigStartValue" SG_ 985 IsaVLim_D_Rq 254;
BA_ "GenSigSendType" SG_ 985 IsaVLim_D_Rq 3;
BA_ "U_P702_MY2021_Rx" SG_ 985 IaccVLimUnit_D_Rq 1;
BA_ "GenSigStartValue" SG_ 985 IaccVLimUnit_D_Rq 3;
BA_ "GenSigSendType" SG_ 985 IaccVLimUnit_D_Rq 3;
BA_ "U_P702_MY2021_Rx" SG_ 985 IaccVLim_D_Rq 1;
BA_ "GenSigStartValue" SG_ 985 IaccVLim_D_Rq 254;
BA_ "GenSigSendType" SG_ 985 IaccVLim_D_Rq 3;
BA_ "GenSigSendType" SG_ 985 DasAlrtInfo_D_Dsply 3;
BA_ "U_P702_MY2021_Rx" SG_ 985 SblmRndAbtScnr_B_Stat 1;
BA_ "GenSigSendType" SG_ 985 SblmRndAbtScnr_B_Stat 3;
BA_ "GenSigSendType" SG_ 984 AhbHiBeam_D_Rq 3;
BA_ "MetaData" SG_ 984 CadsCamraStat_D_Qf 1;
BA_ "GenSigStartValue" SG_ 984 CadsCamraStat_D_Qf 1;
BA_ "GenSigSendType" SG_ 984 CadsCamraStat_D_Qf 3;
BA_ "GenSigSendType" SG_ 984 AhbcStat_B_Dsply 3;
BA_ "CrossOver_InfoCAN" SG_ 984 LaSwtch_D_RqDrv 1;
BA_ "GenSigSendType" SG_ 984 LaSwtch_D_RqDrv 3;
BA_ "CrossOver_InfoCAN" SG_ 984 AhbcHiBeam_D_Rq 1;
BA_ "GenSigSendType" SG_ 984 AhbcHiBeam_D_Rq 3;
BA_ "CrossOver_InfoCAN" SG_ 984 LaSwtchStat_No_Actl 1;
BA_ "CrossOver_InfoCAN" SG_ 984 DasWarn_D_Dsply 1;
BA_ "GenSigSendType" SG_ 984 DasWarn_D_Dsply 3;
BA_ "CrossOver_InfoCAN" SG_ 984 DasStats_D_Dsply 1;
BA_ "GenSigSendType" SG_ 984 DasStats_D_Dsply 3;
BA_ "CrossOver_InfoCAN" SG_ 984 DasAlrtLvl_D_Dsply 1;
BA_ "GenSigSendType" SG_ 984 DasAlrtLvl_D_Dsply 3;
BA_ "CrossOver_InfoCAN" SG_ 984 CamraStats_D_Dsply 1;
BA_ "GenSigSendType" SG_ 984 CamraStats_D_Dsply 3;
BA_ "CrossOver_InfoCAN" SG_ 984 CamraDefog_B_Req 1;
BA_ "GenSigSendType" SG_ 984 CamraDefog_B_Req 3;
BA_ "CrossOver_InfoCAN" SG_ 984 LaHandsOff_D_Dsply 1;
BA_ "GenSigSendType" SG_ 984 LaHandsOff_D_Dsply 3;
BA_ "CrossOver_InfoCAN" SG_ 984 LaDenyStats_B_Dsply 1;
BA_ "GenSigSendType" SG_ 984 LaDenyStats_B_Dsply 3;
BA_ "CrossOver_InfoCAN" SG_ 984 LaActvStats_D_Dsply 1;
BA_ "GenSigSendType" SG_ 984 LaActvStats_D_Dsply 3;
BA_ "U_P702_MY2021_Rx" SG_ 984 AhbcRampingV_D_Rq 1;
BA_ "GenSigSendType" SG_ 984 AhbcRampingV_D_Rq 3;
BA_ "GenSigStartValue" SG_ 984 PersIndexIpma_D_Actl 4;
BA_ "CrossOver_InfoCAN" SG_ 984 PersIndexIpma_D_Actl 1;
BA_ "GenSigSendType" SG_ 984 PersIndexIpma_D_Actl 3;
BA_ "CrossOver_InfoCAN" SG_ 984 FeatNoIpmaActl 1;
BA_ "CrossOver_InfoCAN" SG_ 984 FeatConfigIpmaActl 1;
BA_ "U_P702_MY2021_Rx" SG_ 983 CmbbObjRelLong_V_Actl 1;
BA_ "GenSigStartValue" SG_ 983 CmbbObjRelLong_V_Actl 1022;
BA_ "U_P702_MY2021_Rx" SG_ 983 CmbbObjRelLat_V_Actl 1;
BA_ "GenSigStartValue" SG_ 983 CmbbObjRelLat_V_Actl 510;
BA_ "U_P702_MY2021_Rx" SG_ 983 CmbbObjDistLong_L_Actl 1;
BA_ "GenSigStartValue" SG_ 983 CmbbObjDistLong_L_Actl 1022;
BA_ "U_P702_MY2021_Rx" SG_ 983 CmbbObjDistLat_L_Actl 1;
BA_ "GenSigStartValue" SG_ 983 CmbbObjDistLat_L_Actl 510;
BA_ "U_P702_MY2021_Rx" SG_ 983 CmbbObjConfdnc_D_Stat 1;
BA_ "U_P702_MY2021_Rx" SG_ 983 CmbbObjColl_T_Actl 1;
BA_ "GenSigStartValue" SG_ 983 CmbbObjColl_T_Actl 126;
BA_ "U_P702_MY2021_Rx" SG_ 983 CmbbObjClass_D_Stat 1;
BA_ "U_P702_MY2021_Rx" SG_ 983 EsaEnbl_D2_Rq 1;
BA_ "U_P702_MY2021_Rx" SG_ 980 AdbBrdr1DistRigh_D_Stat 1;
BA_ "U_P702_MY2021_Rx" SG_ 980 AdbBrdr1DistLeft_D_Stat 1;
BA_ "U_P702_MY2021_Rx" SG_ 980 AdbMde1_D_Rq 1;
BA_ "U_P702_MY2021_Rx" SG_ 980 AdbIntns1_D_Rq 1;
BA_ "U_P702_MY2021_Rx" SG_ 980 AdbBrdr1Up_An_Rq 1;
BA_ "GenSigStartValue" SG_ 980 AdbBrdr1Up_An_Rq 510;
BA_ "U_P702_MY2021_Rx" SG_ 980 AdbBrdr1Right_An_Rq 1;
BA_ "GenSigStartValue" SG_ 980 AdbBrdr1Right_An_Rq 2046;
BA_ "U_P702_MY2021_Rx" SG_ 980 AdbBrdr1Low_An_Rq 1;
BA_ "GenSigStartValue" SG_ 980 AdbBrdr1Low_An_Rq 510;
BA_ "U_P702_MY2021_Rx" SG_ 980 AdbBrdr1Left_An_Rq 1;
BA_ "GenSigStartValue" SG_ 980 AdbBrdr1Left_An_Rq 2046;
BA_ "U_P702_MY2021_Rx" SG_ 980 AdbBrdr1CritRigh_T_Stat 1;
BA_ "U_P702_MY2021_Rx" SG_ 980 AdbBrdr1CritLeft_T_Stat 1;
BA_ "U_P702_MY2021_Rx" SG_ 979 HandsOffCnfm_B_Rq 1;
BA_ "U_P702_MY2021_Rx" SG_ 979 LatCtl_D_Rq 1;
BA_ "U_P702_MY2021_Rx" SG_ 979 LatCtlRampType_D_Rq 1;
BA_ "U_P702_MY2021_Rx" SG_ 979 LatCtlPrecision_D_Rq 1;
BA_ "U_P702_MY2021_Rx" SG_ 979 LatCtlPathOffst_L_Actl 1;
BA_ "GenSigStartValue" SG_ 979 LatCtlPathOffst_L_Actl 512;
BA_ "U_P702_MY2021_Rx" SG_ 979 LatCtlPath_An_Actl 1;
BA_ "GenSigStartValue" SG_ 979 LatCtlPath_An_Actl 1000;
BA_ "U_P702_MY2021_Rx" SG_ 979 LatCtlCurv_NoRate_Actl 1;
BA_ "GenSigStartValue" SG_ 979 LatCtlCurv_NoRate_Actl 4096;
BA_ "U_P702_MY2021_Rx" SG_ 979 LatCtlCurv_No_Actl 1;
BA_ "GenSigStartValue" SG_ 979 LatCtlCurv_No_Actl 1000;
BA_ "GenSigStartValue" SG_ 976 SrpHghtRight_L_Actl 256;
BA_ "GenSigStartValue" SG_ 976 SrpHghtLeft_L_Actl 256;
BA_ "GenSigSendType" SG_ 973 TsrVl2PrmntMsgTxt_D_Rq 3;
BA_ "GenSigSendType" SG_ 973 TsrVl1PrmntMsgTxt_D_Rq 3;
BA_ "GenSigStartValue" SG_ 973 TsrVl2RstrcMsgTxt2_D_Rq 1;
BA_ "GenSigSendType" SG_ 973 TsrVl2RstrcMsgTxt2_D_Rq 3;
BA_ "GenSigStartValue" SG_ 973 TsrVl1RstrcMsgTxt2_D_Rq 1;
BA_ "GenSigSendType" SG_ 973 TsrVl1RstrcMsgTxt2_D_Rq 3;
BA_ "GenSigSendType" SG_ 973 TsrOvtkMsgTxt2_D_Rq 3;
BA_ "GenSigSendType" SG_ 973 WwaWarn_B_Rq 3;
BA_ "GenSigStartValue" SG_ 973 TsrVlUnitMsgTxt_D_Rq 2;
BA_ "CrossOver_InfoCAN" SG_ 973 TsrVlUnitMsgTxt_D_Rq 1;
BA_ "GenSigSendType" SG_ 973 TsrVlUnitMsgTxt_D_Rq 3;
BA_ "GenSigStartValue" SG_ 973 TsrVLim2MsgTxt_D_Rq 255;
BA_ "CrossOver_InfoCAN" SG_ 973 TsrVLim2MsgTxt_D_Rq 1;
BA_ "GenSigSendType" SG_ 973 TsrVLim2MsgTxt_D_Rq 3;
BA_ "GenSigStartValue" SG_ 973 TsrVLim1MsgTxt_D_Rq 255;
BA_ "CrossOver_InfoCAN" SG_ 973 TsrVLim1MsgTxt_D_Rq 1;
BA_ "GenSigSendType" SG_ 973 TsrVLim1MsgTxt_D_Rq 3;
BA_ "CrossOver_InfoCAN" SG_ 973 TsrVl2TypeMsgTxt_D_Rq 1;
BA_ "GenSigSendType" SG_ 973 TsrVl2TypeMsgTxt_D_Rq 3;
BA_ "CrossOver_InfoCAN" SG_ 973 TsrVl2StatMsgTxt_D_Rq 1;
BA_ "GenSigSendType" SG_ 973 TsrVl2StatMsgTxt_D_Rq 3;
BA_ "CrossOver_InfoCAN" SG_ 973 TsrVl2RstrcMsgTxt_D_Rq 1;
BA_ "GenSigSendType" SG_ 973 TsrVl2RstrcMsgTxt_D_Rq 3;
BA_ "CrossOver_InfoCAN" SG_ 973 TsrVl1TypeMsgTxt_D_Rq 1;
BA_ "GenSigSendType" SG_ 973 TsrVl1TypeMsgTxt_D_Rq 3;
BA_ "CrossOver_InfoCAN" SG_ 973 TsrVl1StatMsgTxt_D_Rq 1;
BA_ "GenSigSendType" SG_ 973 TsrVl1StatMsgTxt_D_Rq 3;
BA_ "CrossOver_InfoCAN" SG_ 973 TsrVl1RstrcMsgTxt_D_Rq 1;
BA_ "GenSigSendType" SG_ 973 TsrVl1RstrcMsgTxt_D_Rq 3;
BA_ "CrossOver_InfoCAN" SG_ 973 TsrStatMsgTxt_D_Rq 1;
BA_ "GenSigSendType" SG_ 973 TsrStatMsgTxt_D_Rq 3;
BA_ "CrossOver_InfoCAN" SG_ 973 TsrOvtkTypeMsgTxt_D_Rq 1;
BA_ "GenSigSendType" SG_ 973 TsrOvtkTypeMsgTxt_D_Rq 3;
BA_ "CrossOver_InfoCAN" SG_ 973 TsrOvtkStatMsgTxt_D_Rq 1;
BA_ "GenSigSendType" SG_ 973 TsrOvtkStatMsgTxt_D_Rq 3;
BA_ "GenSigStartValue" SG_ 973 TsrOvtkMsgTxt_D_Rq 1;
BA_ "CrossOver_InfoCAN" SG_ 973 TsrOvtkMsgTxt_D_Rq 1;
BA_ "GenSigSendType" SG_ 973 TsrOvtkMsgTxt_D_Rq 3;
BA_ "GenSigStartValue" SG_ 973 TsrOswWarnMsgTxt_D_Rq 1;
BA_ "CrossOver_InfoCAN" SG_ 973 TsrOswWarnMsgTxt_D_Rq 1;
BA_ "GenSigSendType" SG_ 973 TsrOswWarnMsgTxt_D_Rq 3;
BA_ "GenSigStartValue" SG_ 973 TsrMsgTxt_D_Rq 1;
BA_ "CrossOver_InfoCAN" SG_ 973 TsrMsgTxt_D_Rq 1;
BA_ "GenSigSendType" SG_ 973 TsrMsgTxt_D_Rq 3;
VAL_ 936 ApaSys_D_Stat 7 "Faulty" 6 "Finished" 5 "NotAccessible" 4 "ApaCancelled" 3 "Overspeed" 2 "On" 1 "Off" 0 "Null" ;
VAL_ 936 ApaSteWhl_D_RqDrv 3 "TakeControl" 2 "RemoveHands" 1 "NoRequest" 0 "Null" ;
VAL_ 936 ApaSteScanMde_D_Stat 3 "Steering" 2 "Scanning" 1 "NotScanning" 0 "Null" ;
VAL_ 936 ApaSelSapp_D_Stat 3 "NotConfigured" 2 "NotSelectable" 1 "Selectable" 0 "Null" ;
VAL_ 936 ApaSelPpa_D_Stat 3 "NotConfigured" 2 "NotSelectable" 1 "Selectable" 0 "Null" ;
VAL_ 936 ApaSelPoa_D_Stat 3 "NotConfigured" 2 "NotSelectable" 1 "Selectable" 0 "Null" ;
VAL_ 936 ApaScan_D_Stat 3 "ParkSlotReady" 2 "ParkSlotFound" 1 "NoParkSlot" 0 "Null" ;
VAL_ 936 ApaLongCtl_D_RqDrv 7 "NotUsed3" 6 "NotUsed2" 5 "ReleaseBrake" 4 "DriveBackward" 3 "DriveForward" 2 "Stop" 1 "NoRequest" 0 "Null" ;
VAL_ 936 ApaGearShif_D_RqDrv 7 "NotUSed2" 6 "NotUsed1" 5 "ShiftToP" 4 "ShiftToN" 3 "ShiftToD" 2 "ShiftToR" 1 "NoRequest" 0 "Null" ;
VAL_ 936 ApaActvSide2_D_Stat 3 "NoSide" 2 "Right" 1 "Left" 0 "Null" ;
VAL_ 936 ApaAcsy_D_RqDrv 7 "CloseDoor" 6 "SelectSideRight" 5 "SelectSideLeft" 4 "CheckForObject" 3 "PressApaButton" 2 "SelectSide" 1 "NoRequest" 0 "Null" ;
VAL_ 936 ApaTrgtDist_D_Stat 15 "Step15" 14 "Step14" 13 "Step13" 12 "Step12" 11 "Step11" 10 "Step10" 9 "Step9" 8 "Step8" 7 "Step7" 6 "Step6" 5 "Step5" 4 "Step4" 3 "Step3" 2 "Step2" 1 "Step1" 0 "Off" ;
VAL_ 936 ApaChime_D_Rq 7 "NotUsed2" 6 "NotUsed1" 5 "Warning_Chime" 4 "Finish_Chime" 3 "Stop_Now_Chime" 2 "Spot_Ready_Chime" 1 "Spot_Found_Chime" 0 "No_Chime" ;
VAL_ 936 EPASExtAngleStatReq 1 "Request" 0 "NoRequest" ;
VAL_ 936 ExtSteeringAngleReq2 32767 "Invalid" 32766 "Unknown" ;
VAL_ 877 VehElEffAvg_No_Dsply 127 "Faulty" 126 "NoDataExists" ;
VAL_ 877 PwFlwFuelDrv_D_Dsply 7 "NotUsed_4" 6 "NotUsed_3" 5 "NotUsed_2" 4 "NotUsed_1" 3 "FlwFromFuelToAllWhls" 2 "FlwFromFuelToFrontWhls" 1 "FlwFromFuelToRearWhls" 0 "NoFlow" ;
VAL_ 877 PwFlwFuelClimt_B_Dsply 1 "On" 0 "Off" ;
VAL_ 877 PwFlwFuelBatt_B_Dsply 1 "On" 0 "Off" ;
VAL_ 877 PwFlwBattGen_D_Dsply 1 "On" 0 "Off" ;
VAL_ 877 PwFlwBattClimt_B_Dsply 1 "On" 0 "Off" ;
VAL_ 877 PwFlwBatt_D_Dsply 15 "NotUsed_8" 14 "NotUsed_7" 13 "NotUsed_6" 12 "NotUsed_5" 11 "NotUsed_4" 10 "NotUsed_3" 9 "NotUsed_2" 8 "NotUsed_1" 7 "FlwFromWallToBatt" 6 "FlwFromAllWhlsToBatt" 5 "FlwFromBattToAllWhls" 4 "FlwFromFrontWhlsToBatt" 3 "FlwFromBattToFrontWhls" 2 "FlwFromRearWhlsToBatt" 1 "FlwFromBattToRearWhls" 0 "NoFlow" ;
VAL_ 786 VehElRngeCyc_L_Dsply 4095 "Faulty" 4094 "NoDataExists" ;
VAL_ 786 PtDataKeyId_D_Stat 15 "NotUsed5" 14 "NotUsed4" 13 "NotUsed3" 12 "NotUsed2" 11 "NotUsed1" 10 "Tot_Veh_NUT" 9 "Cust_4_NUT" 8 "Cust_3_NUT" 7 "Cust_2_NUT" 6 "Cust_1_NUT" 5 "Tot_Veh_Stat" 4 "Cust_4_Stat" 3 "Cust_3_Stat" 2 "Cust_2_Stat" 1 "Cust_1_Stat" 0 "Null" ;
VAL_ 786 ChrgStat_D_Dsply 7 "NotUsed" 6 "Complete" 5 "Scheduled" 4 "In_Progress" 3 "Fault_Outside_Car" 2 "Fault_Inside_Car" 1 "Fault_Unknown_Location" 0 "Not_Ready" ;
VAL_ 389 HtrnOvrTeLamp_B_Dsply 1 "On" 0 "Off" ;
VAL_ 389 HtrnMil_D_Rq 3 "Not_Used" 2 "Flash" 1 "On" 0 "Off" ;
VAL_ 389 HtrnAin_UHi_Actl 1023 "Fault" 1022 "Unknown" ;
VAL_ 389 HtrnSrvcRqd_B_Dsply 1 "On" 0 "Off" ;
VAL_ 389 HtrnHvilOpen_B_Actl 1 "HVIL_is_Open" 0 "Normal_Operation" ;
VAL_ 389 PtWakeupDeltaT_T_Rq 2047 "Fault" 2046 "NoDataExists" ;
VAL_ 389 PreCondActv_B_Actl 1 "On" 0 "Off" ;
VAL_ 389 DrvCondTpRrDefrs_B_Rq 1 "On" 0 "Off" ;
VAL_ 389 BattTrac_I_EstVsc 32767 "Fault" 32766 "NoDataExists" ;
VAL_ 1009 ChrgCordUnlock_B_Rq 1 "Request" 0 "NoRequest" ;
VAL_ 1009 AutoHoldSwtch_D_Stat3 3 "Faulty" 2 "NotUsed" 1 "Pressed" 0 "Not_Pressed" ;
VAL_ 1009 TrlrTrgtAcquire_D_Rq 7 "NotUsed_2" 6 "NotUsed_1" 5 "ActivateRVCforTBA" 4 "CancelAcquisition" 3 "RetryAcquisition" 2 "AcquisitionSuccessful" 1 "StartAcquisition" 0 "Inactive" ;
VAL_ 1009 TrlrAidCancl_B_Rq 1 "Cancel" 0 "Null" ;
VAL_ 1009 CenterStackRing_D_Actl 3 "LimitedOn" 2 "On" 1 "Off" 0 "Null" ;
VAL_ 1009 ValetMode_D_Stat 3 "NotUsed" 2 "On" 1 "Off" 0 "Null" ;
VAL_ 1009 TrlrAidSetup_D_Stat 7 "Faulty" 6 "NotUsed_3" 5 "NotUsed_2" 4 "NotUsed_1" 3 "EnterParameters" 2 "EndSetup" 1 "BeginSetup" 0 "Null" ;
VAL_ 360 GsmSrvcRqd_B_Rq 1 "Yes" 0 "No" ;
VAL_ 360 TrnTrcmPwmSig_D_Actl 15 "Faulty" 14 "NoDataExists" 13 "NotUsed5" 12 "NotUsed4" 11 "NotUsed3" 10 "NotUsed2" 9 "NotUsed1" 8 "Default_To_Park" 7 "Neutral_Tow" 6 "Car_Wash_Mode" 5 "Manual" 4 "Drive" 3 "Neutral" 2 "Reverse" 1 "Park" 0 "No_Gear" ;
VAL_ 360 TrnGearPwmFalt_B_Actl 1 "Yes" 0 "No" ;
VAL_ 360 GearButtnStuck_B_Actl 1 "Yes" 0 "No" ;
VAL_ 122 BattTrac_U_Actl 1023 "Fault" 1022 "Unknown" ;
VAL_ 122 BattTrac_I_Actl 32767 "Fault" 32766 "Unknown" ;
VAL_ 122 BattTracOff_B_Actl 1 "Yes" 0 "No" ;
VAL_ 122 BattTracOffFst_D_Actl 3 "Unexpected_Contactor_Open" 2 "Restraints_Impact_Event" 1 "Interlock_Open" 0 "Normal" ;
VAL_ 122 BattTracMil_D_Rq 3 "Not_Used" 2 "Flash" 1 "On" 0 "Off" ;
VAL_ 122 BattTracCnnct_B_Cmd 1 "Close" 0 "Open" ;
VAL_ 122 VehStrtInhbt_B_RqBatt 1 "Yes" 0 "No" ;
VAL_ 90 TrnGsmNtmState_D_Actl 3 "Faulty" 2 "Neutral_Tow_Mode" 1 "Car_Wash_Mode" 0 "None" ;
VAL_ 90 DrQltyDrv_D_StatGsm 7 "Faulty" 6 "NoDataExists" 5 "NotUsed2" 4 "NotUsed1" 3 "ClosedDegraded" 2 "OpenDegraded" 1 "ClosedOkay" 0 "OpenOkay" ;
VAL_ 90 TrnBtsiOvrrd_B_Stat 1 "Override" 0 "Null" ;
VAL_ 90 GsmGearMsgTxt_D_Rq 3 "Message3" 2 "Message2" 1 "Message1" 0 "NoMessage" ;
VAL_ 90 TrnRng_D_RqGsm 15 "Fault" 14 "UnknownPosition" 13 "Undefined_2" 12 "Undefined_1" 11 "_6" 10 "_5" 9 "_4" 8 "_3" 7 "_2" 6 "_1" 5 "Low" 4 "Sport_DriveSport" 3 "Drive" 2 "Neutral" 1 "Reverse" 0 "Park" ;
VAL_ 90 PrkBrkActv_D_RqGsmGear 3 "NotUsed" 2 "RequestParkBrakeEngage" 1 "NoRequest" 0 "Null" ;
VAL_ 90 TrnValidGearRq_D_Stat 3 "Valid_Request" 2 "Valid_Degraded_Request" 1 "Invalid_Request" 0 "No_Request" ;
VAL_ 90 TrnGearButtn_U_Actl 255 "Fault" ;
VAL_ 90 TrnGearButtn_B_ActlR2 1 "Yes" 0 "No" ;
VAL_ 90 TrnGearButtn_B_ActlR1 1 "Yes" 0 "No" ;
VAL_ 90 TrnGearButtn_B_ActlR0 1 "Yes" 0 "No" ;
VAL_ 90 TrnGearButtn_B_ActlP2 1 "Yes" 0 "No" ;
VAL_ 90 TrnGearButtn_B_ActlP1 1 "Yes" 0 "No" ;
VAL_ 90 TrnGearButtn_B_ActlP0 1 "Yes" 0 "No" ;
VAL_ 90 TrnGearButtn_B_ActlN2 1 "Yes" 0 "No" ;
VAL_ 90 TrnGearButtn_B_ActlN1 1 "Yes" 0 "No" ;
VAL_ 90 TrnGearButtn_B_ActlN0 1 "Yes" 0 "No" ;
VAL_ 90 TrnGearButtn_B_ActlM2 1 "Yes" 0 "No" ;
VAL_ 90 TrnGearButtn_B_ActlM1 1 "Yes" 0 "No" ;
VAL_ 90 TrnGearButtn_B_ActlM0 1 "Yes" 0 "No" ;
VAL_ 90 TrnGearButtn_B_ActlD2 1 "Yes" 0 "No" ;
VAL_ 90 TrnGearButtn_B_ActlD1 1 "Yes" 0 "No" ;
VAL_ 90 TrnGearButtn_B_ActlD0 1 "Yes" 0 "No" ;
VAL_ 90 TrnGear_D_RqDrv 31 "Fault" 30 "NotUsed_25" 29 "NotUsed_24" 28 "NotUsed_23" 27 "NotUsed_22" 26 "Return_to_Park" 25 "NotUsed_20" 24 "NotUsed_19" 23 "NotUsed_18" 22 "NotUsed_17" 21 "Return_To_Park" 20 "NotUsed_15" 19 "NotUsed_14" 18 "NotUsed_13" 17 "NotUsed_12" 16 "Manual" 15 "Not_Used11" 14 "Not_Used10" 13 "NotUsed_9" 12 "NotUsed_8" 11 "NotUsed_7" 10 "NotUsed_6" 9 "NotUsed_5" 8 "Drive" 7 "NotUsed_4" 6 "NotUsed_3" 5 "NotUsed_2" 4 "Neutral" 3 "NotUsed_1" 2 "Reverse" 1 "Park" 0 "No_Gear" ;
VAL_ 90 BrkSwtchPos_B_ActlGsm 1 "Yes" 0 "No" ;
VAL_ 1114 TrailCtlSwtch_B_Stat2 1 "Pressed" 0 "Not_Pressed" ;
VAL_ 1114 TrlrRvrseCancl_B_Rq 1 "Cancel" 0 "Null" ;
VAL_ 1114 TrlBrkInitOut_D_Rq 3 "Heavy" 2 "Medium" 1 "Light" 0 "Null" ;
VAL_ 1114 TrlrAidSetup_D_Rq 3 "ConfirmSetup" 2 "EndSetup" 1 "BeginSetup" 0 "Inactive" ;
VAL_ 1114 TrlrAnOffstDir_D_Mem 3 "NotUSed" 2 "Right" 1 "Left_or_Center" 0 "Null" ;
VAL_ 1114 TrlrAidEnbl_D_Rq 3 "NotAvailable" 2 "DeactivateTba" 1 "ActivateTba" 0 "Inactive" ;
VAL_ 1114 TrlrIdType_D_Stat 3 "Gooseneck" 2 "FifthWheel" 1 "Conventional" 0 "Null" ;
VAL_ 1111 TrlrYawWActl_D_Qf 3 "OK" 2 "Not_Within_Specifications" 1 "No_Data_Exists" 0 "Faulty" ;
VAL_ 1111 TrlrYaw_W_Actl 65535 "Faulty" 65534 "NoDataExists" ;
VAL_ 1111 TrlrHitYaw_AnRate_Actl 4095 "Fault" 4094 "NoDataExists" ;
VAL_ 1111 TrlrHitchYaw_D_Stat 15 "Faulty" 14 "NotUsed_4" 13 "NotUsed_3" 12 "NotUsed_2" 11 "NotUsed_1" 10 "FaultyYrsuConnection" 9 "FaultyYrsu" 8 "HiConfdLrndAngle" 7 "LowConfdLrndAngle" 6 "HiConfdAngleMem" 5 "LowConfdAngleMem" 4 "InitNoTadAngle" 3 "InitInputs" 2 "TadTrlrDataOutOfRange" 1 "TadNotWithinSpecification" 0 "NoConnectionWithYrsu" ;
VAL_ 1111 TrlrHitchYaw_An_Actl 4095 "Faulty" 4094 "NoDataExists" ;
VAL_ 1106 TrlrSnsId_No_Actl -1 "Faulty_FFFFFFFFFFFF" -2 "NoDataExists_FFFFFFFFFFFE" ;
VAL_ 1091 CamraRearOn_D2_Stat2 7 "Faulty" 6 "NotUsed_3" 5 "NotUsed_2" 4 "NotUsed_1" 3 "Decommission" 2 "Activate" 1 "Deactivate" 0 "Null" ;
VAL_ 1091 PoliceAux4Lamp_B_Rq2 1 "On" 0 "Off" ;
VAL_ 1091 PoliceAux3Lamp_B_Rq2 1 "On" 0 "Off" ;
VAL_ 1091 PoliceAux2Lamp_B_Rq2 1 "On" 0 "Off" ;
VAL_ 1091 PoliceAux1Lamp_B_Rq2 1 "On" 0 "Off" ;
VAL_ 1091 TowBarMsgTxt_D_Rq 7 "NotUsed3" 6 "NotUsed2" 5 "NotUsed1" 4 "TowBar_Ext_No_Trlr" 3 "Error_Dealer_Fix" 2 "Start_Engine_Swivel" 1 "Check_Tow_Bar" 0 "Null" ;
VAL_ 1091 ParkLampTrlrOut_B_Stat 1 "Out" 0 "Null" ;
VAL_ 1091 TrlrLampCtl_D_Stat 3 "NotUsed" 2 "TrlrLampCnnctDrvFailure" 1 "TrlrLampNotCnnctDrvFailure" 0 "Null" ;
VAL_ 1091 TrlrBattChrg_D_Stat 3 "Reverse" 2 "Normal" 1 "Low" 0 "Null" ;
VAL_ 1091 StopLampTrlrOut_B_Stat 1 "Out" 0 "Null" ;
VAL_ 1091 TurnLampTrlrRr_B_Stat 1 "Out" 0 "Null" ;
VAL_ 1091 TurnLampTrlrRl_B_Stat 1 "Out" 0 "Null" ;
VAL_ 1091 TrlrLampCnnct_B_Actl 1 "Yes" 0 "No" ;
VAL_ 138 SteWhlRelCalib_An_Sns 32767 "Fault" 32766 "NoDataExists" ;
VAL_ 131 TjaButtnOnOffPress 1 "Pressed" 0 "Not_Pressed" ;
VAL_ 131 AccButtnGapDecPress 1 "Button_Pressed" 0 "Button_Not_Pressed" ;
VAL_ 131 HeadLghtHiCtrl_D_RqAhb 7 "NotUsed2" 6 "NotUsed1" 5 "Auto_HiBeam" 4 "Auto_LoBeam" 3 "Flash" 2 "Man_HiBeam" 1 "Man_LoBeam" 0 "Null" ;
VAL_ 131 AhbStat_B_Dsply 1 "On" 0 "Off" ;
VAL_ 131 WiprFrontSwtch_D_Stat 15 "NotUsed6" 14 "NotUsed5" 13 "NotUsed4" 12 "NotUsed3" 11 "NotUsed2" 10 "NotUsed1" 9 "PositionNotDetermined" 8 "High" 7 "Low" 6 "Position6" 5 "Position5" 4 "Position4" 3 "Position3" 2 "Position2" 1 "Position1" 0 "Off" ;
VAL_ 131 HeadLghtHiOn_B_StatAhb 1 "On" 0 "Off" ;
VAL_ 131 HeadLghtHiFlash_D_Actl 3 "NotUsed" 2 "High" 1 "Flash_to_Pass" 0 "Null" ;
VAL_ 131 AccButtnGapTogglePress 1 "Pressed" 0 "Not_Pressed" ;
VAL_ 131 HeadLghtHiFlash_D_Stat 3 "NotUsed" 2 "High" 1 "Flash_to_Pass" 0 "Null" ;
VAL_ 131 WiprFront_D_Stat 15 "NO_DATA_EXISTS" 14 "STALLED" 13 "RESERVED" 12 "AUTO_ADJUST" 11 "COURTESYWIPE" 10 "AUTO_HIGH" 9 "AUTO_LOW" 8 "WASH" 7 "MIST_FLICK" 6 "MAN_HIGH" 5 "MAN_LOW" 4 "MAN_INT_ON" 3 "MAN_INT_OFF" 2 "OFF_MOVING" 1 "AUTO_OFF" 0 "OFF" ;
VAL_ 131 TurnLghtSwtch_D_Stat 3 "Unused_Treat_As_Off" 2 "Right" 1 "Left" 0 "Off" ;
VAL_ 131 LghtAmb_D_Sns 7 "No_Data_Exists" 6 "Unused2" 5 "Unused1" 4 "Tunnel_Off" 3 "Tunnel_On" 2 "Twilight" 1 "Light" 0 "Dark" ;
VAL_ 131 AccButtnGapIncPress 1 "Button_Pressed" 0 "Button_Not_Pressed" ;
VAL_ 131 AslButtnOnOffPress 1 "Button_Pressed" 0 "Button_Not_Pressed" ;
VAL_ 131 AslButtnOnOffCnclPress 1 "Button_Pressed" 0 "Button_Not_Pressed" ;
VAL_ 131 CcButtnOnPress 1 "Button_Pressed" 0 "Button_Not_Pressed" ;
VAL_ 131 CcButtnOnOffPress 1 "Button_Pressed" 0 "Button_Not_Pressed" ;
VAL_ 131 CcButtnOnOffCnclPress 1 "Button_Pressed" 0 "Button_Not_Pressed" ;
VAL_ 131 CcButtnOffPress 1 "Button_Pressed" 0 "Button_Not_Pressed" ;
VAL_ 131 CcAsllButtnResPress 1 "Button_Pressed" 0 "Button_Not_Pressed" ;
VAL_ 131 CcAslButtnSetPress 1 "Button_Pressed" 0 "Button_Not_Pressed" ;
VAL_ 131 CcAslButtnSetIncPress 1 "Button_Pressed" 0 "Button_Not_Pressed" ;
VAL_ 131 CcAslButtnSetDecPress 1 "Button_Pressed" 0 "Button_Not_Pressed" ;
VAL_ 131 CcAslButtnResIncPress 1 "Button_Pressed" 0 "Button_Not_Pressed" ;
VAL_ 131 CcAslButtnResDecPress 1 "Button_Pressed" 0 "Button_Not_Pressed" ;
VAL_ 131 CcAslButtnOnPress 1 "Button_Pressed" 0 "Button_Not_Pressed" ;
VAL_ 131 CcAslButtnOnOffCncl 1 "Button_Pressed" 0 "Button_Not_Pressed" ;
VAL_ 131 CcAslButtnOffCnclPress 1 "Button_Pressed" 0 "Button_Not_Pressed" ;
VAL_ 131 CcAslButtnIndxIncPress 1 "Button_Pressed" 0 "Button_Not_Pressed" ;
VAL_ 131 CcAslButtnIndxDecPress 1 "Button_Pressed" 0 "Button_Not_Pressed" ;
VAL_ 131 CcAslButtnDeny_B_Actl 1 "Yes" 0 "No" ;
VAL_ 131 CcAslButtnCnclResPress 1 "Button_Pressed" 0 "Button_Not_Pressed" ;
VAL_ 131 CcAslButtnCnclPress 1 "Button_Pressed" 0 "Button_Not_Pressed" ;
VAL_ 131 LaSwtchPos_D_Stat 3 "Fault" 2 "Unused" 1 "Pressed" 0 "Open" ;
VAL_ 953 ChrgCordLck_B_Stat 1 "Unlock" 0 "Null" ;
VAL_ 953 WakeAlarm3_D_Stat 3 "PublisherReset" 2 "Wake" 1 "AlarmRunning" 0 "AlarmOff" ;
VAL_ 953 WakeAlarm2_D_Stat 3 "PublisherReset" 2 "Wake" 1 "AlarmRunning" 0 "AlarmOff" ;
VAL_ 953 WakeAlarm1_D_Stat 3 "PublisherReset" 2 "Wake" 1 "AlarmRunning" 0 "AlarmOff" ;
VAL_ 953 WakeAlarm0_D_Stat 3 "PublisherReset" 2 "Wake" 1 "AlarmRunning" 0 "AlarmOff" ;
VAL_ 1093 TrlBrkInitOut_D_Stat 3 "Heavy" 2 "Medium" 1 "Light" 0 "Null" ;
VAL_ 1093 TrlrBrkMde_D_Actl 1 "Electric_Over_Hydraulic" 0 "Electric" ;
VAL_ 1093 TrlrBrkDsply_B_Rq 1 "Yes" 0 "No" ;
VAL_ 1093 TrlrBrkDcnnt_B_Actl 1 "Yes" 0 "No" ;
VAL_ 1093 TrlrBrkActCnnct_B_Actl 1 "Yes" 0 "No" ;
VAL_ 1093 StopLamp_B_RqTrlrBrk 1 "Yes" 0 "No" ;
VAL_ 1093 TrlrBrkCtl_B_Falt 1 "Yes" 0 "No" ;
VAL_ 1093 TrlrBrkActCirct_B_Falt 1 "Yes" 0 "No" ;
VAL_ 792 DsplyChkActv_B_Stat 1 "Active" 0 "Inactive" ;
VAL_ 792 ElTrip_L_Dsply 65535 "Fault" 65534 "No_Data_Exists" ;
VAL_ 792 ElLongTerm_L_Dsply 16777215 "Fault" 16777214 "No_Data_Exists" ;
VAL_ 968 RvltnMatchAllw_D_Rq 3 "RevolutionMatchDisabled" 2 "RevolutionMatchEnabled" 1 "ChangeWithDriveMode" 0 "NoSelection" ;
VAL_ 968 BrkDrvMde_D_Rq 7 "Faulty" 6 "RockCrawl" 5 "Baja" 4 "DragOrMudAndSand" 3 "Track" 2 "Snow_Wet" 1 "Sport" 0 "Normal" ;
VAL_ 968 LnchCtl_D_Rq 3 "NotUsed2" 2 "NotUsed1" 1 "LC_On" 0 "LC_Off" ;
VAL_ 968 CurrentColor_CmdGage 15 "NotUsed7" 14 "NotUsed6" 13 "NotUsed5" 12 "NotUsed4" 11 "NotUsed3" 10 "NotUsed2" 9 "NotUsed1" 8 "Null" 7 "Color7" 6 "Color6" 5 "Color5" 4 "Color4" 3 "Color3" 2 "Color2" 1 "Color1" 0 "Off" ;
VAL_ 968 BlendedColor_CmdGage 3 "NotUsed" 2 "Null" 1 "On" 0 "Off" ;
VAL_ 968 BlendColorRed_CmdGage 15 "NotUsed10" 14 "NotUsed9" 13 "NotUsed8" 12 "NotUsed7" 11 "NotUsed6" 10 "NotUsed5" 9 "NotUsed4" 8 "NotUsed3" 7 "NotUsed2" 6 "NotUsed1" 5 "_5" 4 "_4" 3 "_3" 2 "_2" 1 "_1" 0 "Null" ;
VAL_ 968 BlendColorGrn_CmdGage 15 "NotUsed10" 14 "NotUsed9" 13 "NotUsed8" 12 "NotUsed7" 11 "NotUsed6" 10 "NotUsed5" 9 "NotUsed4" 8 "NotUsed3" 7 "NotUsed2" 6 "NotUsed1" 5 "_5" 4 "_4" 3 "_3" 2 "_2" 1 "_1" 0 "Null" ;
VAL_ 968 BlendColorBlue_CmdGage 15 "NotUsed10" 14 "NotUsed9" 13 "NotUsed8" 12 "NotUsed7" 11 "NotUsed6" 10 "NotUsed5" 9 "NotUsed4" 8 "NotUsed3" 7 "NotUsed2" 6 "NotUsed1" 5 "_5" 4 "_4" 3 "_3" 2 "_2" 1 "_1" 0 "Null" ;
VAL_ 968 Dimming_Level_Cmd 3 "Low" 2 "Not_Used" 1 "High" 0 "Null" ;
VAL_ 968 Current_Color_Cmd 15 "NotUsed7" 14 "NotUsed6" 13 "NotUsed5" 12 "NotUsed4" 11 "NotUsed3" 10 "NotUsed2" 9 "NotUsed1" 8 "Null" 7 "Color7" 6 "Color6" 5 "Color5" 4 "Color4" 3 "Color3" 2 "Color2" 1 "Color1" 0 "Off" ;
VAL_ 968 BlendedColorRed_Cmd 15 "NotUsed10" 14 "NotUsed9" 13 "NotUsed8" 12 "NotUsed7" 11 "NotUsed6" 10 "NotUsed5" 9 "NotUsed4" 8 "NotUsed3" 7 "NotUsed2" 6 "NotUsed1" 5 "_5" 4 "_4" 3 "_3" 2 "_2" 1 "_1" 0 "Null" ;
VAL_ 968 BlendedColorGreen_Cmd 15 "NotUsed10" 14 "NotUsed9" 13 "NotUsed8" 12 "NotUsed7" 11 "NotUsed6" 10 "NotUsed5" 9 "NotUsed4" 8 "NotUsed3" 7 "NotUsed2" 6 "NotUsed1" 5 "_5" 4 "_4" 3 "_3" 2 "_2" 1 "_1" 0 "Null" ;
VAL_ 968 BlendedColorBlue_Cmd 15 "NotUsed10" 14 "NotUsed9" 13 "NotUsed8" 12 "NotUsed7" 11 "NotUsed6" 10 "NotUsed5" 9 "NotUsed4" 8 "NotUsed3" 7 "NotUsed2" 6 "NotUsed1" 5 "_5" 4 "_4" 3 "_3" 2 "_2" 1 "_1" 0 "Null" ;
VAL_ 968 BlendedColor_Cmd 3 "NotUsed" 2 "Null" 1 "On" 0 "Off" ;
VAL_ 968 SuspDrvMde_D_Rq 7 "Faulty" 6 "NotUsed2" 5 "NotUsed1" 4 "Drag" 3 "Track" 2 "Snow_Wet" 1 "Sport" 0 "Normal" ;
VAL_ 968 SlMde_D_Rq 3 "IsaNotConfigured" 2 "Manual_Mode" 1 "Auto_Mode" 0 "Null" ;
VAL_ 968 IsaOffst_D_Rq 15 "Faulty" 14 "Null" 13 "Thirteen" 12 "Twelve" 11 "Eleven" 10 "Ten" 9 "Nine" 8 "Eight" 7 "Seven" 6 "Six" 5 "Five" 4 "Four" 3 "Three" 2 "Two" 1 "One" 0 "Zero" ;
VAL_ 819 WndwUpPsngrRear_D_Falt 3 "NotUsed" 2 "Fault" 1 "NoFault" 0 "Null" ;
VAL_ 819 WndwUpPsngrFront_D_Falt 3 "NotUsed" 2 "Fault" 1 "NoFault" 0 "Null" ;
VAL_ 819 Memory_3_SwPsngr_Stat 1 "Pressed" 0 "Null" ;
VAL_ 819 Memory_2_SwPsngr_Stat 1 "Pressed" 0 "Null" ;
VAL_ 819 Memory_1_SwPsngr_Stat 1 "Pressed" 0 "Null" ;
VAL_ 819 BLISLEDStatPassSide 3 "Fault" 2 "Unused" 1 "On" 0 "Off" ;
VAL_ 819 WndwPsngrSide_D_Stat 3 "BothWindow_Operating" 2 "RearWindow_Operating" 1 "FrontWindow_Operating" 0 "NoWindows_Operating" ;
VAL_ 819 Pasngr_Lock_Sw_Stat 3 "Invalid" 2 "Unlock" 1 "Lock" 0 "Null" ;
VAL_ 819 ChildLckFdbckRp_B_Stat 1 "Locked" 0 "Unlock" ;
VAL_ 818 WndwUpDrvRear_D_Falt 3 "NotUsed" 2 "Fault" 1 "NoFault" 0 "Null" ;
VAL_ 818 WndwUpDrvFront_D_Falt 3 "NotUsed" 2 "Fault" 1 "NoFault" 0 "Null" ;
VAL_ 818 BLISLEDStatDriverSide 3 "Fault" 2 "Unused" 1 "On" 0 "Off" ;
VAL_ 818 WndwDrvSide_D_Stat 3 "BothWindow_Operating" 2 "RearWindow_Operating" 1 "FrontWindow_Operating" 0 "NoWindows_Operating" ;
VAL_ 818 KeyCylSwDrvDr_D_Stat 3 "NotUsed" 2 "Unlock" 1 "Lock" 0 "Null" ;
VAL_ 818 Driver_Lock_Sw_Stat 3 "Invalid" 2 "Unlock" 1 "Lock" 0 "Null" ;
VAL_ 818 ChildLckPw_D_Rq 1 "Active" 0 "Null" ;
VAL_ 818 ChildLckFdbckRd_B_Stat 1 "Locked" 0 "Unlock" ;
VAL_ 818 RvrseMirrorChime_B_Rq 1 "Yes" 0 "No" ;
VAL_ 806 ClimtCoolRear_B_Rq 1 "On" 0 "Off" ;
VAL_ 806 ClimtHeatRear_D_Rq 7 "NotUsed4" 6 "NotUsed3" 5 "NotUsed2" 4 "PtcHtrTestMde" 3 "Defrost_Defog" 2 "FastTempPullDownHeatingReq" 1 "OpportunisticHeatingReq" 0 "NoHeatingRequest" ;
VAL_ 806 SnowPlowMde_B_Enbl 1 "Enable" 0 "Disable" ;
VAL_ 806 ClimtDeltaLoad_Pw_Actl 63 "Faulty" 62 "NoDataExists" ;
VAL_ 806 StopStrtDrvMde_B_RqBtn 1 "Pressed" 0 "Not_Pressed" ;
VAL_ 806 WndwFrontHeat_B_Stat 1 "On" 0 "Off" ;
VAL_ 806 HtrCorePump_B_Rq 1 "On" 0 "Off" ;
VAL_ 806 ClimtHeat_D_Rq 7 "NotUsed4" 6 "NotUsed3" 5 "NotUsed2" 4 "PtcHtrTestMde" 3 "Defrost_Defog" 2 "FastTempPullDownHeatingReq" 1 "OpportunisticHeatingReq" 0 "NoHeatingRequest" ;
VAL_ 806 ClimtCool_D_Rq 7 "NotUsed4" 6 "NotUsed3" 5 "NotUsed2" 4 "ElACTestMde" 3 "Defrost_Defog" 2 "FastTempPullDownCoolReq" 1 "OpportunisticCoolingReq" 0 "NoCoolingRequest" ;
VAL_ 806 HvacEvap_Te_Actl 1023 "Fault" ;
VAL_ 806 HvacAirCond_B_Rq 1 "Yes" 0 "No" ;
VAL_ 806 ClimtPw_B_Rq 1 "Yes" 0 "No" ;
VAL_ 765 BalrSwtch_D_Stat 3 "NotUsed" 2 "Pressed" 1 "NotPressed" 0 "Null" ;
VAL_ 765 BalrMde_D_Rq 3 "High" 2 "Medium" 1 "Low" 0 "Null" ;
VAL_ 765 RstrnOnPsngr_D_RqMnu 15 "Faulty" 14 "NotUsed_11" 13 "NotUsed_10" 12 "ConfiguredOff" 11 "NotUsed_9" 10 "On" 9 "NotUsed_8" 8 "NotUsed_7" 7 "NotUsed_6" 6 "NotUsed_5" 5 "Off" 4 "NotUsed_4" 3 "NotUsed_3" 2 "NotUsed_2" 1 "NotUsed_1" 0 "NoAction" ;
VAL_ 765 WaitToStartLamp_D_Falt 3 "NotUsed" 2 "Wait_to_start_lamp_failed" 1 "Diagnosis_not_ready" 0 "Wait_to_start_lamp_OK" ;
VAL_ 765 EsaOn_B_Rq 1 "On" 0 "Off" ;
VAL_ 765 BttOn_B_Rq 1 "On" 0 "Off" ;
VAL_ 765 Btt_L_Actl 127 "Faulty" 126 "NoDataExists" ;
VAL_ 765 RearDiffLck_D_RqArb 3 "Faulty" 2 "NotUsed" 1 "On" 0 "Off" ;
VAL_ 765 AwdMde_D_RqArb 7 "Faulty" 6 "NotUsed2" 5 "NoRequest" 4 "Neutral" 3 "FourByFourLow" 2 "FourByFourHigh" 1 "FourByFourAuto" 0 "FourByTwo" ;
VAL_ 765 SelDrvMdeTxtReset_B_Rq 1 "Yes" 0 "No" ;
VAL_ 765 AutoTowAllw_D_RqMnu 3 "TowHaulCommandedOn" 2 "AutoTowHaulEnabled" 1 "AutoTowHaulDisabled" 0 "NoSelection" ;
VAL_ 765 DrvInputRequired_B_Rq 1 "Yes" 0 "No" ;
VAL_ 765 SelDrvMdeDsply_B_Avail 1 "Available" 0 "NotAvailable" ;
VAL_ 765 EngExhMdeQuiet_D_Rq 3 "Faulty" 2 "QuietExhaust" 1 "LoudExhaust" 0 "Null" ;
VAL_ 765 AirSusp_D_RqDrv 3 "NotUsed" 2 "On" 1 "Off" 0 "NoModeSelected" ;
VAL_ 765 Mc_VehUntTrpCoUsrSel_St 0 "TripComputer_metric" 1 "TripComputer_imperial" ;
VAL_ 765 Mc_VehUnitTempUsrSel_St 0 "Temperature_deg_c" 1 "Temperature_deg_f" ;
VAL_ 765 Mc_VehDayNightUsrSel_St 2 "Night" 1 "Day" 0 "Invalid" ;
VAL_ 765 Mc_VehTimeFrmtUsrSel_St 2 "24h_mode" 1 "12h_mode" 0 "Invalid" ;
VAL_ 765 Mc_VehThemeUsrSel_St 2 "Theme_2" 1 "Theme_1" 0 "Invalid" ;
VAL_ 765 Mc_VehLangUsrSel_St 30 "Slovak" 29 "Arabic" 28 "Cantonese" 27 "Mandarin_Chinese" 26 "Korean" 25 "Japanese_Kanji" 24 "Japanese_Katakana" 23 "Braz_Portuguese" 22 "EU_Portuguese" 21 "Finish" 20 "Norwegian" 19 "Danish" 18 "Swedish" 17 "Hungarian" 16 "Greek" 15 "Czech" 14 "Polish" 13 "Flemish" 12 "Dutch" 11 "Russian" 10 "Turkish" 9 "Mex_Spanish" 8 "EU_Spanish" 7 "Cana_French" 6 "EU_French" 5 "Italian" 4 "German" 3 "NA_English" 2 "UK_English" 1 "Unknown" 0 "Invalid" ;
VAL_ 765 AwdRnge_D_ActlIpc 7 "Unknown" 6 "High_Range_2wd" 5 "High_Range_Auto" 4 "High_Range_Locked" 3 "Neutral" 2 "Low_Range_2wd" 1 "Low_Range_Auto" 0 "Low_Range_Locked" ;
VAL_ 765 AwdDrvMde_D_Rq 7 "Faulty" 6 "NotAvailable" 5 "RockCrawl" 4 "Baja" 3 "MudAndSand" 2 "Weather" 1 "Sport" 0 "Normal" ;
VAL_ 765 EngExhMdeQuiet_D2_Rq 7 "NotUsed_3" 6 "NotUsed_2" 5 "NotUsed_1" 4 "Track" 3 "Sport" 2 "Normal" 1 "Stealth" 0 "Null" ;
VAL_ 765 BrkLineLck_D_Rq 3 "Off" 2 "Engage" 1 "Initiate" 0 "NoRequest" ;
VAL_ 765 EdmSailMde_B_RqDrv 1 "On" 0 "Off" ;
VAL_ 765 Running_Board_Cmd 3 "Unused" 2 "Manually_Deployed" 1 "All_Enabled" 0 "All_Disabled" ;
VAL_ 934 RbaCtaLeft_D_Stat 7 "Faulty" 6 "NotUsed_2" 5 "NotUsed_1" 4 "Invalid" 3 "Disabled" 2 "On" 1 "Trailer_Tow_Off" 0 "Off" ;
VAL_ 934 CtaAlrtLeft2_D_Stat 7 "NotUsed3" 6 "NotUsed2" 5 "NotUsed1" 4 "AlertZone4" 3 "AlertZone3" 2 "AlertZone2" 1 "AlertZone1" 0 "Off" ;
VAL_ 934 CtaBrkLeftMsgTxt_B_Rq 1 "Enable" 0 "Disable" ;
VAL_ 934 CtaLeftBrkDecel_B_Rq 1 "Enable" 0 "Disable" ;
VAL_ 934 CtaLeftBrkEnbl_B_Rq 1 "Enable" 0 "Disable" ;
VAL_ 934 BttLeft_D_Stat 7 "NotUsed" 6 "Disabled" 5 "Off" 4 "OffTemp" 3 "NotConnected" 2 "Pending" 1 "Connected" 0 "NotDetermined" ;
VAL_ 934 BttLeft_D_RqDrv 3 "NotUsed" 2 "Request" 1 "NoRequest" 0 "Null" ;
VAL_ 934 CtaInnrLeft_D_Stat 3 "Reporting" 2 "Not_Reporting" 1 "System_Standby" 0 "Initialization" ;
VAL_ 934 LcwaLeft_D_Stat 7 "Faulty" 6 "NotUsed_3" 5 "NotUsed_2" 4 "NotUsed_1" 3 "Disabled" 2 "TemporaryUnavailable" 1 "SensorBlocked" 0 "Available" ;
VAL_ 934 CtaSnsLeft_D_Stat 3 "Invalid" 2 "System_Failure" 1 "Blocked" 0 "Clear" ;
VAL_ 934 SodDetctLeft_D_Stat 4 "Sensor_Blocked" 3 "Sensor_Fault" 2 "Flash_On" 1 "Alert_On" 0 "AlertOff_FlashOff_SensrClr" ;
VAL_ 934 CtaLeft_D_Stat 7 "NotUsed_3" 6 "NotUsed_2" 5 "NotUsed_1" 4 "Invalid" 3 "Disabled" 2 "On" 1 "Trailer_Tow_Off" 0 "Off" ;
VAL_ 934 CtaAlrtLeft_D_Stat 1 "On" 0 "Off" ;
VAL_ 934 SodLeft_D_Stat 7 "NotUsed_3" 6 "NotUsed_2" 5 "NotUsed_1" 4 "Invalid" 3 "Disabled" 2 "On" 1 "Trailer_Tow_Off" 0 "Off" ;
VAL_ 934 SodSnsLeft_D_Stat 3 "Second_Warning_Audio" 2 "System_Failure" 1 "Blocked" 0 "Clear" ;
VAL_ 934 SodAlrtLeft_D_Stat 3 "Bulb_Proveout" 2 "Flash" 1 "On" 0 "Off" ;
VAL_ 934 SodInnrLeft_D_Stat 3 "Reporting" 2 "Not_Reporting" 1 "System_Standby" 0 "Initialization" ;
VAL_ 934 LcwaDetctLeft2_B_Stat 1 "Yes" 0 "No" ;
VAL_ 934 LcwaDetctLeft1_B_Stat 1 "Yes" 0 "No" ;
VAL_ 1072 PtDrvMde_D_Rq 15 "Faulty" 14 "NotUsed11" 13 "NotUsed10" 12 "NotUsed9" 11 "NotUsed8" 10 "NotUsed7" 9 "NotUsed6" 8 "NotUsed5" 7 "Drag" 6 "Rock" 5 "Baja" 4 "Sand" 3 "TowHaulGradeAssist" 2 "SnowWet" 1 "Sport" 0 "Normal" ;
VAL_ 1072 DrvSlipCtlMde_D_Rq 3 "App_Specific_Off_Mode_3" 2 "App_Specific_Off_Mode_2" 1 "App_Specific_Off_Mode_1" 0 "Default_Mode" ;
VAL_ 1072 EngIdlShutDown_B_RqDrv 1 "Inhibit" 0 "No_Inibit" ;
VAL_ 1072 DrvPerfMde_D_Rq 3 "Sport" 2 "Normal" 1 "NotUsed" 0 "NoModeSelected" ;
VAL_ 1072 HsaMde_D_Rq 3 "Undefined" 2 "Manual" 1 "Automatic" 0 "Off" ;
VAL_ 1072 StopStrtDrvMde_D_RqMnu 3 "NotUsed2" 2 "NotUsed1" 1 "StopStart_Deselected" 0 "StopStart_Selected" ;
VAL_ 1072 NtrlTowMdeEnbl_B_RqDrv 1 "Yes" 0 "No" ;
VAL_ 1072 LscmbbStat_B_Actl 1 "On" 0 "Off" ;
VAL_ 1072 BulbChkActv_B_Stat 1 "Active" 0 "Inactive" ;
VAL_ 1072 ParkDetect_Stat 1 "Park" 0 "Not_Park" ;
VAL_ 1072 ReducedGuard_D_Rq 3 "NotUsed" 2 "On" 1 "Off" 0 "Null" ;
VAL_ 1072 FrostWarn_D_Stat 3 "NotUsed" 2 "On_Amber" 1 "On_Red" 0 "Off" ;
VAL_ 1072 TrlrBrkMde_D_Rq 1 "ElectricOverHydraulic" 0 "Electric" ;
VAL_ 1072 TRLR_SWAY_CONFIG_CMD 1 "On" 0 "Off" ;
VAL_ 1072 TRAILER_BRAKE_CONFIG 1 "Yes" 0 "No" ;
VAL_ 1072 Power_Liftgate_Mode_Cmd 1 "Enable" 0 "Disable" ;
VAL_ 1072 AccEnbl_B_RqDrv 1 "Adaptive_Cruise" 0 "Normal_Cruise" ;
VAL_ 1072 EmgcyCallAsstMykey_Rq 1 "On" 0 "Off" ;
VAL_ 1072 OdometerMasterValue 16777215 "Invalid" ;
VAL_ 1072 EngOilLife_B_RqReset 1 "Yes" 0 "No" ;
VAL_ 1072 MetricActvTe_B_Actl 1 "Active" 0 "Inactive" ;
VAL_ 1072 AccDeny_B_RqIpc 1 "Yes" 0 "No" ;
VAL_ 1072 ePRNDL_MODE 1 "On" 0 "Off" ;
VAL_ 1072 PrkLckCtlEnbl_D_RqIpc 3 "Rq_Towing" 2 "Rq_Enable" 1 "Rq_Disable" 0 "Null" ;
VAL_ 1072 DrvSlipCtlMde_B_Rq2 1 "Pressed" 0 "Not_Pressed" ;
VAL_ 1072 Fda_B_Stat 1 "On" 0 "Off" ;
VAL_ 1072 MetricActv_B_Actl 1 "Active" 0 "Inactive" ;
VAL_ 1072 KeyTypeChngMykey_D_Rq 3 "Search_PE_BackupSlot" 2 "Clear_All_MyKeys" 1 "Request_New_MyKey" 0 "None" ;
VAL_ 1072 ManRgen_D_Rq 3 "NotUsed2" 2 "NotUsed1" 1 "CustInitManExhFilterClean" 0 "No_Customer_Request" ;
VAL_ 909 IgnPsswrdDsply_B_Rq 1 "Active" 0 "Inactive" ;
VAL_ 909 ElPwPoint_D_Rq 3 "On" 2 "Off2" 1 "Off1" 0 "Null" ;
VAL_ 909 PoliceIdlMde_D_Stat 15 "NotUsed_7" 14 "NotUsed_6" 13 "NotUsed_5" 12 "NotUsed_4" 11 "NotUsed_3" 10 "NotUsed_2" 9 "PepsActive" 8 "Decommissioned" 7 "ActiveFault" 6 "ArmFault" 5 "PrearmedFault" 4 "OffFault" 3 "Active" 2 "Arm" 1 "Prearmed" 0 "Off" ;
VAL_ 909 DrLatchMsgTxt_D_Rq 7 "Message7" 6 "Message6" 5 "Message5" 4 "Message4" 3 "Message3" 2 "Message2" 1 "Message1" 0 "NoMessage" ;
VAL_ 909 SecurityMsgTxt_D_Rq 3 "Message3" 2 "Message2" 1 "Message1" 0 "NoMessage" ;
VAL_ 909 PrmtrAlrmEvnt_D_Stat 15 "Diag_Tamper" 14 "Trailer" 13 "Shock_Sensor" 12 "Post_Crash" 11 "Panic" 10 "Intrusion" 9 "Inclination" 8 "Ign_Tamper" 7 "LG_Door" 6 "Decklid" 5 "Hood" 4 "PR_Door" 3 "PF_Door" 2 "DR_Door" 1 "DF_Door" 0 "Null" ;
VAL_ 909 HeadLghtHiPrmsn_D_Stat 3 "CancelAndSuppress" 2 "Cancel" 1 "Hold" 0 "AllowChange" ;
VAL_ 909 SteWhlLckMsgTxt_D_Rq 3 "NotUsed" 2 "Message_2" 1 "Message_1" 0 "No_Message" ;
VAL_ 909 immoMsgTxt_D_Rq 15 "Immo_Msg_15" 14 "Immo_Msg_14" 13 "Immo_Msg_13" 12 "Immo_Msg_12" 11 "Immo_Msg_11" 10 "Immo_Msg_10" 9 "Immo_Msg_9" 8 "Immo_Msg_8" 7 "Immo_Msg_7" 6 "Immo_Msg_6" 5 "Immo_Msg_5" 4 "Immo_Msg_4" 3 "Immo_Msg_3" 2 "Immo_Msg_2" 1 "Immo_Msg_1" 0 "Immo_Msg_0_Null" ;
VAL_ 909 PrsnlDevcChrgEnbl_B_Rq 1 "Active" 0 "Inactive" ;
VAL_ 909 TracKeyMde_D_Stat 3 "NotUsed" 2 "NotActive" 1 "Active" 0 "ModeNotDetermined" ;
VAL_ 909 PEBackupSlot_Stats 3 "No_Valid_FOB_In_Slot" 2 "MyKey_FOB_In_Slot" 1 "Standard_FOB_In_Slot" 0 "Null" ;
VAL_ 909 KeyMykeyTot_No_Cnt 13 "Thirteen" 12 "Twelve" 11 "Eleven" 10 "Ten" 9 "Nine" 8 "Eight" 7 "Seven" 6 "Six" 5 "Five" 4 "Four" 3 "Three" 2 "Two" 1 "One" 0 "Zero" 15 "Invalid" 14 "Unlimited" ;
VAL_ 909 KeyAdmnTot_No_Cnt 13 "Thirteen" 12 "Twelve" 11 "Eleven" 10 "Ten" 9 "Nine" 8 "Eight" 7 "Seven" 6 "Six" 5 "Five" 4 "Four" 3 "Three" 2 "Two" 1 "One" 0 "Zero" 15 "Invalid" 14 "Unlimited" ;
VAL_ 963 Illuminated_Entry_Stat 3 "Invalid" 2 "Unknown" 1 "On" 0 "Off" ;
VAL_ 963 Dr_Courtesy_Light_Stat 3 "Invalid" 2 "Unknown" 1 "On" 0 "Off" ;
VAL_ 963 Courtesy_Delay_Status 3 "Invalid" 2 "Unknown" 1 "On" 0 "Off" ;
VAL_ 963 ImpactEvntFdbck_D_Stat 3 "NotUsed" 2 "EventComplete" 1 "EventInProgress" 0 "Normal" ;
VAL_ 963 WrlssAcsyChrgInhbt_B_Rq 1 "Yes" 0 "No" ;
VAL_ 963 PudLampPsngr_D_Rq 3 "Ramp_Down" 2 "Ramp_Up" 1 "On" 0 "Off" ;
VAL_ 963 HeadLampLoOut_B_Stat 1 "Out" 0 "Null" ;
VAL_ 963 HeadLghtHiFdbck_D_Stat 3 "NotUsed" 2 "Cancel" 1 "Hold" 0 "Allow_Change" ;
VAL_ 963 PudLampDrv_D_Rq 3 "Ramp_Down" 2 "Ramp_Up" 1 "On" 0 "Off" ;
VAL_ 963 TrnNotInPrkChime_B_Rq 1 "On" 0 "Off" ;
VAL_ 963 PrkLightChime_B_Rq 1 "On" 0 "Off" ;
VAL_ 963 KeyInIgnWarn_B_Cmd 1 "On" 0 "Off" ;
VAL_ 963 HomeSafeLtChime_B_Rq 1 "On" 0 "Off" ;
VAL_ 963 StopLghtOn_B_Stat 1 "On" 0 "Off" ;
VAL_ 963 RvrseLghtOn_B_Stat 1 "On" 0 "Off" ;
VAL_ 963 PrkLght_D_Stat 3 "Park_Both" 2 "Park_Right" 1 "Park_Left" 0 "Off" ;
VAL_ 963 HeadLghtSwtch_D_Stat 3 "Autolamp" 2 "Headlamp" 1 "Parklamp" 0 "Off" ;
VAL_ 963 HeadLampLoFrOn_B_Stat 1 "Low" 0 "Not_Low" ;
VAL_ 963 HeadLampLoFlOn_B_Stat 1 "Low" 0 "Not_Low" ;
VAL_ 963 HeadLampLoActv_B_Stat 1 "On" 0 "Off" ;
VAL_ 963 Headlamp_On_Wrning_Cmd 1 "On" 0 "Off" ;
VAL_ 963 Park_Brake_Chime_Rqst 1 "On" 0 "Off" ;
VAL_ 963 HeadLghtHiOn_B_Stat 1 "On" 0 "Off" ;
VAL_ 963 BrkWarnInd_B_Rq 1 "On" 0 "Off" ;
VAL_ 963 Brk_Fluid_Lvl_Low 3 "Invalid" 2 "Unknown" 1 "Low" 0 "OK" ;
VAL_ 963 ReducedGuard_D_Stat 3 "NotUsed" 2 "Alarm_On" 1 "Alarm_Off_Previously_On" 0 "Alarm_Off" ;
VAL_ 963 Perimeter_Alarm_Status 3 "Activated" 2 "Armed" 1 "Prearmed" 0 "Disarmed" ;
VAL_ 963 Courtesy_BSave_Stat 3 "Invalid" 2 "Unknown" 1 "No_Effect" 0 "Off" ;
VAL_ 963 DrTgateLck_D_Stat 3 "NotUsed" 2 "Unlock" 1 "Lock" 0 "Null" ;
VAL_ 963 WndwGlbl_D_Cmd 7 "NotUsed3" 6 "NotUsed2" 5 "NotUsed1" 4 "GLEARN" 3 "GCLOSE" 2 "GOPEN" 1 "GSTOP" 0 "Null" ;
VAL_ 963 PudLamp_D_Rq 3 "RAMP_DOWN" 2 "RAMP_UP" 1 "ON" 0 "OFF" ;
VAL_ 963 DayRnngLampOn_B_Stat 1 "On" 0 "Off" ;
VAL_ 963 PerimeterAlarmChimeRq 1 "On" 0 "Off" ;
VAL_ 145 VehYawWActl_D_Qf 3 "OK" 2 "Not_Within_Specifications" 1 "No_Data_Exists" 0 "Faulty" ;
VAL_ 145 VehRolWActl_D_Qf 3 "OK" 2 "Not_Within_Specifications" 1 "No_Data_Exists" 0 "Faulty" ;
VAL_ 145 VehYaw_W_Actl 65535 "Faulty" 65534 "NoDataExists" ;
VAL_ 145 VehRol_W_Actl 65535 "Faulty" 65534 "NoDataExists" ;
VAL_ 76 RstrnPsngrOn_D_Stat 15 "Faulty" 14 "NotUsed_11" 13 "NotUsed_10" 12 "ConfiguredOff" 11 "NotUsed_9" 10 "On" 9 "NotUsed_8" 8 "NotUsed_7" 7 "NotUsed_6" 6 "NotUsed_5" 5 "Off" 4 "NotUsed_4" 3 "NotUsed_3" 2 "NotUsed_2" 1 "NotUsed_1" 0 "NoAction" ;
VAL_ 76 PsngrFmidDetct_D_Actl 3 "Unknown" 2 "Empty" 1 "Occupied" 0 "Fault" ;
VAL_ 76 FirstRowBuckleMid 3 "Unknown" 2 "Unbelted" 1 "Belted" 0 "Faulty" ;
VAL_ 76 ThirdRowBucklePsngr 3 "Unknown" 2 "Unbelted" 1 "Belted" 0 "Faulty" ;
VAL_ 76 ThirdRowBuckleMid 3 "Unknown" 2 "Unbelted" 1 "Belted" 0 "Faulty" ;
VAL_ 76 ThirdRowBuckleDriver 3 "Unknown" 2 "Unbelted" 1 "Belted" 0 "Faulty" ;
VAL_ 76 SecondRowBucklePsngr 3 "Unknown" 2 "Unbelted" 1 "Belted" 0 "Faulty" ;
VAL_ 76 SecondRowBuckleMid 3 "Unknown" 2 "Unbelted" 1 "Belted" 0 "Faulty" ;
VAL_ 76 SecondRowBuckleDriver 3 "Unknown" 2 "Unbelted" 1 "Belted" 0 "Faulty" ;
VAL_ 76 FirstRowBuckleDriver 3 "Unknown" 2 "Unbelted" 1 "Belted" 0 "Faulty" ;
VAL_ 76 RILReq 3 "Not_Used" 2 "Plant_Mode" 1 "On" 0 "Off" ;
VAL_ 76 FirstRowBucklePsngr 3 "Unknown" 2 "Unbelted" 1 "Belted" 0 "Faulty" ;
VAL_ 76 RstrnImpactEvntStatus 7 "Invalid" 6 "Not_Used_4" 5 "Threshold_2_Exceeded" 4 "Not_Used_3" 3 "Threshold_1_Exceeded" 2 "Not_Used_2" 1 "Not_Used_1" 0 "Normal" ;
VAL_ 76 PsngrFrntDetct_D_Actl 3 "Unknown" 2 "Empty" 0 "Faulty" 1 "Occupied" ;
VAL_ 76 EDRTriggerEvntSync 1 "Threshold_Exceeded" 0 "Normal" ;
VAL_ 76 PassRstrnInd_Req 3 "ABOnNotIllum_OffNotIllum" 2 "AirbagOnNot_Illum_OffIllum" 1 "AirbagOn_Illum_OffNotIllum" 0 "AirbagOn_Illum_Off_Illum" ;
VAL_ 65 immoControlCmd_T1 0 "IDLE" 1 "MOTIVE_START_RQST" 2 "NONMOTIVE_START_RQST" 3 "RQST_TARGET1_IDBLOCK1" 4 "RQST_TARGET1_IDBLOCK2" 5 "Unused" 6 "ECHO_TARGET1_IDBLOCK2" 7 "SHUTDOWN" ;
VAL_ 1076 AutoRgen_D_Rq 3 "NotUsed" 2 "AutExhFilterCleanOFF" 1 "AutExhFilterCleanON" 0 "No_Mode_Selected" ;
VAL_ 1076 W2S_LAMP_OK 1 "Yes" 0 "No" ;
VAL_ 1076 OdoTripRx_B_Actl 1 "Yes" 0 "No" ;
VAL_ 1076 DrvSlipCtlMde_B_RqMyKey 1 "On" 0 "Off" ;
VAL_ 1076 FuelLvlWarn_D_Actl 3 "NotUsed" 2 "VeryLow" 1 "Low" 0 "OK" ;
VAL_ 1076 DieslFuelBio_B_ActlDrv 1 "Biodiesel_User" 0 "Non_Biodiesel_User" ;
VAL_ 1076 FuelSecndActv_B_Actl 1 "Yes" 0 "No" ;
VAL_ 1076 HILL_DESC_SW 1 "On" 0 "Off" ;
VAL_ 1076 FUEL_SENSOR_NUM 1 "Dual_Sensors" 0 "Single_Sensor" ;
VAL_ 1076 TirePReset_B_Rq 1 "Reset" 0 "Null" ;
VAL_ 862 HvacBlwrFront_D_Stat 31 "Not_Used" 20 "Full_On" 19 "95_Percent" 18 "90_Percent" 17 "85_Percent" 16 "80_Percent" 15 "75_Percent" 14 "70_Percent" 13 "65_Percent" 12 "60_Percent" 11 "55_Percent" 10 "50_Percent" 9 "45_Percent" 8 "40_Percent" 7 "35_Percent" 6 "30_Percent" 5 "25_Percent" 4 "20_Percent" 3 "15_Percent" 2 "10_Percent" 1 "5_Percent" 0 "Off" ;
VAL_ 862 HvacBlwrRear_D_Stat 31 "Not_Used" 20 "Full_On" 19 "95_Percent" 18 "90_Percent" 17 "85_Percent" 16 "80_Percent" 15 "75_Percent" 14 "70_Percent" 13 "65_Percent" 12 "60_Percent" 11 "55_Percent" 10 "50_Percent" 9 "45_Percent" 8 "40_Percent" 7 "35_Percent" 6 "30_Percent" 5 "25_Percent" 4 "20_Percent" 3 "15_Percent" 2 "10_Percent" 1 "5_Percent" 0 "Off" ;
VAL_ 862 CabnAmb_Te_Actl 255 "Fault" ;
VAL_ 862 ClimtThrmlLoad_No_Actl 255 "Fault" ;
VAL_ 931 VehOnSrc_D_Stat 15 "NotUsed_11" 14 "NotUsed_10" 13 "NotUsed_9" 12 "NotUsed_8" 11 "NotUsed_7" 10 "NotUsed_6" 9 "NotUsed_5" 8 "NotUsed_4" 7 "NotUsed_3" 6 "NotUsed_2" 5 "NotUsed_1" 4 "OverTheAir" 3 "RemoteParkAssist" 2 "RemoteStart" 1 "Manual" 0 "Off" ;
VAL_ 931 EngStrt_B_Rq 1 "Request" 0 "NoRequest" ;
VAL_ 931 EngStrtActv_B_Stat 1 "Active" 0 "Inactive" ;
VAL_ 931 DrvInCtl_B_Stat 1 "Yes" 0 "No" ;
VAL_ 931 AdvStrt_D_Stat 15 "NotUsed_15" 14 "NotUsed_14" 13 "NotUsed_13" 12 "NotUsed_12" 11 "NotUsed_11" 10 "NotUsed_10" 9 "NotUsed_9" 8 "NotUsed_8" 7 "NotUsed_7" 6 "NotUsed_6" 5 "NotUsed_5" 4 "NotUsed_4" 3 "NotUsed_3" 2 "NotUsed_2" 1 "NotUsed_1" 0 "NoAction" ;
VAL_ 931 CrnkInhbt_B_Stat 1 "Inhibit" 0 "NoInhibit" ;
VAL_ 931 IgnPreOffActv_B_Stat 1 "Active" 0 "Inactive" ;
VAL_ 578 PtLatchActv_B_RqBcm 1 "On" 0 "Off" ;
VAL_ 578 immoSecureIdleMode 3 "NotUsed2" 2 "NotUsed1" 1 "Active" 0 "Inactive" ;
VAL_ 578 ReFuelSwtchStat_D_Actl 3 "NotUsed2" 2 "NotUsed1" 1 "On" 0 "Off" ;
VAL_ 578 FuelPumpPwr_D_Stat 7 "NotUsed3" 6 "NotUsed2" 5 "NotUsed1" 4 "Power_Off_Default" 3 "Power_Off_Command" 2 "Power_Off_Service" 1 "Power_Off_Impact" 0 "Power_On" ;
VAL_ 578 BattULo_U_Actl 255 "Fault" ;
VAL_ 578 PrkLckCtl_B_Enbl 1 "Enable" 0 "Disable" ;
VAL_ 578 PrkLckCtlMsgTxt_D_Rq 3 "BTSI_DI_3" 2 "BTSI_DI_2" 1 "BTSI_DI_1" 0 "Null_BTSI_DI" ;
VAL_ 578 BrkTrnShifLck_B_Stat 1 "Shift" 0 "NoShift" ;
VAL_ 578 PrkLckCtlUnlck_D_Stat 3 "Trans_And_Steer_Unlckd" 2 "Steering_Unlckd" 1 "Transmission_Unlckd" 0 "Null" ;
VAL_ 578 PrkLckCtlTow_B_Enbl 1 "Enable" 0 "Disable" ;
VAL_ 578 DriverCrankingReq 1 "Crank_Request" 0 "No_Crank_Request" ;
VAL_ 578 EngOff_T_Actl 65535 "Invalid" ;
VAL_ 578 DcacElPw_D_Rq 3 "NotUsed" 2 "AC_HighPower_Requested" 1 "AC_LowPower_Requested" 0 "AC_Power_NotRequested" ;
VAL_ 578 BattULo_I_Actl 16383 "Fault" ;
VAL_ 947 ValetMode_D_Mem 1 "On" 0 "Off" ;
VAL_ 947 DrStatDrvErrCnt_B_Stat 1 "Yes" 0 "No" ;
VAL_ 947 TurnLghtRight_D_Rq 3 "Seq" 2 "On" 1 "Off" 0 "Null" ;
VAL_ 947 TurnLghtRightOn_B_Stat 1 "On" 0 "Off" ;
VAL_ 947 TurnLghtLeftOn_B_Stat 1 "On" 0 "Off" ;
VAL_ 947 FogLghtRearOn_B_Stat 1 "On" 0 "Off" ;
VAL_ 947 Backlit_LED_Status 15 "Unused3" 14 "Unused2" 13 "Unused1" 12 "Night_12" 11 "Night_11" 10 "Night_10" 9 "Night_9" 8 "Night_8" 7 "Night_7" 6 "Night_6" 5 "Night_5" 4 "Night_4" 3 "Night_3" 2 "Night_2" 1 "Night_1" 0 "Off" ;
VAL_ 947 TurnLghtLeft_D_Rq 3 "Seq" 2 "On" 1 "Off" 0 "Null" ;
VAL_ 947 FogLghtFrontOn_B_Stat 1 "On" 0 "Off" ;
VAL_ 947 IgnKeyType_D_Actl 15 "Invalid" 14 "Unknown" 3 "Key_Not_Prgrm_Read_Failure" 2 "Key_In_Ign_My_Key" 1 "Key_In_Ign_Standard_Key" 0 "Key_Read_In_Progress" ;
VAL_ 947 Parklamp_Status 3 "Invalid" 2 "Unknown" 1 "On" 0 "Off" ;
VAL_ 947 Litval 255 "Invalid" 254 "Unknown" 5 "Day" 4 "Twilight_4" 3 "Twilight_3" 2 "Twilight_2" 1 "Twilight_1" 0 "Night" ;
VAL_ 947 Key_In_Ignition_Stat 1 "In" 0 "Out" ;
VAL_ 947 Ignition_Status 0 "Unknown" 1 "Off" 15 "Invalid" 8 "Start" 4 "Run" 2 "Accessory" ;
VAL_ 947 Dimming_Lvl 255 "Invalid" 254 "Unknown" 18 "Day_6" 17 "Day_5" 16 "Day_4" 15 "Day_3" 14 "Day_2" 13 "Day_1" 12 "Night_12" 11 "Night_11" 10 "Night_10" 9 "Night_9" 8 "Night_8" 7 "Night_7" 6 "Night_6" 5 "Night_5" 4 "Night_4" 3 "Night_3" 2 "Night_2" 1 "Night_1" 0 "Off" ;
VAL_ 947 Day_Night_Status 3 "NotUsed" 2 "Night" 1 "Day" 0 "Null" ;
VAL_ 947 Remote_Start_Status 3 "Invalid" 2 "Unknown" 1 "Remote" 0 "Null" ;
VAL_ 947 DrStatTgate_B_Actl 1 "Ajar" 0 "Closed" ;
VAL_ 947 DrStatRr_B_Actl 1 "Ajar" 0 "Closed" ;
VAL_ 947 DrStatRl_B_Actl 1 "Ajar" 0 "Closed" ;
VAL_ 947 DrStatPsngr_B_Actl 1 "Ajar" 0 "Closed" ;
VAL_ 947 DrStatInnrTgate_B_Actl 1 "Ajar" 0 "Closed" ;
VAL_ 947 DrStatHood_B_Actl 1 "Ajar" 0 "Closed" ;
VAL_ 947 DrStatDrv_B_Actl 1 "Ajar" 0 "Closed" ;
VAL_ 947 PrkBrkActv_B_Actl 1 "Active" 0 "Inactive" ;
VAL_ 947 LifeCycMde_D_Actl 3 "Transport" 2 "NotUsed" 1 "Factory" 0 "Normal" ;
VAL_ 947 Delay_Accy 1 "On" 0 "Off" ;
VAL_ 947 CrashEvnt_D_Stat 3 "Invalid" 2 "Fuel_Cutoff_Event" 1 "Deploy_Event" 0 "No_Event" ;
VAL_ 947 FuelPmpInhbt_B_Stat 1 "Inhibit" 0 "No_Inibit" ;
VAL_ 947 BodySrvcRqd_B_Rq 1 "Yes" 0 "No" ;
VAL_ 1084 BattULoState_D_Qlty 3 "OK" 2 "Not_Within_Specifications" 1 "Eval_In_Progress" 0 "Fault" ;
VAL_ 1084 BSFault 1 "Fault" 0 "No_Fault" ;
VAL_ 1084 BattULo2_Te_Actl 127 "Fault" ;
VAL_ 1068 EngStrtInhbt_B_RqBatt 1 "Start_Inhibit" 0 "Dont_Care" ;
VAL_ 1068 BattULoChrg_D_Rq 3 "Low_Battery_Temperature" 2 "Charging_Requested" 1 "Chrg_Requested_HighCurrent" 0 "No_Request" ;
VAL_ 1068 PwSysULoFalt_D_Stat 15 "Not_Used_6" 14 "LowBatterySOC" 13 "PSS_Shed2_Contin" 12 "Not_Used_4" 11 "Not_Used_3" 10 "Not_Used_2" 9 "BattMonitoringSensorFault" 8 "LowBattVoltDuringPwSrcOn" 7 "LowBatt2_PowerSaveMode" 6 "LowBatt1_Warning" 5 "Overvoltage" 4 "Fault_NoOutput" 3 "Fault_ReducedOutput" 2 "Fault_Nonspecific" 1 "Cluster_Proveout" 0 "No_Fault" ;
VAL_ 1068 Shed_T_Eng_Off_B 1 "Active" 0 "Inactive" ;
VAL_ 1068 Shed_Feature_Group_ID 16 "PtcHeater" 14 "HtdMirr" 13 "HvacRearBlwr_Third" 12 "HvacRearBlwr_Second" 11 "HvacRearBlwr_First" 31 "All LSHED1 Features" 10 "Htd_Windscrn" 9 "SpltHtdBcklight_HtdMirr" 8 "HtdBcklight_HtdMirr" 7 "HtdCoolSeat_FrtDriver" 6 "HtdCoolSeat_FrtPass" 5 "HtdCoolSeat_RearPass" 4 "HtdCoolSeat_RearDriver" 3 "SmartTrlrTowBattCharge" 2 "Htd_StrWhl" 1 "Htd_Washer_Fluid" 0 "No_LSHED1_Features" 15 "Engine_Coolant_Fan" ;
VAL_ 1068 Shed_Drain_Eng_Off_B 1 "Active" 0 "Inactive" ;
VAL_ 1068 Shed_Level_Req 7 "Unused_2" 6 "Loads_On" 5 "SHED_ENG_OFF" 4 "SOON_ENG_OFF" 3 "SHED2_CONTIN" 2 "SHED2_TRANS" 1 "SHED1" 0 "NO_SHED" ;
VAL_ 1068 ULoRgenTestMde_B_Rq 1 "Request" 0 "NoRequest" ;
VAL_ 1068 ChargeMode 7 "Undefined_2" 6 "Undefined_1" 5 "Battery_Identify" 4 "Battery_Refresh" 3 "SlowRegenAllowNoDischarge" 2 "Fast_Regen_Allowed" 1 "Slow_Regen_Allowed" 0 "Conventional_Charging" ;
VAL_ 1068 IdleSpeedIncrease_El 1 "Yes" 0 "No" ;
VAL_ 1068 Batt_Lo_SoC_B 1 "Active" 0 "Inactive" ;
VAL_ 1068 PeriodicElLoad_B_Stat 1 "Active" 0 "Inactive" ;
VAL_ 1068 Batt_Crit_SoC_B 1 "Active" 0 "Inactive" ;
VAL_ 146 VehVert2_A_Actl 8191 "Faulty" 8190 "NoDataExists" ;
VAL_ 146 VehLong2_A_Actl 8191 "Faulty" 8190 "NoDataExists" ;
VAL_ 146 VehLat2_A_Actl 8191 "Faulty" 8190 "NoDataExists" ;
VAL_ 146 VehVertAActl_D_Qf 3 "OK" 2 "Not_Within_Specifications" 1 "No_Data_Exists" 0 "Faulty" ;
VAL_ 146 VehLongAActl_D_Qf 3 "OK" 2 "Not_Within_Specifications" 1 "No_Data_Exists" 0 "Faulty" ;
VAL_ 146 VehLatAActl_D_Qf 3 "OK" 2 "Not_Within_Specifications" 1 "No_Data_Exists" 0 "Faulty" ;
VAL_ 997 PersIndexCcm_D_Actl 7 "Unused_3" 6 "Unused_2" 5 "Unused_1" 4 "Vehicle" 3 "PERS_4" 2 "PERS_3" 1 "PERS_2" 0 "PERS_1" ;
VAL_ 985 AdbDividedRoad_B_Stat 1 "Yes" 0 "No" ;
VAL_ 985 AdbRampingV_D_Rq 3 "Slow" 2 "Medium" 1 "Fast" 0 "Immediately" ;
VAL_ 985 AdbLampOnOff_D_Rq 3 "BothOn" 2 "LeftOnRightOff" 1 "RightOnLeftOff" 0 "BothOff" ;
VAL_ 985 AdbHiBeamKeepOff_D_Rq 3 "KeepBothOff" 2 "KeepLeftOff" 1 "KeepRightOff" 0 "BothFreeRunning" ;
VAL_ 985 IsaVLimUnit_D_Rq 3 "NoDataExists" 2 "Mph" 1 "Kph" 0 "Null" ;
VAL_ 985 SblmYieldScnr_B_Stat 1 "Yes" 0 "No" ;
VAL_ 985 SblmStopScnr_B_Stat 1 "Yes" 0 "No" ;
VAL_ 985 IsaVLim_D_Rq 252 "NotUsed_2" 250 "LimitSpeed_250" 240 "LimitSpeed_240" 230 "LimitSpeed_230" 220 "LimitSpeed_220" 210 "LimitSpeed_210" 200 "LimitSpeed_200" 190 "LimitSpeed_190" 150 "LimitSpeed_150" 140 "LimitSpeed_140" 130 "LimitSpeed_130" 120 "LimitSpeed_120" 110 "LimitSpeed_110" 100 "LimitSpeed_100" 90 "LimitSpeed_90" 80 "LimitSpeed_80" 70 "LimitSpeed_70" 60 "LimitSpeed_60" 50 "LimitSpeed_50" 40 "LimitSpeed_40" 30 "LimitSpeed_30" 20 "LimtSpeed_20" 251 "NotUsed_1" 255 "Faulty" 254 "NoDataExists" 253 "NotUsed_3" 180 "LimitSpeed_180" 179 "LimitSpeed_179" 178 "LimitSpeed_178" 177 "LimitSpeed_177" 176 "LimitSpeed_176" 175 "LimitSpeed_175" 174 "LimitSpeed_174" 173 "LimitSpeed_173" 172 "LimitSpeed_172" 171 "LimitSpeed_171" 170 "LimitSpeed_170" 169 "LimitSpeed_169" 168 "LimitSpeed_168" 167 "LimitSpeed_167" 166 "LimitSpeed_166" 165 "LimitSpeed_165" 164 "LimitSpeed_164" 163 "LimitSpeed_163" 162 "LimitSpeed_162" 161 "LimitSpeed_161" 160 "LimitSpeed_160" 15 "LimitSpeed_15" 14 "LimitSpeed_14" 13 "LimitSpeed_13" 12 "LimitSpeed_12" 11 "LimitSpeed_11" 10 "LimitSpeed_10" 9 "LimitSpeed_9" 8 "LimitSpeed_8" 7 "LimitSpeed_7" 6 "LimitSpeed_6" 5 "LimitSpeed_5" 4 "LimitSpeed_4" 3 "LimitSpeed_3" 2 "LimitSpeed_2" 1 "LimitSpeed_1" 0 "LimitSpeed_0" ;
VAL_ 985 IaccVLimUnit_D_Rq 3 "NoDataExists" 2 "Mph" 1 "Kph" 0 "Null" ;
VAL_ 985 IaccVLim_D_Rq 252 "NotUsed_2" 250 "LimitSpeed_250" 240 "LimitSpeed_240" 230 "LimitSpeed_230" 220 "LimitSpeed_220" 210 "LimitSpeed_210" 200 "LimitSpeed_200" 190 "LimitSpeed_190" 150 "LimitSpeed_150" 140 "LimitSpeed_140" 130 "LimitSpeed_130" 120 "LimitSpeed_120" 110 "LimitSpeed_110" 100 "LimitSpeed_100" 90 "LimitSpeed_90" 80 "LimitSpeed_80" 70 "LimitSpeed_70" 60 "LimitSpeed_60" 50 "LimitSpeed_50" 40 "LimitSpeed_40" 30 "LimitSpeed_30" 20 "LimtSpeed_20" 251 "NotUsed_1" 255 "Faulty" 254 "NoDataExists" 253 "NotUsed_3" 180 "LimitSpeed_180" 179 "LimitSpeed_179" 178 "LimitSpeed_178" 177 "LimitSpeed_177" 176 "LimitSpeed_176" 175 "LimitSpeed_175" 174 "LimitSpeed_174" 173 "LimitSpeed_173" 172 "LimitSpeed_172" 171 "LimitSpeed_171" 170 "LimitSpeed_170" 169 "LimitSpeed_169" 168 "LimitSpeed_168" 167 "LimitSpeed_167" 166 "LimitSpeed_166" 165 "LimitSpeed_165" 164 "LimitSpeed_164" 163 "LimitSpeed_163" 162 "LimitSpeed_162" 161 "LimitSpeed_161" 160 "LimitSpeed_160" 15 "LimitSpeed_15" 14 "LimitSpeed_14" 13 "LimitSpeed_13" 12 "LimitSpeed_12" 11 "LimitSpeed_11" 10 "LimitSpeed_10" 9 "LimitSpeed_9" 8 "LimitSpeed_8" 7 "LimitSpeed_7" 6 "LimitSpeed_6" 5 "LimitSpeed_5" 4 "LimitSpeed_4" 3 "LimitSpeed_3" 2 "LimitSpeed_2" 1 "LimitSpeed_1" 0 "LimitSpeed_0" ;
VAL_ 985 DasAlrtInfo_D_Dsply 3 "NotUsed" 2 "On" 1 "Off" 0 "Null" ;
VAL_ 985 SblmRndAbtScnr_B_Stat 1 "Yes" 0 "No" ;
VAL_ 984 AhbHiBeam_D_Rq 3 "NotUsed" 2 "HighBeamRecommended" 1 "LowBeamRecommended" 0 "DeactivatedUnavailable" ;
VAL_ 984 CadsCamraStat_D_Qf 3 "OK" 2 "Not_Within_Specifications" 1 "No_Data_Exists" 0 "Faulty" ;
VAL_ 984 AhbcStat_B_Dsply 1 "On" 0 "Off" ;
VAL_ 984 LaSwtch_D_RqDrv 1 "Pressed" 0 "Not_Pressed" ;
VAL_ 984 AhbcHiBeam_D_Rq 3 "Deactivated_Unavailabl" 2 "Unused" 1 "Main_HighBeamRecommend" 0 "Dipped_LowBeamRecommend" ;
VAL_ 984 DasWarn_D_Dsply 3 "Undefined" 2 "Warning_Level_2" 1 "Warning_Level_1" 0 "No_Warning" ;
VAL_ 984 DasStats_D_Dsply 3 "Available" 2 "Unavailable_Other" 1 "Feedback_due_to_Speed" 0 "Off" ;
VAL_ 984 DasAlrtLvl_D_Dsply 5 "Alertness_Level_5" 4 "Alertness_Level_4" 3 "Alertness_Level_3" 2 "Alertness_Level_2" 1 "Alertness_Level_1" 0 "Undefined" ;
VAL_ 984 CamraStats_D_Dsply 3 "FrtCam_TempUnavailOther" 2 "FrtCam_TempUnavailVisibile" 1 "Front_Camera_Service_Reqd" 0 "Front_Camera_OK" ;
VAL_ 984 CamraDefog_B_Req 1 "On" 0 "Off" ;
VAL_ 984 LaHandsOff_D_Dsply 3 "Suppressed" 2 "Level2" 1 "Level1" 0 "HandsOn" ;
VAL_ 984 LaDenyStats_B_Dsply 1 "Unavailable" 0 "Available" ;
VAL_ 984 LaActvStats_D_Dsply 31 "Unused7" 30 "LA_Off" 29 "Unused5" 28 "Unused4" 27 "Unused3" 26 "Unused2" 25 "Unused1" 24 "InerveneLeft_InterveneRght" 23 "WarnLeft_InterveneRight" 22 "SuppressLeft_InterveneRght" 21 "AvailLeft_InterveneRhtt" 20 "NoLeft_InterveneRight" 19 "InterveneLeft_WarnRight" 18 "WarnLeft_WarnRight" 17 "SuppressLeft_WarnRight" 16 "AvailableLeft_WarnRight" 15 "NoLeft_WarnRight" 14 "InterveneLeft_SuppressRght" 13 "WarnLeft_SuppressRight" 12 "SuppressLeft_SuppressRight" 11 "AvailLeft_SuppressRight" 10 "NoLeft_SuppressRight" 9 "InterveneLeft_AvailRight" 8 "WarnLeft_AvailRight" 7 "SuppressLeft_AvailRight" 6 "AvailableLeft_AvailRight" 5 "NoLeft_AvailableRight" 4 "InterveneLeft_NoRight" 3 "WarnLeft_NoRight" 2 "SuppressLeft_NoRight" 1 "AvailableLeft_NoRight" 0 "NoLeft_NoRight" ;
VAL_ 984 AhbcRampingV_D_Rq 3 "Slow" 2 "Medium" 1 "Fast" 0 "Immediately" ;
VAL_ 984 PersIndexIpma_D_Actl 7 "Unused_3" 6 "Unused_2" 5 "Unused_1" 4 "Vehicle" 3 "PERS_4" 2 "PERS_3" 1 "PERS_2" 0 "PERS_1" ;
VAL_ 983 CmbbObjRelLong_V_Actl 1023 "Faulty" 1022 "NoDataExists" ;
VAL_ 983 CmbbObjRelLat_V_Actl 511 "Faulty" 510 "NoDataExists" ;
VAL_ 983 CmbbObjDistLong_L_Actl 1023 "Faulty" 1022 "NoDataExists" ;
VAL_ 983 CmbbObjDistLat_L_Actl 511 "Faulty" 510 "NoDataExists" ;
VAL_ 983 CmbbObjConfdnc_D_Stat 3 "High" 2 "Medium" 1 "Low" 0 "NotDetermined" ;
VAL_ 983 CmbbObjColl_T_Actl 127 "Faulty" 126 "NoDataExists" ;
VAL_ 983 CmbbObjClass_D_Stat 15 "NotUsed_9" 14 "NotUsed_8" 13 "NotUsed_7" 12 "NotUsed_6" 11 "NotUsed_5" 10 "NotUsed_4" 9 "NotUsed_3" 8 "NotUsed_2" 7 "NotUsed_1" 6 "Unclassified_Vehicle" 5 "Bicycle" 4 "Pedestrian" 3 "Truck" 2 "Motorcycle" 1 "Vehicle" 0 "Undetermined" ;
VAL_ 983 EsaEnbl_D2_Rq 3 "NotConfigured" 2 "Enabled" 1 "Pending" 0 "Disabled" ;
VAL_ 980 AdbBrdr1DistRigh_D_Stat 15 "DistGreater800m" 14 "Dist700mTo800m" 13 "Dist600mTo700m" 12 "Dist500mTo600m" 11 "Dist400mTo500m" 10 "Dist300mTo400m" 9 "Dist200mTo300m" 8 "Dist175mTo200m" 7 "Dist150mTo175m" 6 "Dist125mTo150m" 5 "Dist100mTo125m" 4 "Dist75mTo100m" 3 "Dist50mTo75m" 2 "Dist25mTo50m" 1 "Dist15mTo25m" 0 "Dist0mTo15m" ;
VAL_ 980 AdbBrdr1DistLeft_D_Stat 15 "DistGreater800m" 14 "Dist700mTo800m" 13 "Dist600mTo700m" 12 "Dist500mTo600m" 11 "Dist400mTo500m" 10 "Dist300mTo400m" 9 "Dist200mTo300m" 8 "Dist175mTo200m" 7 "Dist150mTo175m" 6 "Dist125mTo150m" 5 "Dist100mTo125m" 4 "Dist75mTo100m" 3 "Dist50mTo75m" 2 "Dist25mTo50m" 1 "Dist15mTo25m" 0 "Dist0mTo15m" ;
VAL_ 980 AdbMde1_D_Rq 3 "MarkerLightFlashing" 2 "MarkerLightConstant" 1 "Spot" 0 "None" ;
VAL_ 980 AdbIntns1_D_Rq 3 "Maximum" 2 "Medium" 1 "Low" 0 "Off" ;
VAL_ 980 AdbBrdr1Up_An_Rq 511 "Faulty" 510 "NoDataExists" ;
VAL_ 980 AdbBrdr1Right_An_Rq 2047 "Faulty" 2046 "NoDataExists" ;
VAL_ 980 AdbBrdr1Low_An_Rq 511 "Faulty" 510 "NoDataExists" ;
VAL_ 980 AdbBrdr1Left_An_Rq 2047 "Faulty" 2046 "NoDataExists" ;
VAL_ 979 HandsOffCnfm_B_Rq 1 "Active" 0 "Inactive" ;
VAL_ 979 LatCtl_D_Rq 7 "NotUsed4" 6 "NotUsed3" 5 "NotUsed2" 4 "NotUsed1" 3 "InterventionRight" 2 "InterventionLeft" 1 "ContinuousPathFollowing" 0 "NoLateralControl" ;
VAL_ 979 LatCtlRampType_D_Rq 3 "Immediately" 2 "Fast" 1 "Medium" 0 "Slow" ;
VAL_ 979 LatCtlPrecision_D_Rq 3 "NotUsed2" 2 "NotUsed1" 1 "Precise" 0 "Comfortable" ;
VAL_ 976 SrpSigValid_B_Stat 1 "True" 0 "False" ;
VAL_ 976 SrpHghtRight_L_Actl 511 "Faulty" 510 "NoDataExists" ;
VAL_ 976 SrpHghtLeft_L_Actl 511 "Faulty" 510 "NoDataExists" ;
VAL_ 976 SrpEventRight_D_Stat 3 "Faulty" 2 "Bump" 1 "Pothole" 0 "NoEvent" ;
VAL_ 976 SrpEventLeft_D_Stat 3 "Faulty" 2 "Bump" 1 "Pothole" 0 "NoEvent" ;
VAL_ 976 SrpDistRight_L_Actl 511 "Faulty" 510 "NoDataExists" ;
VAL_ 976 SrpDistLeft_L_Actl 511 "Faulty" 510 "NoDataExists" ;
VAL_ 973 TsrVl2PrmntMsgTxt_D_Rq 3 "NotUsed" 2 "ShowPermanentlyWithSupp" 1 "ShowPermanentlyWithoutSupp" 0 "DoNotShowSignPermanent" ;
VAL_ 973 TsrVl1PrmntMsgTxt_D_Rq 3 "NotUsed" 2 "ShowPermanentlyWithSupp" 1 "ShowPermanentlyWithoutSupp" 0 "DoNotShowSignPermanent" ;
VAL_ 973 TsrVl2RstrcMsgTxt2_D_Rq 7 "NotUsed" 6 "Time" 5 "Trailer" 4 "Snow" 3 "RainWet" 2 "NoRecognizableRestrictn" 1 "NoSpeedLimitRestrictn" 0 "Null" ;
VAL_ 973 TsrVl1RstrcMsgTxt2_D_Rq 7 "NotUsed" 6 "Time" 5 "Trailer" 4 "Snow" 3 "RainWet" 2 "NoRecognizableRestrictn" 1 "NoSpeedLimitRestrictn" 0 "Null" ;
VAL_ 973 TsrOvtkMsgTxt2_D_Rq 15 "NotUsed5" 14 "NotUsed4" 13 "NotUsed3" 12 "NotUsed2" 11 "NotUsed1" 10 "LimForTrucksCancelled" 9 "LimForTrucksWoQlfdRstrc" 8 "LimForTrucksWithoutRstrc" 7 "LimAllCancelled" 6 "LimAllWithRstrcTime" 5 "LimAllWithRstrcTrailer" 4 "LimAllWithRstrcSnow" 3 "LimAllWithRstrcRain" 2 "LimAllWithoutQlfdRstrc" 1 "LimAllWithoutRestriction" 0 "OvertakingAllowed" ;
VAL_ 973 WwaWarn_B_Rq 1 "On" 0 "Off" ;
VAL_ 973 TsrVlUnitMsgTxt_D_Rq 3 "NoDataExists" 2 "Mph" 1 "Kph" 0 "Null" ;
VAL_ 973 TsrVLim2MsgTxt_D_Rq 255 "NoLimit" 254 "NotUsed2" 253 "NotUsed1" 252 "NotToBeDisplayed" 251 "LimitCancelled" 31 "1F_FA_Message31_250" 30 "Message30" 29 "Message29" 28 "Message28" 27 "Message27" 26 "Message26" 25 "Message25" 24 "Message24" 23 "Message23" 22 "Message22" 21 "Message21" 20 "Message20" 19 "Message19" 18 "Message18" 17 "Message17" 16 "Message16" 15 "Message15" 14 "Message14" 13 "Message13" 12 "Message12" 11 "Message11" 10 "Message10" 9 "Message9" 8 "Message8" 7 "Message7" 6 "Message6" 5 "Message5" 4 "Message4" 3 "Message3" 2 "Message2" 1 "Message1" 0 "Null" ;
VAL_ 973 TsrVLim1MsgTxt_D_Rq 255 "NoLimit" 254 "NotUsed2" 253 "NotUsed1" 252 "NotToBeDisplayed" 251 "LimitCancelled" 31 "1F_FA_Message31_250" 30 "Message30" 29 "Message29" 28 "Message28" 27 "Message27" 26 "Message26" 25 "Message25" 24 "Message24" 23 "Message23" 22 "Message22" 21 "Message21" 20 "Message20" 19 "Message19" 18 "Message18" 17 "Message17" 16 "Message16" 15 "Message15" 14 "Message14" 13 "Message13" 12 "Message12" 11 "Message11" 10 "Message10" 9 "Message9" 8 "Message8" 7 "Message7" 6 "Message6" 5 "Message5" 4 "Message4" 3 "Message3" 2 "Message2" 1 "Message1" 0 "Null" ;
VAL_ 973 TsrVl2TypeMsgTxt_D_Rq 3 "NotUsed" 2 "Explicit" 1 "Implicit" 0 "Null" ;
VAL_ 973 TsrVl2StatMsgTxt_D_Rq 3 "LimitOutdated" 2 "LimitReiable" 1 "LimitChanged" 0 "Null" ;
VAL_ 973 TsrVl2RstrcMsgTxt_D_Rq 3 "NotUsed" 2 "NoRecognizableRestriction" 1 "NoSpeedLimitRestriction" 0 "Null" ;
VAL_ 973 TsrVl1TypeMsgTxt_D_Rq 3 "NotUsed" 2 "Explicit" 1 "Implicit" 0 "Null" ;
VAL_ 973 TsrVl1StatMsgTxt_D_Rq 3 "LimitOutdated" 2 "LimitReiable" 1 "LimitChanged" 0 "Null" ;
VAL_ 973 TsrVl1RstrcMsgTxt_D_Rq 3 "NotUsed" 2 "NoRecognizableRestriction" 1 "NoSpeedLimitRestriction" 0 "Null" ;
VAL_ 973 TsrStatMsgTxt_D_Rq 7 "NotUsed" 6 "NoDataExists" 5 "TSR_Error" 4 "Available_NavigationOnly" 3 "Available_CameraOnly" 2 "Available_FusionMode" 1 "TSR_Off" 0 "Null" ;
VAL_ 973 TsrOvtkTypeMsgTxt_D_Rq 3 "NotUsed" 2 "Explicit" 1 "Implicit" 0 "Null" ;
VAL_ 973 TsrOvtkStatMsgTxt_D_Rq 3 "LimitOutdated" 2 "LimitReiable" 1 "LimitChanged" 0 "Null" ;
VAL_ 973 TsrOvtkMsgTxt_D_Rq 7 "LimForTrucksCancelled" 6 "LimForTrucksWoQlfdRstrc" 5 "LimForTrucksWithoutRstrc" 4 "LimAllCancelled" 3 "LimAllWithoutQlfdRstrc" 2 "LimAllWithoutRestriction" 1 "OvertakingAllowed" 0 "Null" ;
VAL_ 973 TsrOswWarnMsgTxt_D_Rq 3 "NotUsed" 2 "True" 1 "False" 0 "Null" ;
VAL_ 973 TsrMsgTxt_D_Rq 15 "NotUsed6" 14 "NotUsed5" 13 "NotUsed4" 12 "NotUsed3" 11 "NotUsed2" 10 "NotUsed1" 9 "RecgnzdSignNotUsblForDsply" 8 "LimitedSystemPerformance" 7 "OffRoad" 6 "RegionNotSupported" 5 "CountryNotSupported" 4 "WrngNavDatIncompDatCarrier" 3 "NoNavDataAvailable" 2 "NoNavAvailableSwitchedOff" 1 "NoInformationAllOK" 0 "Null" ;
